VERSION ""

NS_ :

BS_:

BU_: SteeringControlModule SteeringController SteeringColumnUnit RearAxleSteeringController Engine ChassisController
VAL_TABLE_ JogSteerStates 15 "UNAVAILABLE" 14 "Reserved" 13 "Reserved" 12 "Reserved" 11 "Reserved" 10 "Reserved" 9 "Reserved" 8 "Reserved" 7 "Reserved" 6 "Reserved" 5 "Reserved" 4 "Reserved" 3 "Clear Jog" 2 "Jog Right" 1 "Jog Left" 0 "NONE" ;
VAL_TABLE_ SteerMode 15 "UNAVAILABLE" 14 "Reserved" 13 "Reserved" 12 "Reserved" 11 "Reserved" 10 "Reserved" 9 "Reserved" 8 "Reserved" 7 "Reserved" 6 "Reserved" 5 "Reserved" 4 "Crab Steer" 3 "4 Wheel Steer" 2 "Auto 4 Wheel Steer" 1 "2 Wheel Steer" 0 "OFF" ;
VAL_TABLE_ FMI 31 "Not available" 19 "Received network data in error" 18 "Below normal (moderately severe)" 17 "Below normal (least severe)" 16 "Above normal (moderately severe)" 15 "Above normal (least severe)" 14 "Special intstructions" 13 "Out of calibration" 12 "Bad intelligent device" 11 "Root cause not known" 10 "Abnormal rate of change" 9 "Abnormal update rate" 8 "Abnormal frequency" 7 "Mechanical system not responding" 6 "Current above normal" 5 "Current below normal" 4 "Voltage below normal" 3 "Voltage above normal" 2 "Data erratic" 1 "Below normal (most severe)" 0 "Above normal (most severe)" ;

BO_ 3221225472 VECTOR__INDEPENDENT_SIG_MSG: 0 Vector__XXX
 SG_ ManufacturerSpecific8 : 0|8@1+ (1,0) [0|255] "" Vector__XXX
 SG_ ManufacturerSpecific7 : 0|8@1+ (1,0) [0|255] "" Vector__XXX
 SG_ ManufacturerSpecific6 : 0|8@1+ (1,0) [0|255] "" Vector__XXX
 SG_ ManufacturerSpecific5 : 0|8@1+ (1,0) [0|255] "" Vector__XXX
 SG_ ManufacturerSpecific4 : 0|8@1+ (1,0) [0|255] "" Vector__XXX
 SG_ ManufacturerSpecific3 : 0|8@1+ (1,0) [0|255] "" Vector__XXX
 SG_ CabNoiseCtrlTuningCmd : 0|3@1+ (1,0) [0|7] "" Vector__XXX
 SG_ CabNoiseCtrlCmd : 0|2@1+ (1,0) [0|3] "" Vector__XXX
 SG_ MagnetGeneratorCtrl : 0|2@1+ (1,0) [0|3] "" Vector__XXX
 SG_ SpecialIgnitorLoop62Resistance : 0|16@1+ (0.1,0) [0|6425.5] "ohm" Vector__XXX
 SG_ EngExhstBckPressRegulatorCtrlCmd : 0|16@1+ (0.0025,0) [0|160.6375] "%" Vector__XXX
 SG_ EngExhaustBackPressActuator1Temp : 0|8@1+ (1,-40) [-40|210] "deg C" Vector__XXX
 SG_ EngExhstBckPrssActtor1DesiredPos : 0|8@1+ (0.4,0) [0|100] "%" Vector__XXX
 SG_ EngTurboWastegateActuator1Temp : 0|8@1+ (1,-40) [-40|210] "deg C" Vector__XXX
 SG_ EngExhstBckPrssRgltrCtrlOprtnStt : 0|4@1+ (1,0) [0|15] "" Vector__XXX
 SG_ EngExhstBckPrssRglatorTempStatus : 0|3@1+ (1,0) [0|7] "" Vector__XXX
 SG_ EngExhstBckPrssRgltrPrlminaryFMI : 0|5@1+ (1,0) [0|31] "" Vector__XXX
 SG_ EngExhaustBackPressRegulatorPos : 0|8@1+ (0.4,0) [0|100] "%" Vector__XXX
 SG_ EngTrbCmprssrBypassActuator2Temp : 0|8@1+ (1,-40) [-40|210] "deg C" Vector__XXX
 SG_ EngTrbCmprssrBypassActuator1Temp : 0|8@1+ (1,-40) [-40|210] "deg C" Vector__XXX
 SG_ EngCoolantPress2 : 0|8@1+ (2,0) [0|500] "kPa" Vector__XXX
 SG_ EngExhstGsRcrcltn2Valve2PosError : 0|16@1+ (0.004,-125) [-125|132.02] "%" Vector__XXX
 SG_ EngExhstGsRcrcltn2Valve1PosError : 0|16@1+ (0.004,-125) [-125|132.02] "%" Vector__XXX
 SG_ DslPrtcltFltr1CndtnsNtMtFrActvRg : 0|2@1+ (1,0) [0|3] "" Vector__XXX
 SG_ DslPrtcltFltrActvRgnrtnInhbt5629 : 0|2@1+ (1,0) [0|3] "" Vector__XXX
 SG_ HydrocarbonDoserPurgingEnable : 0|2@1+ (1,0) [0|3] "" Vector__XXX
 SG_ DslPrtcltFltrActvRgnrtnInhbt3717 : 0|2@1+ (1,0) [0|3] "" Vector__XXX
 SG_ DslPrtcltFltrActvRgnrtnInhbtdDTE : 0|2@1+ (1,0) [0|3] "" Vector__XXX
 SG_ DslPrtcltFltrActvRgnrtnInhbt3715 : 0|2@1+ (1,0) [0|3] "" Vector__XXX
 SG_ DslPrtcltFltrActvRgnrtnInhbt3713 : 0|2@1+ (1,0) [0|3] "" Vector__XXX
 SG_ DslPrtcltFltrActvRgnrtnInhbt3712 : 0|2@1+ (1,0) [0|3] "" Vector__XXX
 SG_ DslPrtcltFltrActvRgnrtnInhbt3710 : 0|2@1+ (1,0) [0|3] "" Vector__XXX
 SG_ DslPrtcltFltrActvRgnrtnInhbtdDTV : 0|2@1+ (1,0) [0|3] "" Vector__XXX
 SG_ DslPrtcltFltrActvRgnrtnInhbtdDTO : 0|2@1+ (1,0) [0|3] "" Vector__XXX
 SG_ DslPrtcltFltr2StSnsrECUIntrnlTmp : 0|8@1+ (1,-40) [-40|210] "deg C" Vector__XXX
 SG_ DslPrtcltFltr1StSnsrECUIntrnlTmp : 0|8@1+ (1,-40) [-40|210] "deg C" Vector__XXX
 SG_ Aftrtrtmnt1SCROprtrIndcmntActvTr : 0|16@1+ (1,0) [0|64255] "km" Vector__XXX
 SG_ Aftrtrtmnt1SCRCnvrsionEfficiency : 0|8@1+ (0.4,0) [0|100] "%" Vector__XXX
 SG_ Aftrtrtmnt1CmmnddDslExhstFldCnsm : 0|16@1+ (0.05,0) [0|3212.75] "L/h" Vector__XXX
 SG_ Aftrtrtmnt1DslExhstFldAvrgCnsmpt : 0|16@1+ (0.05,0) [0|3212.75] "L/h" Vector__XXX
 SG_ TransOilLevel2MeasurementStatus : 0|4@1+ (1,0) [0|15] "" Vector__XXX
 SG_ TransOilLevel2CountdownTimer : 0|4@1+ (1,0) [0|15] "" Vector__XXX
 SG_ TransOilLevel2High_Low : 0|8@1+ (0.5,-62.5) [-62.5|62.5] "L" Vector__XXX
 SG_ TransOilTemp2 : 0|16@1+ (0.03125,-273) [-273|1734.96875] "deg C" Vector__XXX
 SG_ EngIntakeManifold1AbsPress4817 : 0|16@1+ (0.1,0) [0|6425.5] "kPa" Vector__XXX
 SG_ FuelEnergyContent : 0|16@1+ (0.00390625,0) [0|250.996] "MJ/Nm^3" Vector__XXX
 SG_ ReferenceEngGasMassFlowRate : 0|16@1+ (0.05,0) [0|3212.75] "kg/h" Vector__XXX
 SG_ Aftrtrtmnt1DslExhstFluidProperty : 0|4@1+ (1,0) [0|15] "" Vector__XXX
 SG_ Aftrtrtmnt1DslExhstFldCndctivity : 0|8@1+ (5,0) [0|1250] "microSiemens/mm" Vector__XXX
 SG_ Aftrtrtmnt1DslExhstFldCncntrtion : 0|8@1+ (0.25,0) [0|62.5] "%" Vector__XXX
 SG_ Aftrtrtmnt1DselExhaustFluidTemp2 : 0|8@1+ (1,-40) [-40|210] "deg C" Vector__XXX
 SG_ DataSecurityParameter : 0|8@1- (1,0) [0|1785] "" Vector__XXX
 SG_ TrailerVDCActive : 0|2@1+ (1,0) [0|3] "" Vector__XXX
 SG_ TransLoadReductionInhibitRq : 0|2@1+ (1,0) [0|3] "" Vector__XXX
 SG_ ClntLvlEngPrtctionShutdownStatus : 0|2@1+ (1,0) [0|3] "" Vector__XXX
 SG_ ServiceComponentIdentificatio913 : 0|8@1+ (1,0) [0|250] "ID" Vector__XXX
 SG_ ServiceComponentIdentificatio912 : 0|8@1+ (1,0) [0|250] "ID" Vector__XXX
 SG_ EngThrottleValveDiffPress : 0|16@1+ (0.1,0) [0|6425.5] "kPa" Vector__XXX
 SG_ EngFuelCtrlCtrlMode : 0|2@1+ (1,0) [0|3] "" Vector__XXX
 SG_ EmergencyBrakingActive : 0|2@1+ (1,0) [0|3] "" Vector__XXX
 SG_ EngExRangeCoolantPress : 0|8@1+ (4,0) [0|1000] "kPa" Vector__XXX
 SG_ EngCldStrtFlIgniterRelayFeedback : 0|2@1+ (1,0) [0|3] "" Vector__XXX
 SG_ EngColdStartFuelIgniterRelay : 0|2@1+ (1,0) [0|3] "" Vector__XXX
 SG_ EngColdStartFuelIgniterCmd : 0|8@1+ (0.4,0) [0|100] "%" Vector__XXX
 SG_ ParkBrakeCmd : 0|2@1+ (1,0) [0|3] "" Vector__XXX
 SG_ SwtchBcklghtIllmntnBrghtnssPrcnt : 0|8@1+ (0.4,0) [0|100] "%" Vector__XXX
 SG_ Aftrtrtmnt2ThrWyCtlytcCnvrtr4300 : 0|5@1+ (1,0) [0|31] "" Vector__XXX
 SG_ Aftrtrtmnt2ThrWyCtlytcCnvrtr4299 : 0|5@1+ (1,0) [0|31] "" Vector__XXX
 SG_ Aftrtrtmnt2ThrWyCtlytcCnvrtr4298 : 0|5@1+ (1,0) [0|31] "" Vector__XXX
 SG_ NOxSnsrATO2SlfdgnosisFinalResult : 0|8@1+ (1,0) [0|250] "" Vector__XXX
 SG_ Aftrtrtmnt2OtltGsNOxSnsrCrrc5049 : 0|8@1+ (0.5,0) [0|125] "%/bar" Vector__XXX
 SG_ NOxSnsrATO2OperationHoursCounter : 0|16@1+ (1,0) [0|64255] "h" Vector__XXX
 SG_ Aftrtrtmnt2OtltGsNOxSnsrNwPr5047 : 0|8@1+ (1,-125) [-125|125] "ppm" Vector__XXX
 SG_ NOxSnsrATI2SlfdgnosisFinalResult : 0|8@1+ (1,0) [0|250] "" Vector__XXX
 SG_ Aftrtrtmnt2IntkGsNOxSnsrCrrc5042 : 0|8@1+ (0.5,0) [0|125] "%/bar" Vector__XXX
 SG_ NOxSnsrATI2OperationHoursCounter : 0|16@1+ (1,0) [0|64255] "h" Vector__XXX
 SG_ Aftrtrtmnt2IntkGsNOxSnsrNwPr5040 : 0|8@1+ (1,-125) [-125|125] "ppm" Vector__XXX
 SG_ Aftrtrtmnt1ThrWyCtlytcCnvrtr4294 : 0|5@1+ (1,0) [0|31] "" Vector__XXX
 SG_ Aftrtrtmnt1ThrWyCtlytcCnvrtr4293 : 0|5@1+ (1,0) [0|31] "" Vector__XXX
 SG_ Aftrtrtmnt1ThrWyCtlytcCnvrtr4292 : 0|5@1+ (1,0) [0|31] "" Vector__XXX
 SG_ Aftrtrtmnt1DslExhstFldTankHeater : 0|8@1+ (0.4,0) [0|100] "%" Vector__XXX
 SG_ Aftrtrtmnt1DslExhstFldTnkLvlPrlm : 0|5@1+ (1,0) [0|31] "" Vector__XXX
 SG_ Aftrtrtmnt1DslExhstFldTankLevel2 : 0|16@1+ (0.1,0) [0|6425.5] "mm" Vector__XXX
 SG_ Aftrtrtmnt1DslExhstFluidTankTemp : 0|8@1+ (1,-40) [-40|210] "deg C" Vector__XXX
 SG_ Aftrtrtmnt1DslExhstFlidTankLevel : 0|8@1+ (0.4,0) [0|100] "%" Vector__XXX
 SG_ NOxSnsrATO1SlfdgnosisFinalResult : 0|8@1+ (1,0) [0|250] "" Vector__XXX
 SG_ Aftrtrtmnt1OtltGsNOxSnsrCrrc5035 : 0|8@1+ (0.5,0) [0|125] "%/bar" Vector__XXX
 SG_ NOxSnsrATO1OperationHoursCounter : 0|16@1+ (1,0) [0|64255] "h" Vector__XXX
 SG_ Aftrtrtmnt1OtltGsNOxSnsrNwPr5033 : 0|8@1+ (1,-125) [-125|125] "ppm" Vector__XXX
 SG_ NOxSnsrATI1SlfdgnosisFinalResult : 0|8@1+ (1,0) [0|250] "" Vector__XXX
 SG_ Aftrtrtmnt1IntkGsNOxSnsrCrrc5028 : 0|8@1+ (0.5,0) [0|125] "%/bar" Vector__XXX
 SG_ NOxSnsrATI1OperationHoursCounter : 0|16@1+ (1,0) [0|64255] "h" Vector__XXX
 SG_ Aftrtrtmnt1IntkGsNOxSnsrNwPr5026 : 0|8@1+ (1,-125) [-125|125] "ppm" Vector__XXX
 SG_ Armrest2Switch2 : 0|2@1+ (1,0) [0|3] "" Vector__XXX
 SG_ Armrest2Switch1 : 0|2@1+ (1,0) [0|3] "" Vector__XXX
 SG_ Armrest1Switch2 : 0|2@1+ (1,0) [0|3] "" Vector__XXX
 SG_ Armrest1Switch1 : 0|2@1+ (1,0) [0|3] "" Vector__XXX
 SG_ Aftrtrtmnt2SCRCnvrsionEfficiency : 0|8@1+ (0.4,0) [0|100] "%" Vector__XXX
 SG_ Aftrtrtmnt2SCRCmmnddCtlystDslExh : 0|16@1+ (0.05,0) [0|3212.75] "L/h" Vector__XXX
 SG_ Aftrtrtmnt2DslExhstFldAvrgCnsmpt : 0|16@1+ (0.05,0) [0|3212.75] "L/h" Vector__XXX
 SG_ Aftrtrtmnt2DslExhstFldTnk2HtrPrl : 0|5@1+ (1,0) [0|31] "" Vector__XXX
 SG_ Aftrtrtmnt2DslExhstFldTnk2Heater : 0|4@1+ (1,0) [0|15] "" Vector__XXX
 SG_ Aftrtrtmnt2DslExhstFldTnk2TmpPrl : 0|5@1+ (1,0) [0|31] "" Vector__XXX
 SG_ Aftrtrtmnt2DslExhstFldTnk2LvlPrl : 0|5@1+ (1,0) [0|31] "" Vector__XXX
 SG_ Aftrtrtmnt2DslExhstFldTnk2Level2 : 0|16@1+ (0.1,0) [0|6425.5] "mm" Vector__XXX
 SG_ Aftrtrtmnt2DslExhstFlidTank2Temp : 0|8@1+ (1,-40) [-40|210] "deg C" Vector__XXX
 SG_ Aftrtrtmnt2DslExhstFldTank2Level : 0|8@1+ (0.4,0) [0|100] "%" Vector__XXX
 SG_ Aftrtrtmnt2DslExhstFldTnk1HtrPrl : 0|5@1+ (1,0) [0|31] "" Vector__XXX
 SG_ Aftrtrtmnt2DslExhstFldTankHeater : 0|8@1+ (0.4,0) [0|100] "%" Vector__XXX
 SG_ Aftrtrtmnt2DslExhstFldTnk1TmpPrl : 0|5@1+ (1,0) [0|31] "" Vector__XXX
 SG_ Aftrtrtmnt2DslExhstFldTnkLvlPrlm : 0|5@1+ (1,0) [0|31] "" Vector__XXX
 SG_ Aftrtrtmnt2DslExhstFldTankLevel2 : 0|16@1+ (0.1,0) [0|6425.5] "mm" Vector__XXX
 SG_ Aftrtrtmnt2DslExhstFluidTankTemp : 0|8@1+ (1,-40) [-40|210] "deg C" Vector__XXX
 SG_ Aftrtrtmnt2DslExhstFlidTankLevel : 0|8@1+ (0.4,0) [0|100] "%" Vector__XXX
 SG_ Aftrtrtmnt2DslExhstFldTnkDrnVlvC : 0|8@1+ (0.4,0) [0|100] "%" Vector__XXX
 SG_ Aftrtrtmnt2DslExhstFlidPumpState : 0|2@1+ (1,0) [0|3] "" Vector__XXX
 SG_ Aftrtrtmnt2DslExhstFldTnkFllVlvC : 0|8@1+ (0.4,0) [0|100] "%" Vector__XXX
 SG_ Aftrtrtmnt2DslExhstFldRturnValve : 0|8@1+ (0.4,0) [0|100] "%" Vector__XXX
 SG_ Aftrtrtmnt2DslExhstFldPmpDrvPrcn : 0|8@1+ (0.4,0) [0|100] "%" Vector__XXX
 SG_ Aftrtrtmnt2DslExhstFldPmpMtrSped : 0|16@1+ (0.5,0) [0|32127.5] "rpm" Vector__XXX
 SG_ Aftrtrtmnt2DeselExhaustFluidType : 0|4@1+ (1,0) [0|15] "" Vector__XXX
 SG_ Aftrtrtmnt2DslExhstFldCndctivity : 0|8@1+ (5,0) [0|1250] "microSiemens/mm" Vector__XXX
 SG_ Aftrtrtmnt2DslExhstFldCncntrtion : 0|8@1+ (0.25,0) [0|62.5] "%" Vector__XXX
 SG_ Aftrtrtmnt2DselExhaustFluidTemp2 : 0|8@1+ (1,-40) [-40|210] "deg C" Vector__XXX
 SG_ Aftrtrtmnt2SCRExhstGsDffPrssPrlm : 0|5@1+ (1,0) [0|31] "" Vector__XXX
 SG_ Aftrtrtmnt2SCRExhustGasDiffPress : 0|16@1+ (0.1,0) [0|6425.5] "kPa" Vector__XXX
 SG_ Aftrtrtmnt2DslExhstFldTnk2HtrCmd : 0|8@1+ (0.4,0) [0|100] "%" Vector__XXX
 SG_ Aftrtrtmnt2DslExhstFldTnkHterCmd : 0|8@1+ (0.4,0) [0|100] "%" Vector__XXX
 SG_ Aftrtrtmnt2DslExhstFldLneHeater4 : 0|2@1+ (1,0) [0|3] "" Vector__XXX
 SG_ Aftrtrtmnt2DslExhstFldLneHeater3 : 0|2@1+ (1,0) [0|3] "" Vector__XXX
 SG_ Aftrtrtmnt2DslExhstFldLneHeater2 : 0|2@1+ (1,0) [0|3] "" Vector__XXX
 SG_ Aftrtrtmnt2DslExhstFldLneHeater1 : 0|2@1+ (1,0) [0|3] "" Vector__XXX
 SG_ Aftrtrtmnt2DslExhstFldDsrHtngMdR : 0|3@1+ (1,0) [0|7] "" Vector__XXX
 SG_ Aftrtrtmnt2DslExhstFldDsrFltSppr : 0|2@1+ (1,0) [0|3] "" Vector__XXX
 SG_ Aftrtrtmnt2DslExhstFldRqstdQntty : 0|16@1+ (0.1,0) [0|6425.5] "g" Vector__XXX
 SG_ Aftrtrtmnt2DslExhstFldDsngRqstdQ : 0|16@1+ (0.3,0) [0|19276.5] "g/h" Vector__XXX
 SG_ Aftrtrtmnt2DslExhstFldLnHtr4Prlm : 0|5@1+ (1,0) [0|31] "" Vector__XXX
 SG_ Aftrtrtmnt2DslExhstFldLnHtr4Stte : 0|2@1+ (1,0) [0|3] "" Vector__XXX
 SG_ Aftrtrtmnt2DslExhstFldLnHtr3Prlm : 0|5@1+ (1,0) [0|31] "" Vector__XXX
 SG_ Aftrtrtmnt2DslExhstFldLnHtr3Stte : 0|2@1+ (1,0) [0|3] "" Vector__XXX
 SG_ Aftrtrtmnt2DslExhstFldLnHtr2Prlm : 0|5@1+ (1,0) [0|31] "" Vector__XXX
 SG_ Aftrtrtmnt2DslExhstFldLnHtr2Stte : 0|2@1+ (1,0) [0|3] "" Vector__XXX
 SG_ Aftrtrtmnt2DslExhstFldLnHtr1Prlm : 0|5@1+ (1,0) [0|31] "" Vector__XXX
 SG_ Aftrtrtmnt2DslExhstFldLnHtr1Stte : 0|2@1+ (1,0) [0|3] "" Vector__XXX
 SG_ Aftrtrtmnt2DslExhstFldDosingTemp : 0|8@1+ (1,-40) [-40|210] "deg C" Vector__XXX
 SG_ Aftrtrtmnt2DslExhstFldDsngAbsPrs : 0|8@1+ (8,0) [0|2000] "kPa" Vector__XXX
 SG_ Aftrtrtmnt2DslExhstFldActlQnttyO : 0|16@1+ (0.1,0) [0|6425.5] "g" Vector__XXX
 SG_ Aftrtrtmnt2DslExhstFldActlDsngQn : 0|16@1+ (0.3,0) [0|19276.5] "g/h" Vector__XXX
 SG_ Aftrtrtmnt2GsOxdtnCtlystOtlt4763 : 0|5@1+ (1,0) [0|31] "" Vector__XXX
 SG_ Aftrtrtmnt2GsOxdtnCtlystIntk4762 : 0|5@1+ (1,0) [0|31] "" Vector__XXX
 SG_ Aftrtrtmnt2DslOxdtnCtlystDff4776 : 0|5@1+ (1,0) [0|31] "" Vector__XXX
 SG_ Aftrtrtmnt2DslOxdtnCtlystOtl4775 : 0|5@1+ (1,0) [0|31] "" Vector__XXX
 SG_ Aftrtrtmnt2DslOxdtnCtlystInt4774 : 0|5@1+ (1,0) [0|31] "" Vector__XXX
 SG_ Aftrtrtmnt1DslExhstFldTnk2HtrPrl : 0|5@1+ (1,0) [0|31] "" Vector__XXX
 SG_ Aftrtrtmnt1DslExhstFldTnk2Heater : 0|8@1+ (0.4,0) [0|100] "%" Vector__XXX
 SG_ Aftrtrtmnt1DslExhstFldTnk2TmpPrl : 0|5@1+ (1,0) [0|31] "" Vector__XXX
 SG_ Aftrtrtmnt1DslExhstFldTnk2LvlPrl : 0|5@1+ (1,0) [0|31] "" Vector__XXX
 SG_ Aftrtrtmnt1DslExhstFldTnk2Level2 : 0|16@1+ (0.1,0) [0|6425.5] "mm" Vector__XXX
 SG_ Aftrtrtmnt1DslExhstFlidTank2Temp : 0|8@1+ (1,-40) [-40|210] "deg C" Vector__XXX
 SG_ Aftrtrtmnt1DslExhstFldTank2Level : 0|8@1+ (0.4,0) [0|100] "%" Vector__XXX
 SG_ Aftrtrtmnt1DslExhstFldTnkDrnVlvC : 0|8@1+ (0.4,0) [0|100] "%" Vector__XXX
 SG_ Aftrtrtmnt1DslExhstFlidPumpState : 0|2@1+ (1,0) [0|3] "" Vector__XXX
 SG_ Aftrtrtmnt1DslExhstFldTnkFllVlvC : 0|8@1+ (0.4,0) [0|100] "%" Vector__XXX
 SG_ Aftrtrtmnt1DslExhstFldRturnValve : 0|8@1+ (0.4,0) [0|100] "%" Vector__XXX
 SG_ Aftrtrtmnt1DslExhstFldPmpDrvPrcn : 0|8@1+ (0.4,0) [0|100] "%" Vector__XXX
 SG_ Aftrtrtmnt1DslExhstFldPmpMtrSped : 0|16@1+ (0.5,0) [0|32127.5] "rpm" Vector__XXX
 SG_ Aftrtrtmnt1SCRExhstGsDffPrssPrlm : 0|5@1+ (1,0) [0|31] "" Vector__XXX
 SG_ Aftrtrtmnt1SCRExhustGasDiffPress : 0|16@1+ (0.1,0) [0|6425.5] "kPa" Vector__XXX
 SG_ Aftrtrtmnt1DslExhstFldPmpHterCmd : 0|8@1+ (0.4,0) [0|100] "%" Vector__XXX
 SG_ Aftrtrtmnt1DslExhstFldTnk2HtrCmd : 0|8@1+ (0.4,0) [0|100] "%" Vector__XXX
 SG_ Aftrtrtmnt1DslExhstFldTnkHterCmd : 0|8@1+ (0.4,0) [0|100] "%" Vector__XXX
 SG_ Aftrtrtmnt1DslExhstFldLneHeater4 : 0|2@1+ (1,0) [0|3] "" Vector__XXX
 SG_ Aftrtrtmnt1DslExhstFldLneHeater3 : 0|2@1+ (1,0) [0|3] "" Vector__XXX
 SG_ Aftrtrtmnt1DslExhstFldLneHeater2 : 0|2@1+ (1,0) [0|3] "" Vector__XXX
 SG_ Aftrtrtmnt1DslExhstFldLneHeater1 : 0|2@1+ (1,0) [0|3] "" Vector__XXX
 SG_ Aftrtrtmnt1DslExhstFldDsrHtngMdR : 0|3@1+ (1,0) [0|7] "" Vector__XXX
 SG_ Aftrtrtmnt1DslExhstFldDsrFltSppr : 0|2@1+ (1,0) [0|3] "" Vector__XXX
 SG_ Aftrtrtmnt1DslExhstFldRqstdQntty : 0|16@1+ (0.1,0) [0|6425.5] "g" Vector__XXX
 SG_ Aftrtrtmnt1DslExhstFldDsngRqstdQ : 0|16@1+ (0.3,0) [0|19276.5] "g/h" Vector__XXX
 SG_ Aftrtrtmnt1DslExhstFldLnHtr4Prlm : 0|5@1+ (1,0) [0|31] "" Vector__XXX
 SG_ Aftrtrtmnt1DslExhstFldLnHtr4Stte : 0|2@1+ (1,0) [0|3] "" Vector__XXX
 SG_ Aftrtrtmnt1DslExhstFldLnHtr3Prlm : 0|5@1+ (1,0) [0|31] "" Vector__XXX
 SG_ Aftrtrtmnt1DslExhstFldLnHtr3Stte : 0|2@1+ (1,0) [0|3] "" Vector__XXX
 SG_ Aftrtrtmnt1DslExhstFldLnHtr2Prlm : 0|5@1+ (1,0) [0|31] "" Vector__XXX
 SG_ Aftrtrtmnt1DslExhstFldLnHtr2Stte : 0|2@1+ (1,0) [0|3] "" Vector__XXX
 SG_ Aftrtrtmnt1DslExhstFldLnHtr1Prlm : 0|5@1+ (1,0) [0|31] "" Vector__XXX
 SG_ Aftrtrtmnt1DslExhstFldLnHtr1Stte : 0|2@1+ (1,0) [0|3] "" Vector__XXX
 SG_ Aftrtrtmnt1DslExhstFldDosingTemp : 0|8@1+ (1,-40) [-40|210] "deg C" Vector__XXX
 SG_ Aftrtrtmnt1DslExhstFldDsrAbsPrss : 0|8@1+ (8,0) [0|2000] "kPa" Vector__XXX
 SG_ Aftrtrtmnt1DslExhstFldActlQnttyO : 0|16@1+ (0.1,0) [0|6425.5] "g" Vector__XXX
 SG_ Aftrtrtmnt1DslExhstFldActlDsngQn : 0|16@1+ (0.3,0) [0|19276.5] "g/h" Vector__XXX
 SG_ Aftrtrtmnt1GsOxdtnCtlystOtlt4757 : 0|5@1+ (1,0) [0|31] "" Vector__XXX
 SG_ Aftrtrtmnt1GsOxdtnCtlystIntk4756 : 0|5@1+ (1,0) [0|31] "" Vector__XXX
 SG_ Aftrtrtmnt1DslOxdtnCtlystDff4770 : 0|5@1+ (1,0) [0|31] "" Vector__XXX
 SG_ Aftrtrtmnt1DslOxdtnCtlystOtl4769 : 0|5@1+ (1,0) [0|31] "" Vector__XXX
 SG_ Aftrtrtmnt1DslOxdtnCtlystInt4768 : 0|5@1+ (1,0) [0|31] "" Vector__XXX
 SG_ EngAxClerSupplyValve2ActuatorCmd : 0|8@1+ (0.4,0) [0|100] "%" Vector__XXX
 SG_ EngAxClerSupplyValve1ActuatorCmd : 0|8@1+ (0.4,0) [0|100] "%" Vector__XXX
 SG_ Aftrtrtmnt1AvrgDstncBtwnActvDPFR : 0|32@1+ (0.125,0) [0|526385151.9] "km" Vector__XXX
 SG_ NOxSensorATO1SelfdiagnosisStatus : 0|3@1+ (1,0) [0|7] "" Vector__XXX
 SG_ Aftrtrtmnt1DslPrtcltFltrIntk3244 : 0|5@1+ (1,0) [0|31] "" Vector__XXX
 SG_ Aftrtrtmnt1DslPrtcltFltrIntr3254 : 0|5@1+ (1,0) [0|31] "" Vector__XXX
 SG_ NOxSensorATI1SelfdiagnosisStatus : 0|3@1+ (1,0) [0|7] "" Vector__XXX
 SG_ Aftrtrtmnt2AvrgDstncBtwnActvDPFR : 0|32@1+ (0.125,0) [0|526385151.9] "km" Vector__XXX
 SG_ NOxSensorATO2SelfdiagnosisStatus : 0|3@1+ (1,0) [0|7] "" Vector__XXX
 SG_ Aftrtrtmnt2DslPrtcltFltrIntk3278 : 0|5@1+ (1,0) [0|31] "" Vector__XXX
 SG_ Aftrtrtmnt2DslPrtcltFltrIntr3288 : 0|5@1+ (1,0) [0|31] "" Vector__XXX
 SG_ NOxSensorATI2SelfdiagnosisStatus : 0|3@1+ (1,0) [0|7] "" Vector__XXX
 SG_ BarometricAbsPress : 0|16@1+ (0.1,0) [0|6425.5] "kPa" Vector__XXX
 SG_ CalculatedAmbientAirTemp : 0|16@1+ (0.03125,-273) [-273|1734.96875] "deg C" Vector__XXX
 SG_ MinutesAccumulatedMILActivated : 0|16@1+ (1,0) [0|64255] "mins" Vector__XXX
 SG_ ProprietaryNetwork2 : 0|2@1+ (1,0) [0|3] "" Vector__XXX
 SG_ ProprietaryNetwork1 : 0|2@1+ (1,0) [0|3] "" Vector__XXX
 SG_ AETCTorqueValue14 : 0|16@1+ (1,0) [0|65535] "Nm" Vector__XXX
 SG_ AETCTorqueValue13 : 0|16@1+ (1,0) [0|65535] "Nm" Vector__XXX
 SG_ AETCTorqueValue12 : 0|16@1+ (1,0) [0|65535] "Nm" Vector__XXX
 SG_ AETCTorqueValue11 : 0|16@1+ (1,0) [0|65535] "Nm" Vector__XXX
 SG_ AETCTorqueValue10 : 0|16@1+ (1,0) [0|65535] "Nm" Vector__XXX
 SG_ AETCTorqueValue09 : 0|16@1+ (1,0) [0|65535] "Nm" Vector__XXX
 SG_ AETCTorqueValue08 : 0|16@1+ (1,0) [0|65535] "Nm" Vector__XXX
 SG_ AETCTorqueValue07 : 0|16@1+ (1,0) [0|65535] "Nm" Vector__XXX
 SG_ AETCTorqueValue06 : 0|16@1+ (1,0) [0|65535] "Nm" Vector__XXX
 SG_ AETCTorqueValue05 : 0|16@1+ (1,0) [0|65535] "Nm" Vector__XXX
 SG_ AETCTorqueValue04 : 0|16@1+ (1,0) [0|65535] "Nm" Vector__XXX
 SG_ AETCTorqueValue03 : 0|16@1+ (1,0) [0|65535] "Nm" Vector__XXX
 SG_ AETCTorqueValue02 : 0|16@1+ (1,0) [0|65535] "Nm" Vector__XXX
 SG_ AETCTorqueValue01 : 0|16@1+ (1,0) [0|65535] "Nm" Vector__XXX
 SG_ AETCSpeedValue14 : 0|16@1+ (0.125,0) [0|8191.875] "rpm" Vector__XXX
 SG_ AETCSpeedValue13 : 0|16@1+ (0.125,0) [0|8191.875] "rpm" Vector__XXX
 SG_ AETCSpeedValue12 : 0|16@1+ (0.125,0) [0|8191.875] "rpm" Vector__XXX
 SG_ AETCSpeedValue11 : 0|16@1+ (0.125,0) [0|8191.875] "rpm" Vector__XXX
 SG_ AETCSpeedValue10 : 0|16@1+ (0.125,0) [0|8191.875] "rpm" Vector__XXX
 SG_ AETCSpeedValue09 : 0|16@1+ (0.125,0) [0|8191.875] "rpm" Vector__XXX
 SG_ AETCSpeedValue08 : 0|16@1+ (0.125,0) [0|8191.875] "rpm" Vector__XXX
 SG_ AETCSpeedValue07 : 0|16@1+ (0.125,0) [0|8191.875] "rpm" Vector__XXX
 SG_ AETCSpeedValue06 : 0|16@1+ (0.125,0) [0|8191.875] "rpm" Vector__XXX
 SG_ AETCSpeedValue05 : 0|16@1+ (0.125,0) [0|8191.875] "rpm" Vector__XXX
 SG_ AETCSpeedValue04 : 0|16@1+ (0.125,0) [0|8191.875] "rpm" Vector__XXX
 SG_ AETCSpeedValue03 : 0|16@1+ (0.125,0) [0|8191.875] "rpm" Vector__XXX
 SG_ AETCSpeedValue02 : 0|16@1+ (0.125,0) [0|8191.875] "rpm" Vector__XXX
 SG_ AETCSpeedValue01 : 0|16@1+ (0.125,0) [0|8191.875] "rpm" Vector__XXX
 SG_ AETCTorqueValue00 : 0|16@1+ (1,0) [0|65535] "Nm" Vector__XXX
 SG_ AETCSpeedValue00 : 0|16@1+ (0.125,0) [0|8191.875] "rpm" Vector__XXX
 SG_ TransOilLevel1MeasurementStatus : 0|4@1+ (1,0) [0|15] "" Vector__XXX
 SG_ TransOilLevel1CountdownTimer : 0|4@1+ (1,0) [0|15] "" Vector__XXX
 SG_ TransOilLevel1High_Low : 0|8@1+ (0.5,-62.5) [-62.5|62.5] "L" Vector__XXX
 SG_ TransOilTemp1 : 0|16@1+ (0.03125,-273) [-273|1734.96875] "deg C" Vector__XXX
 SG_ TransOilLevel1 : 0|8@1+ (0.4,0) [0|100] "%" Vector__XXX
 SG_ TrailerWeight : 0|16@1+ (2,0) [0|128510] "kg" Vector__XXX
 SG_ ReferenceTirePressSetting : 0|8@1+ (1,0) [0|2000] "kPa" Vector__XXX
 SG_ ReferenceTirePress : 0|8@1+ (1,0) [0|2000] "kPa" Vector__XXX
 SG_ TirePressThresholdDetection : 0|3@1+ (1,0) [0|7] "" Vector__XXX
 SG_ TireAirLeakageRate : 0|16@1+ (0.1,0) [0|6425.5] "Pa/s" Vector__XXX
 SG_ CTIWheelEndElectricalFault : 0|2@1+ (1,0) [0|3] "" Vector__XXX
 SG_ CTITireStatus : 0|2@1+ (1,0) [0|3] "" Vector__XXX
 SG_ CTIWheelSensorStatus : 0|2@1+ (1,0) [0|3] "" Vector__XXX
 SG_ TireTemp : 0|16@1+ (0.03125,-273) [-273|1734.96875] "deg C" Vector__XXX
 SG_ TirePress : 0|8@1+ (4,0) [0|1000] "kPa" Vector__XXX
 SG_ EngTurningGearEngaged : 0|2@1+ (1,0) [0|3] "" Vector__XXX
 SG_ InputObjectId : 0|16@1+ (1,0) [0|255] "" Vector__XXX
 SG_ KeyActivationCode : 0|8@1+ (1,0) [0|2] "" Vector__XXX
 SG_ ButtonActivationCode : 0|8@1+ (1,0) [0|2] "" Vector__XXX
 SG_ XPosition : 0|16@1+ (1,0) [0|65535] "" Vector__XXX
 SG_ VTSelectInputObjectID : 0|16@1+ (1,0) [0|65535] "" Vector__XXX
 SG_ VTEscObjectID : 0|16@1+ (1,0) [0|65535] "" Vector__XXX
 SG_ VTChangeNumericValueObjectID : 0|16@1+ (1,0) [0|65535] "" Vector__XXX
 SG_ VTChangeActiveMaskObjectID : 0|16@1+ (1,0) [0|65535] "" Vector__XXX
 SG_ VTChangeSoftKeyMaskParentID : 0|16@1+ (1,0) [0|65535] "" Vector__XXX
 SG_ AuxiliaryFunctionObjectID : 0|16@1+ (1,0) [0|65535] "" Vector__XXX
 SG_ InputStatusObjectId : 0|16@1+ (1,0) [0|255] "" Vector__XXX
 SG_ SelectInputObjectID : 0|16@1+ (1,0) [0|65535] "" Vector__XXX
 SG_ ObjectToSizeID : 0|16@1+ (1,0) [0|65535] "" Vector__XXX
 SG_ ObjectToChangeColourID : 0|16@1+ (1,0) [0|65535] "" Vector__XXX
 SG_ ObjectToChangeNumValueID : 0|16@1+ (1,0) [0|65535] "" Vector__XXX
 SG_ ObjectToChangeEndPointID : 0|16@1+ (1,0) [0|65535] "" Vector__XXX
 SG_ ObjectToChangeFontID : 0|16@1+ (1,0) [0|65535] "" Vector__XXX
 SG_ ObjectToChangeFillAttributesID : 0|16@1+ (1,0) [0|65535] "" Vector__XXX
 SG_ ObjectToChangeAttributeID : 0|16@1+ (1,0) [0|65535] "" Vector__XXX
 SG_ AlarmMaskObjectID : 0|16@1+ (1,0) [0|65535] "" Vector__XXX
 SG_ ListInputObjectID : 0|16@1+ (1,0) [0|65535] "" Vector__XXX
 SG_ PolygonObjectToChangeID : 0|16@1+ (1,0) [0|65535] "" Vector__XXX
 SG_ PolygonObjectToScaleID : 0|16@1+ (1,0) [0|65535] "" Vector__XXX
 SG_ GraphicsContextObjectID : 0|16@1+ (1,0) [0|65535] "" Vector__XXX
 SG_ ObjectToGetAttributeID : 0|16@1+ (1,0) [0|65535] "" Vector__XXX
 SG_ ColourMapObjectID : 0|16@1+ (1,0) [0|65535] "" Vector__XXX
 SG_ LockUnlockCommand : 0|8@1+ (1,0) [0|1] "" Vector__XXX
 SG_ MacroObjecID : 0|8@1+ (1,0) [0|255] "" Vector__XXX
 SG_ CodePlane : 0|8@1+ (1,0) [0|16] "" Vector__XXX
 SG_ KeyObjectID : 0|16@1+ (1,0) [0|65535] "" Vector__XXX
 SG_ ButtonObjectID : 0|16@1+ (1,0) [0|65535] "" Vector__XXX
 SG_ DataOrAlarmMaskObjectID : 0|16@1+ (1,0) [0|65535] "" Vector__XXX
 SG_ MemoryRequired : 0|32@1+ (1,0) [0|4294967295] "" Vector__XXX
 SG_ FirstWideChar : 0|16@1+ (1,0) [0|65535] "" Vector__XXX
 SG_ IdentityNumber : 0|21@1+ (1,0) [0|2097152] "" Vector__XXX
 SG_ Status_1 : 0|8@1+ (1,0) [0|1] "" Vector__XXX
 SG_ YPosition : 0|16@1+ (1,0) [0|65535] "" Vector__XXX
 SG_ VTSelectInputObjectStatus : 0|8@1+ (1,0) [0|1] "" Vector__XXX
 SG_ VTChangeSoftKeyMaskObjectID : 0|16@1+ (1,0) [0|65535] "" Vector__XXX
 SG_ AuxInputEnable : 0|8@1+ (1,0) [0|1] "" Vector__XXX
 SG_ ChangeChildPositionObjectID : 0|16@1+ (1,0) [0|65535] "" Vector__XXX
 SG_ NewBackgroundColour : 0|8@1+ (1,0) [0|255] "" Vector__XXX
 SG_ AttributeID : 0|8@1+ (1,0) [0|16777200] "" Vector__XXX
 SG_ NewPriority : 0|8@1+ (1,0) [0|255] "" Vector__XXX
 SG_ ListIndex : 0|8@1+ (1,0) [0|255] "" Vector__XXX
 SG_ ChangeChildLocationObjectID : 0|16@1+ (1,0) [0|65535] "" Vector__XXX
 SG_ NewWidthAttribute : 0|16@1+ (1,0) [0|65535] "" Vector__XXX
 SG_ SubCommandID : 0|8@1+ (1,0) [0|0] "" Vector__XXX
 SG_ Value1 : 0|16@1+ (1,0) [0|65535] "" Vector__XXX
 SG_ KeyObjectParentID : 0|16@1+ (1,0) [0|65535] "" Vector__XXX
 SG_ ButtonObjectParentID : 0|16@1+ (1,0) [0|65535] "" Vector__XXX
 SG_ VTChangeNumericValueValue : 0|32@1+ (1,0) [0|4294967295] "" Vector__XXX
 SG_ NewObjectID : 0|16@1+ (1,0) [0|65535] "" Vector__XXX
 SG_ LastWideChar : 0|16@1+ (1,0) [0|65535] "" Vector__XXX
 SG_ ManufacturerCode : 0|11@1+ (1,0) [0|2047] "" Vector__XXX
 SG_ TouchState : 0|8@1+ (1,0) [0|255] "" Vector__XXX
 SG_ NewHeigthAttribute : 0|16@1+ (1,0) [0|0] "" Vector__XXX
 SG_ Value2 : 0|16@1+ (1,0) [0|65535] "" Vector__XXX
 SG_ Status_2 : 0|8@1+ (1,0) [0|1] "" Vector__XXX
 SG_ SoftKeyCode : 0|8@1+ (1,0) [0|255] "" Vector__XXX
 SG_ ButtonKeyCode : 0|8@1+ (1,0) [0|255] "" Vector__XXX
 SG_ ECUInstance : 0|3@1+ (1,0) [0|7] "" Vector__XXX
 SG_ FunctionInstance : 0|5@1+ (1,0) [0|31] "" Vector__XXX
 SG_ OperatingState1 : 0|1@1+ (1,0) [0|1] "" Vector__XXX
 SG_ Function : 0|8@1+ (1,0) [0|255] "" Vector__XXX
 SG_ OperatingState2 : 0|1@1+ (1,0) [0|1] "" Vector__XXX
 SG_ VehicleSystem2 : 0|7@1+ (1,0) [0|127] "" Vector__XXX
 SG_ VehicleSystemInstance : 0|4@1+ (1,0) [0|15] "" Vector__XXX
 SG_ IndustryGroup : 0|3@1+ (1,0) [0|7] "" Vector__XXX
 SG_ ArbitraryAddressCapable : 0|1@1+ (1,0) [0|1] "" Vector__XXX
 SG_ ChangeChildPositionParentObjectI : 0|16@1+ (1,0) [0|65535] "" Vector__XXX
 SG_ ChangeChildLocationParentObjectI : 0|16@1+ (1,0) [0|65535] "" Vector__XXX
 SG_ VTFunctionECUtoVT : 0|8@1+ (1,0) [0|255] "" Vector__XXX
 SG_ ObjectId_1 : 0|16@1+ (1,0) [0|65535] "" Vector__XXX
 SG_ SourceAddressOfAuxiliaryInputDev : 0|8@1+ (1,0) [0|255] "" Vector__XXX
 SG_ InputObjectId : 0|16@1+ (1,0) [0|255] "" Vector__XXX
 SG_ KeyActivationCode : 0|8@1+ (1,0) [0|2] "" Vector__XXX
 SG_ ButtonActivationCode : 0|8@1+ (1,0) [0|2] "" Vector__XXX
 SG_ XPosition : 0|16@1+ (1,0) [0|65535] "" Vector__XXX
 SG_ VTSelectInputObjectID : 0|16@1+ (1,0) [0|65535] "" Vector__XXX
 SG_ VTEscObjectID : 0|16@1+ (1,0) [0|65535] "" Vector__XXX
 SG_ VTChangeNumericValueObjectID : 0|16@1+ (1,0) [0|65535] "" Vector__XXX
 SG_ VTChangeActiveMaskObjectID : 0|16@1+ (1,0) [0|65535] "" Vector__XXX
 SG_ VTChangeSoftKeyMaskParentID : 0|16@1+ (1,0) [0|65535] "" Vector__XXX
 SG_ ChangeChildPositionParentOb_0000 : 0|16@1+ (1,0) [0|65535] "" Vector__XXX
 SG_ ObjectPoolRecord : 0|56@1+ (1,0) [0|3338120000] "" Vector__XXX
 SG_ AuxiliaryFunctionObjectID : 0|16@1+ (1,0) [0|65535] "" Vector__XXX
 SG_ NumberOfInpuUnits : 0|8@1+ (1,0) [0|255] "" Vector__XXX
 SG_ AuxModelIdentification : 0|16@1+ (1,0) [0|65535] "" Vector__XXX
 SG_ InputStatusObjectId : 0|16@1+ (1,0) [0|255] "" Vector__XXX
 SG_ ObjectToShowHideID : 0|16@1+ (1,0) [0|65535] "" Vector__XXX
 SG_ ObjectoEnableDisbaleID : 0|16@1+ (1,0) [0|65535] "" Vector__XXX
 SG_ SelectInputObjectID : 0|16@1+ (1,0) [0|65535] "" Vector__XXX
 SG_ NumberOfRepetitions_Audio : 0|8@1+ (1,0) [0|255] "" Vector__XXX
 SG_ AudioVolume : 0|8@1+ (1,0) [0|100] "%" Vector__XXX
 SG_ ChangeChildLocationParentOb_0000 : 0|16@1+ (1,0) [0|65535] "" Vector__XXX
 SG_ ObjectToSizeID : 0|16@1+ (1,0) [0|65535] "" Vector__XXX
 SG_ ObjectToChangeColourID : 0|16@1+ (1,0) [0|65535] "" Vector__XXX
 SG_ ObjectToChangeNumValueID : 0|16@1+ (1,0) [0|65535] "" Vector__XXX
 SG_ ObjectToChangeEndPointID : 0|16@1+ (1,0) [0|65535] "" Vector__XXX
 SG_ ObjectToChangeFontID : 0|16@1+ (1,0) [0|65535] "" Vector__XXX
 SG_ ObjectToChangeLineAttributesID : 0|16@1+ (1,0) [0|65535] "" Vector__XXX
 SG_ ObjectToChangeFillAttributesID : 0|16@1+ (1,0) [0|65535] "" Vector__XXX
 SG_ WorkingSetObjectID : 0|16@1+ (1,0) [0|65535] "" Vector__XXX
 SG_ MaskType : 0|8@1+ (1,0) [0|255] "" Vector__XXX
 SG_ ObjectToChangeAttributeID : 0|16@1+ (1,0) [0|65535] "" Vector__XXX
 SG_ AlarmMaskObjectID : 0|16@1+ (1,0) [0|65535] "" Vector__XXX
 SG_ ListInputObjectID : 0|16@1+ (1,0) [0|65535] "" Vector__XXX
 SG_ ObjectToChangeStringValueID : 0|16@1+ (1,0) [0|65535] "" Vector__XXX
 SG_ ParentObjectID : 0|16@1+ (1,0) [0|65535] "" Vector__XXX
 SG_ ObjectToAssociateLabelWithID : 0|16@1+ (1,0) [0|65535] "" Vector__XXX
 SG_ PolygonObjectToChangeID : 0|16@1+ (1,0) [0|65535] "" Vector__XXX
 SG_ PolygonObjectToScaleID : 0|16@1+ (1,0) [0|65535] "" Vector__XXX
 SG_ GraphicsContextObjectID : 0|16@1+ (1,0) [0|65535] "" Vector__XXX
 SG_ ObjectToGetAttributeID : 0|16@1+ (1,0) [0|65535] "" Vector__XXX
 SG_ ColourMapObjectID : 0|16@1+ (1,0) [0|65535] "" Vector__XXX
 SG_ LockUnlockCommand : 0|8@1+ (1,0) [0|1] "" Vector__XXX
 SG_ MacroObjecID : 0|8@1+ (1,0) [0|255] "" Vector__XXX
 SG_ CodePlane : 0|8@1+ (1,0) [0|16] "" Vector__XXX
 SG_ VersionLabelToStore : 0|56@1+ (1,0) [0|3338120000] "" Vector__XXX
 SG_ VersionLabelToLoad : 0|56@1+ (1,0) [0|3338120000] "" Vector__XXX
 SG_ VersionLabelToDelete : 0|56@1+ (1,0) [0|3338120000] "" Vector__XXX
 SG_ WSMaintenanceInitiating : 0|1@1+ (1,0) [0|1] "" Vector__XXX
 SG_ AuxCapabilitiesRequestType : 0|8@1+ (1,0) [0|255] "" Vector__XXX
 SG_ OperationCode : 0|7@1+ (1,0) [0|127] "" Vector__XXX
 SG_ MacroObjectID_2 : 0|16@1+ (1,0) [0|65535] "" Vector__XXX
 SG_ ExtendedVersionLabelToStore : 0|256@1+ (1,0) [0|3338120000] "" Vector__XXX
 SG_ ExtendedVersionLabelToLoad : 0|256@1+ (1,0) [0|3338120000] "" Vector__XXX
 SG_ ExtendedVersionLabelToDelete : 0|256@1+ (1,0) [0|3338120000] "" Vector__XXX
 SG_ RValueSelector : 0|1@1+ (1,0) [0|1] "" Vector__XXX
 SG_ LeftObjectID : 0|16@1+ (1,0) [0|65535] "" Vector__XXX
 SG_ AuxiliaryInputNumber : 0|8@1+ (1,0) [0|255] "" Vector__XXX
 SG_ WSMaintenanceVersion : 0|8@1+ (1,0) [0|255] "" Vector__XXX
 SG_ KeyObjectID : 0|16@1+ (1,0) [0|65535] "" Vector__XXX
 SG_ ButtonObjectID : 0|16@1+ (1,0) [0|65535] "" Vector__XXX
 SG_ Frequency_Audio : 0|16@1+ (1,0) [0|65535] "hz" Vector__XXX
 SG_ DataOrAlarmMaskObjectID : 0|16@1+ (1,0) [0|65535] "" Vector__XXX
 SG_ ObjectIDOfDataMaskToLock : 0|16@1+ (1,0) [0|65535] "" Vector__XXX
 SG_ MemoryRequired : 0|32@1+ (1,0) [0|4294967295] "" Vector__XXX
 SG_ FirstWideChar : 0|16@1+ (1,0) [0|65535] "" Vector__XXX
 SG_ IdentityNumber : 0|21@1+ (1,0) [0|2097152] "" Vector__XXX
 SG_ Status_1 : 0|8@1+ (1,0) [0|1] "" Vector__XXX
 SG_ AuxiliaryFunctionID : 0|16@1+ (1,0) [0|65535] "" Vector__XXX
 SG_ YPosition : 0|16@1+ (1,0) [0|65535] "" Vector__XXX
 SG_ VTSelectInputObjectStatus : 0|8@1+ (1,0) [0|1] "" Vector__XXX
 SG_ VTChangeSoftKeyMaskObjectID : 0|16@1+ (1,0) [0|65535] "" Vector__XXX
 SG_ ObjectOfChangedStringValueID : 0|16@1+ (1,0) [0|65535] "" Vector__XXX
 SG_ AssignmentErrorNotAccepted : 0|1@1+ (1,0) [0|1] "" Vector__XXX
 SG_ AuxInputEnable : 0|8@1+ (1,0) [0|1] "" Vector__XXX
 SG_ ShowOrHide : 0|8@1+ (1,0) [0|1] "" Vector__XXX
 SG_ EnableOrDisable : 0|8@1+ (1,0) [0|1] "" Vector__XXX
 SG_ SetFocusOpenForEditing : 0|8@1+ (1,0) [0|255] "" Vector__XXX
 SG_ ChangeChildPositionObjectID : 0|16@1+ (1,0) [0|65535] "" Vector__XXX
 SG_ NewWidth : 0|16@1+ (1,0) [0|65535] "" Vector__XXX
 SG_ NewBackgroundColour : 0|8@1+ (1,0) [0|255] "" Vector__XXX
 SG_ Width : 0|16@1+ (1,0) [0|65535] "" Vector__XXX
 SG_ FontColour : 0|8@1+ (1,0) [0|255] "" Vector__XXX
 SG_ LineColour : 0|8@1+ (1,0) [0|255] "" Vector__XXX
 SG_ FillType : 0|8@1+ (1,0) [0|255] "" Vector__XXX
 SG_ NewActiveMaskObjectID : 0|16@1+ (1,0) [0|65535] "" Vector__XXX
 SG_ AttributeID : 0|8@1+ (1,0) [0|16777200] "" Vector__XXX
 SG_ NewPriority : 0|8@1+ (1,0) [0|255] "" Vector__XXX
 SG_ ListIndex : 0|8@1+ (1,0) [0|255] "" Vector__XXX
 SG_ ChangeChildLocationObjectID : 0|16@1+ (1,0) [0|65535] "" Vector__XXX
 SG_ StringVariableObjectID : 0|16@1+ (1,0) [0|65535] "" Vector__XXX
 SG_ IndexOfThePointToReplace : 0|8@1+ (1,0) [0|255] "" Vector__XXX
 SG_ NewWidthAttribute : 0|16@1+ (1,0) [0|65535] "" Vector__XXX
 SG_ SubCommandID : 0|8@1+ (1,0) [0|0] "" Vector__XXX
 SG_ AttributeIDToChange : 0|8@1+ (1,0) [0|0] "" Vector__XXX
 SG_ TotalNumberOfBytes : 0|16@1- (1,0) [0|0] "bytes" Vector__XXX
 SG_ Value1 : 0|16@1+ (1,0) [0|65535] "" Vector__XXX
 SG_ ObjectId_2 : 0|16@1+ (1,0) [0|65535] "" Vector__XXX
 SG_ KeyObjectParentID : 0|16@1+ (1,0) [0|65535] "" Vector__XXX
 SG_ ButtonObjectParentID : 0|16@1+ (1,0) [0|65535] "" Vector__XXX
 SG_ VTChangeNumericValueValue : 0|32@1+ (1,0) [0|4294967295] "" Vector__XXX
 SG_ AuxErrorInvalidInputID : 0|1@1+ (1,0) [0|1] "" Vector__XXX
 SG_ OnTimeDuration_Audio : 0|16@1+ (1,0) [0|65535] "ms" Vector__XXX
 SG_ NewValue : 0|32@1+ (1,0) [0|65535] "" Vector__XXX
 SG_ FontSize : 0|8@1+ (1,0) [0|255] "" Vector__XXX
 SG_ LineWidth : 0|8@1+ (1,0) [0|255] "" Vector__XXX
 SG_ FillColour : 0|8@1+ (1,0) [0|255] "" Vector__XXX
 SG_ NewSoftKeyMaskObjectID : 0|16@1+ (1,0) [0|65535] "" Vector__XXX
 SG_ NewAttributeValue : 0|32@1+ (1,0) [0|0] "" Vector__XXX
 SG_ NewObjectID : 0|16@1+ (1,0) [0|65535] "" Vector__XXX
 SG_ NewValueX : 0|16@1+ (1,0) [0|65535] "" Vector__XXX
 SG_ LockTimeout : 0|16@1+ (1,0) [0|65535] "" Vector__XXX
 SG_ LastWideChar : 0|16@1+ (1,0) [0|65535] "" Vector__XXX
 SG_ PictureGraphicsID_Viewport : 0|16@1+ (1,0) [0|65534] "" Vector__XXX
 SG_ PictureGraphicsID_Canvas : 0|16@1+ (1,0) [0|65534] "" Vector__XXX
 SG_ ObjectID : 0|16@1+ (1,0) [0|65534] "" Vector__XXX
 SG_ NewViewportWidth : 0|16@1+ (1,0) [0|65535] "" Vector__XXX
 SG_ ViewportX_PanZoom : 0|16@1- (1,0) [-32768|32767] "" Vector__XXX
 SG_ ZoomValue : 0|32@1- (1,0) [-32|32] "" Vector__XXX
 SG_ ViewportX : 0|16@1- (1,0) [-32768|32767] "" Vector__XXX
 SG_ TextOption : 0|8@1+ (1,0) [0|1] "" Vector__XXX
 SG_ NumberOfPoints : 0|8@1+ (1,0) [0|255] "" Vector__XXX
 SG_ EllipseWidth : 0|16@1+ (1,0) [0|65535] "" Vector__XXX
 SG_ RectangleWidth_Draw : 0|16@1+ (1,0) [0|65535] "" Vector__XXX
 SG_ EndPixelOffsetX : 0|16@1- (1,0) [-32768|32767] "" Vector__XXX
 SG_ PixelOffsetX : 0|16@1- (1,0) [-32768|32767] "" Vector__XXX
 SG_ RectangleHeight_Erase : 0|16@1+ (1,0) [0|65535] "" Vector__XXX
 SG_ RectangleWidth_Erase : 0|16@1+ (1,0) [0|65535] "" Vector__XXX
 SG_ FontAttributesObjectID : 0|16@1+ (1,0) [0|65535] "" Vector__XXX
 SG_ FillAttributesObjectID : 0|16@1+ (1,0) [0|65535] "" Vector__XXX
 SG_ LineAttributesObjectID : 0|16@1+ (1,0) [0|65535] "" Vector__XXX
 SG_ BackgroundColour : 0|8@1+ (1,0) [0|255] "" Vector__XXX
 SG_ ForegroundColour : 0|8@1+ (1,0) [0|255] "" Vector__XXX
 SG_ LeftAID : 0|8@1+ (1,0) [0|255] "" Vector__XXX
 SG_ ImmediateOperandValue : 0|32@1+ (1,0) [0|0] "" Vector__XXX
 SG_ RightObjectID : 0|16@1+ (1,0) [0|65535] "" Vector__XXX
 SG_ CursorOffsetX : 0|16@1- (1,0) [-32768|32767] "" Vector__XXX
 SG_ CursorPosX : 0|16@1- (1,0) [-32768|32767] "" Vector__XXX
 SG_ AuxErrorAnyOther : 0|1@1+ (1,0) [0|1] "" Vector__XXX
 SG_ ManufacturerCode : 0|11@1+ (1,0) [0|2047] "" Vector__XXX
 SG_ TextLength : 0|8@1+ (1,0) [0|255] "bytes" Vector__XXX
 SG_ TouchState : 0|8@1+ (1,0) [0|255] "" Vector__XXX
 SG_ XPosChangeTopLeft : 0|8@1+ (1,-127) [-127|128] "" Vector__XXX
 SG_ NewHeight : 0|16@1+ (1,0) [0|65535] "" Vector__XXX
 SG_ Height : 0|16@1+ (1,0) [0|65535] "" Vector__XXX
 SG_ LabelFontType : 0|8@1+ (1,0) [0|255] "" Vector__XXX
 SG_ LineArt : 0|16@1+ (1,0) [0|65535] "" Vector__XXX
 SG_ FillPatternObjectID : 0|16@1+ (1,0) [0|65535] "" Vector__XXX
 SG_ XPosChangeTopLeftLong : 0|16@1- (1,0) [-32768|32767] "" Vector__XXX
 SG_ FontType : 0|8@1+ (1,0) [0|255] "" Vector__XXX
 SG_ NewHeigthAttribute : 0|16@1+ (1,0) [0|0] "" Vector__XXX
 SG_ Value2 : 0|16@1+ (1,0) [0|65535] "" Vector__XXX
 SG_ NewStringValue : 0|16@1+ (1,0) [0|65535] "" Vector__XXX
 SG_ CursorPosY : 0|16@1- (1,0) [-32768|32767] "" Vector__XXX
 SG_ CursorOffsetY : 0|16@1- (1,0) [-32768|32767] "" Vector__XXX
 SG_ PixelOffsetY : 0|16@1- (1,0) [-32768|32767] "" Vector__XXX
 SG_ EndPixelOffsetY : 0|16@1- (1,0) [-32768|32767] "" Vector__XXX
 SG_ RectangleHeight_Draw : 0|16@1+ (1,0) [0|65535] "" Vector__XXX
 SG_ EllipseHeight : 0|16@1+ (1,0) [0|65535] "" Vector__XXX
 SG_ ViewportY : 0|16@1- (1,0) [-32768|32767] "" Vector__XXX
 SG_ ViewportY_PanZoom : 0|16@1- (1,0) [-32768|32767] "" Vector__XXX
 SG_ NewViewportHeight : 0|16@1+ (1,0) [0|65535] "" Vector__XXX
 SG_ Status_2 : 0|8@1+ (1,0) [0|1] "" Vector__XXX
 SG_ SoftKeyCode : 0|8@1+ (1,0) [0|255] "" Vector__XXX
 SG_ ButtonKeyCode : 0|8@1+ (1,0) [0|255] "" Vector__XXX
 SG_ OffTimeDuration_Audio : 0|16@1+ (1,0) [0|65535] "ms" Vector__XXX
 SG_ YPosChangeTopLeft : 0|8@1+ (1,-127) [-127|128] "" Vector__XXX
 SG_ FontStyle : 0|8@1+ (1,0) [0|255] "" Vector__XXX
 SG_ GraphicRepresentationObjectID : 0|16@1+ (1,0) [0|255] "" Vector__XXX
 SG_ NewValueY : 0|16@1+ (1,0) [0|65535] "" Vector__XXX
 SG_ ECUInstance : 0|3@1+ (1,0) [0|7] "" Vector__XXX
 SG_ FunctionInstance : 0|5@1+ (1,0) [0|31] "" Vector__XXX
 SG_ LineDirection : 0|8@1+ (1,0) [0|1] "" Vector__XXX
 SG_ YPosChangeTopLeftLong : 0|16@1- (1,0) [-32768|32767] "" Vector__XXX
 SG_ OperatingState1 : 0|1@1+ (1,0) [0|1] "" Vector__XXX
 SG_ Function : 0|8@1+ (1,0) [0|255] "" Vector__XXX
 SG_ RightAID : 0|8@1+ (1,0) [0|255] "" Vector__XXX
 SG_ OperatingState2 : 0|1@1+ (1,0) [0|1] "" Vector__XXX
 SG_ ZoomValue_PanZoom : 0|32@1- (1,0) [-32|32] "" Vector__XXX
 SG_ VehicleSystem2 : 0|7@1+ (1,0) [0|127] "" Vector__XXX
 SG_ VehicleSystemInstance : 0|4@1+ (1,0) [0|15] "" Vector__XXX
 SG_ NotificationValue1 : 0|16@1+ (1,0) [0|65535] "" Vector__XXX
 SG_ ThenMacroObjectID : 0|16@1+ (1,0) [0|65535] "" Vector__XXX
 SG_ IndustryGroup : 0|3@1+ (1,0) [0|7] "" Vector__XXX
 SG_ ArbitraryAddressCapable : 0|1@1+ (1,0) [0|1] "" Vector__XXX
 SG_ ModelIdentificationCode : 0|16@1+ (1,0) [0|65535] "" Vector__XXX
 SG_ NotificationValue2 : 0|16@1+ (1,0) [0|65535] "" Vector__XXX
 SG_ ElseMacroObjectID : 0|16@1+ (1,0) [0|65535] "" Vector__XXX
 SG_ NumOfPreferredFunctions : 0|8@1- (1,0) [0|255] "" Vector__XXX
 SG_ AuxiliaryFunctionID_1 : 0|16@1+ (1,0) [0|65535] "" Vector__XXX
 SG_ AuxiliaryInputID_1 : 0|16@1+ (1,0) [0|65535] "" Vector__XXX
 SG_ MessageChecksum : 0|4@1+ (1,0) [0|15] "" Vector__XXX
 SG_ MessageCounter : 0|4@1+ (1,0) [0|15] "" Vector__XXX
 SG_ EngRequestedTorqueHighResolution : 0|4@1+ (0.125,0) [0|0] "%" Vector__XXX
 SG_ TSC1CtrlPurpose : 0|5@1+ (1,0) [0|31] "" Vector__XXX
 SG_ TSC1TransRate : 0|3@1+ (1,0) [0|7] "" Vector__XXX
 SG_ EngRequestedTorque_TorqueLimit : 0|8@1+ (1,-125) [-125|125] "%" Vector__XXX
 SG_ EngRequestedSpeed_SpeedLimit : 0|16@1+ (0.125,0) [0|0] "rpm" Vector__XXX
 SG_ OverrideCtrlModePriority : 0|2@1+ (1,0) [0|3] "" Vector__XXX
 SG_ EngRequestedSpeedCtrlConditions : 0|2@1+ (1,0) [0|3] "" Vector__XXX
 SG_ EngOverrideCtrlMode : 0|2@1+ (1,0) [0|3] "" Vector__XXX
 SG_ TrackAdjustEnable : 0|2@1+ (1,0) [0|3] "" Vector__XXX
 SG_ JogSteerCommand : 0|4@1+ (1,0) [0|0] "" Vector__XXX
 SG_ RequestedSteerMode : 0|4@1+ (1,0) [0|0] "" Vector__XXX
 SG_ RearSteerSensorVoltage : 0|8@1+ (20,0) [0|0] "mV" Vector__XXX
 SG_ FrontSteerSensorVoltage : 0|8@1+ (20,0) [0|0] "mV" Vector__XXX
 SG_ JogAngle : 0|8@1+ (0.1,0) [0|0] "" Vector__XXX
 SG_ RearSteerAngle : 0|8@1+ (0.2,0) [0|0] "" Vector__XXX
 SG_ FrontSteerAngle : 0|8@1+ (0.2,0) [0|0] "Degrees" Vector__XXX
 SG_ ActualSteerMode : 0|4@1+ (1,0) [0|0] "" Vector__XXX
 SG_ BoomMotionUnlockButtonState : 0|2@1+ (1,0) [0|0] "" Vector__XXX
 SG_ AuxBPowerButtonState : 0|2@1+ (1,0) [0|0] "" Vector__XXX
 SG_ AuxAPowerButtonState : 0|2@1+ (1,0) [0|0] "" Vector__XXX
 SG_ BoomMotionLockButtonState : 0|2@1+ (1,0) [0|0] "" Vector__XXX
 SG_ RearRightTrackOutButtonStatus : 0|2@1+ (1,0) [0|3] "" Vector__XXX
 SG_ RearRightTrackInButtonStatus : 0|2@1+ (1,0) [0|3] "" Vector__XXX
 SG_ RearLeftTrackOutButtonStatus : 0|2@1+ (1,0) [0|3] "" Vector__XXX
 SG_ RearLeftTrackInButtonStatus : 0|2@1+ (1,0) [0|3] "" Vector__XXX
 SG_ FrontRightTrackOutButtonStatus : 0|2@1+ (1,0) [0|3] "" Vector__XXX
 SG_ FrontRightTrackInButtonStatus : 0|2@1+ (1,0) [0|3] "" Vector__XXX
 SG_ FrontLeftTrackOutButtonStatus : 0|2@1+ (1,0) [0|3] "" Vector__XXX
 SG_ FrontLeftTrackInButtonStatus : 0|2@1+ (1,0) [0|3] "" Vector__XXX

BO_ 2566838782 AUXIO1: 8 Vector__XXX
 SG_ AuxI_OChannel2 : 48|16@1+ (1,0) [0|64255] "counts" Vector__XXX
 SG_ AuxI_OChannel1 : 32|16@1+ (1,0) [0|64255] "counts" Vector__XXX
 SG_ AuxI_O13 : 30|2@1+ (1,0) [0|3] "" Vector__XXX
 SG_ AuxI_O14 : 28|2@1+ (1,0) [0|3] "" Vector__XXX
 SG_ AuxI_O15 : 26|2@1+ (1,0) [0|3] "" Vector__XXX
 SG_ AuxI_O16 : 24|2@1+ (1,0) [0|3] "" Vector__XXX
 SG_ AuxI_O09 : 22|2@1+ (1,0) [0|3] "" Vector__XXX
 SG_ AuxI_O10 : 20|2@1+ (1,0) [0|3] "" Vector__XXX
 SG_ AuxI_O11 : 18|2@1+ (1,0) [0|3] "" Vector__XXX
 SG_ AuxI_O12 : 16|2@1+ (1,0) [0|3] "" Vector__XXX
 SG_ AuxI_O05 : 14|2@1+ (1,0) [0|3] "" Vector__XXX
 SG_ AuxI_O06 : 12|2@1+ (1,0) [0|3] "" Vector__XXX
 SG_ AuxI_O07 : 10|2@1+ (1,0) [0|3] "" Vector__XXX
 SG_ AuxI_O08 : 8|2@1+ (1,0) [0|3] "" Vector__XXX
 SG_ AuxI_O01 : 6|2@1+ (1,0) [0|3] "" Vector__XXX
 SG_ AuxI_O02 : 4|2@1+ (1,0) [0|3] "" Vector__XXX
 SG_ AuxI_O03 : 2|2@1+ (1,0) [0|3] "" Vector__XXX
 SG_ AuxI_O04 : 0|2@1+ (1,0) [0|3] "" Vector__XXX

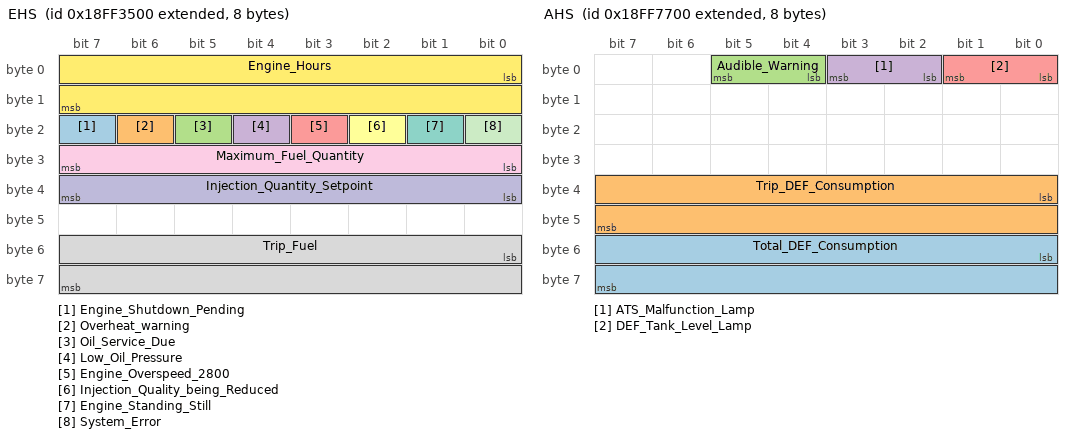
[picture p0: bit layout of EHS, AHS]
BO_ 2566862080 EHS: 8 Engine
 SG_ Engine_Shutdown_Pending : 23|1@1+ (1,0) [0|0] "" Vector__XXX
 SG_ Overheat_warning : 22|1@1+ (1,0) [0|0] "" Vector__XXX
 SG_ Oil_Service_Due : 21|1@1+ (1,0) [0|0] "" Vector__XXX
 SG_ Low_Oil_Pressure : 20|1@1+ (1,0) [0|0] "" Vector__XXX
 SG_ Engine_Overspeed_2800 : 19|1@1+ (1,0) [0|0] "" Vector__XXX
 SG_ Injection_Quality_being_Reduced : 18|1@1+ (1,0) [0|0] "" Vector__XXX
 SG_ Engine_Standing_Still : 17|1@1+ (1,0) [0|0] "" Vector__XXX
 SG_ Trip_Fuel : 48|16@1+ (0.05,0) [0|3276.75] "litre" Vector__XXX
 SG_ Maximum_Fuel_Quantity : 24|8@1+ (1,0) [0|0] "mg" Vector__XXX
 SG_ Injection_Quantity_Setpoint : 32|8@1+ (1,0) [0|0] "mg" Vector__XXX
 SG_ System_Error : 16|1@1+ (1,0) [0|0] "" Vector__XXX
 SG_ Engine_Hours : 0|16@1+ (1,0) [0|0] "Hours" Vector__XXX

BO_ 2566878976 AHS: 8 Engine
 SG_ Total_DEF_Consumption : 48|16@1+ (1,0) [0|65535] "L" Vector__XXX
 SG_ Trip_DEF_Consumption : 32|16@1+ (0.1,0) [0|6553] "L" Vector__XXX
 SG_ Audible_Warning : 4|2@1+ (1,0) [0|0] "" Vector__XXX
 SG_ ATS_Malfunction_Lamp : 2|2@1+ (1,0) [0|0] "" Vector__XXX
 SG_ DEF_Tank_Level_Lamp : 0|2@1+ (1,0) [0|3] "" Vector__XXX

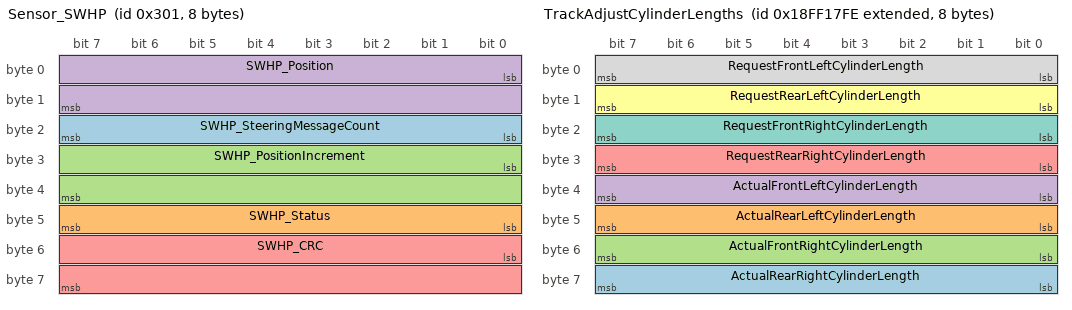
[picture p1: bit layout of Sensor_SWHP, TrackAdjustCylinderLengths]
BO_ 769 Sensor_SWHP: 8 Vector__XXX
 SG_ SWHP_SteeringMessageCount : 16|8@1+ (1,0) [0|255] "" Vector__XXX
 SG_ SWHP_Status : 40|8@1+ (1,0) [0|0] "" Vector__XXX
 SG_ SWHP_PositionIncrement : 24|16@1- (0.0879,0) [-32768|32767] "degrees" Vector__XXX
 SG_ SWHP_Position : 0|16@1- (0.0879,0) [0|0] "degrees" Vector__XXX
 SG_ SWHP_CRC : 48|16@1+ (1,0) [0|0] "" Vector__XXX

BO_ 2565865272 PROPA_From4WSToChassis: 8 Vector__XXX
 SG_ RearSteerSensorVoltage m30986 : 56|8@1+ (20,0) [0|0] "mV" Vector__XXX
 SG_ FrontSteerSensorVoltage m30986 : 48|8@1+ (20,0) [0|0] "mV" Vector__XXX
 SG_ JogAngle m30986 : 40|8@1+ (0.1,-10) [0|0] "Degrees" Vector__XXX
 SG_ RearSteerAngle m30986 : 32|8@1+ (0.2,0) [0|0] "Degrees" Vector__XXX
 SG_ FrontSteerAngle m30986 : 24|8@1+ (0.2,0) [0|0] "Degrees" Vector__XXX
 SG_ ActualSteerMode m30986 : 16|4@1+ (1,0) [0|0] "" Vector__XXX
 SG_ XID M : 7|16@0+ (1,0) [0|0] "" Vector__XXX

BO_ 2565865246 PROPA_FromChassisTo4WS: 8 Vector__XXX
 SG_ RearWheelAngle : 48|16@1+ (0.1,-3277) [0|0] "deg" Vector__XXX
 SG_ FrontWheelAngle : 32|16@1- (0.1,-3276) [0|0] "deg" Vector__XXX
 SG_ JogSteerCommand m30985 : 24|4@1+ (1,0) [0|0] "" Vector__XXX
 SG_ RequestedSteerMode m30985 : 16|4@1+ (1,0) [0|0] "" Vector__XXX
 SG_ XID M : 7|16@0+ (1,0) [0|0] "" Vector__XXX

BO_ 2565865214 PROPA: 8 Vector__XXX
 SG_ RearSteerSensorVoltage m30986 : 56|8@1+ (20,0) [0|0] "mV" Vector__XXX
 SG_ FrontSteerSensorVoltage m30986 : 48|8@1+ (20,0) [0|0] "mV" Vector__XXX
 SG_ JogAngle m30986 : 40|8@1+ (0.1,0) [0|0] "" Vector__XXX
 SG_ RearSteerAngle m30986 : 32|8@1+ (0.2,0) [0|0] "" Vector__XXX
 SG_ FrontSteerAngle m30986 : 24|8@1+ (0.2,0) [0|0] "Degrees" Vector__XXX
 SG_ JogSteerCommand m30985 : 24|4@1- (1,0) [0|0] "" Vector__XXX
 SG_ RequestedSteerMode m30985 : 16|4@1- (1,0) [0|0] "" Vector__XXX
 SG_ ActualSteerMode m30986 : 16|4@1- (1,0) [0|0] "" Vector__XXX
 SG_ XID M : 7|16@0+ (1,0) [0|0] "" Vector__XXX

BO_ 2566854654 TrackAdjustCylinderLengths: 8 Vector__XXX
 SG_ ActualRearRightCylinderLength : 56|8@1+ (1,0) [0|255] "" Vector__XXX
 SG_ ActualRearLeftCylinderLength : 40|8@1+ (1,0) [0|255] "" Vector__XXX
 SG_ ActualFrontRightCylinderLength : 48|8@1+ (1,0) [0|255] "" Vector__XXX
 SG_ ActualFrontLeftCylinderLength : 32|8@1+ (1,0) [0|255] "" Vector__XXX
 SG_ RequestRearRightCylinderLength : 24|8@1+ (1,0) [0|255] "" Vector__XXX
 SG_ RequestRearLeftCylinderLength : 8|8@1+ (1,0) [0|255] "" Vector__XXX
 SG_ RequestFrontRightCylinderLength : 16|8@1+ (1,0) [0|255] "" Vector__XXX
 SG_ RequestFrontLeftCylinderLength : 0|8@1+ (1,0) [0|255] "" Vector__XXX

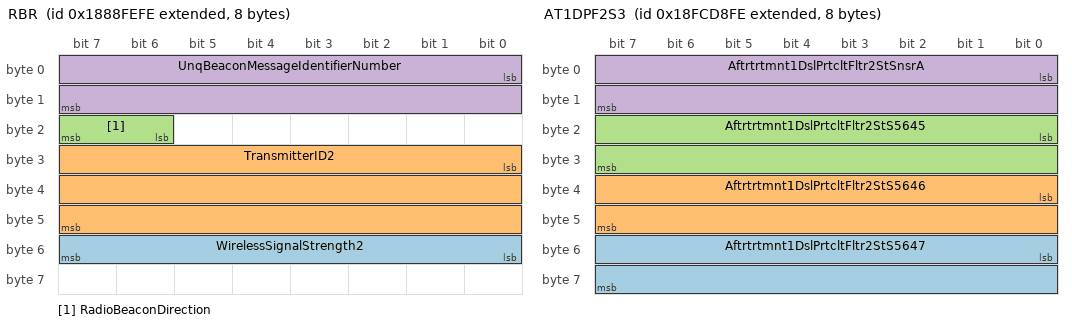
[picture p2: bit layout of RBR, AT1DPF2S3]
BO_ 2559115006 RBR: 8 Vector__XXX
 SG_ WirelessSignalStrength2 : 48|8@1+ (0.5,0) [-125|0] "dBm" Vector__XXX
 SG_ TransmitterID2 : 24|24@1+ (1,0) [0|16449635] "" Vector__XXX
 SG_ RadioBeaconDirection : 22|2@1+ (1,0) [0|3] "" Vector__XXX
 SG_ UnqBeaconMessageIdentifierNumber : 0|16@1+ (1,0) [0|64255] "" Vector__XXX

BO_ 2566707454 AT1DPF2S3: 8 Vector__XXX
 SG_ Aftrtrtmnt1DslPrtcltFltr2StS5647 : 48|16@1+ (0.1,0) [0|6425.5] "MHz" Vector__XXX
 SG_ Aftrtrtmnt1DslPrtcltFltr2StS5646 : 32|16@1+ (0.1,0) [0|6425.5] "MHz" Vector__XXX
 SG_ Aftrtrtmnt1DslPrtcltFltr2StS5645 : 16|16@1+ (0.1,0) [0|6425.5] "MHz" Vector__XXX
 SG_ Aftrtrtmnt1DslPrtcltFltr2StSnsrA : 0|16@1+ (0.1,0) [0|6425.5] "MHz" Vector__XXX

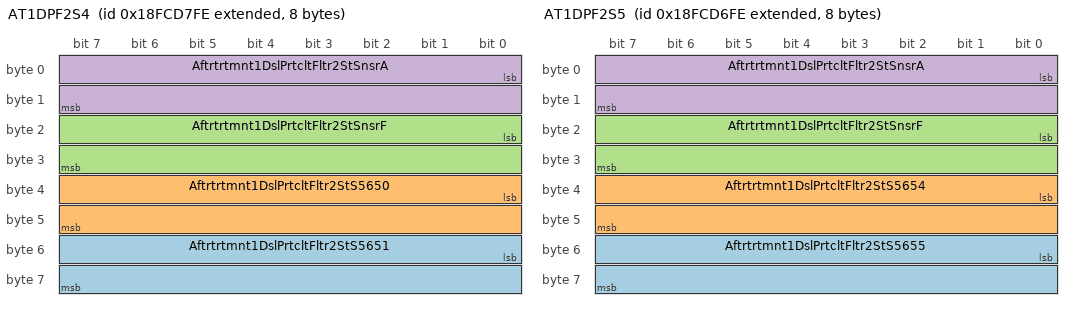
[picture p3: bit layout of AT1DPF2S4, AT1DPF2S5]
BO_ 2566707198 AT1DPF2S4: 8 Vector__XXX
 SG_ Aftrtrtmnt1DslPrtcltFltr2StS5651 : 48|16@1+ (0.0025,0) [0|160.6375] "%" Vector__XXX
 SG_ Aftrtrtmnt1DslPrtcltFltr2StS5650 : 32|16@1+ (0.1,0) [0|6425.5] "MHz" Vector__XXX
 SG_ Aftrtrtmnt1DslPrtcltFltr2StSnsrF : 16|16@1+ (0.0025,0) [0|160.6375] "%" Vector__XXX
 SG_ Aftrtrtmnt1DslPrtcltFltr2StSnsrA : 0|16@1+ (0.1,0) [0|6425.5] "MHz" Vector__XXX

BO_ 2566706942 AT1DPF2S5: 8 Vector__XXX
 SG_ Aftrtrtmnt1DslPrtcltFltr2StS5655 : 48|16@1+ (0.0025,0) [0|160.6375] "%" Vector__XXX
 SG_ Aftrtrtmnt1DslPrtcltFltr2StS5654 : 32|16@1+ (0.1,0) [0|6425.5] "MHz" Vector__XXX
 SG_ Aftrtrtmnt1DslPrtcltFltr2StSnsrF : 16|16@1+ (0.0025,0) [0|160.6375] "%" Vector__XXX
 SG_ Aftrtrtmnt1DslPrtcltFltr2StSnsrA : 0|16@1+ (0.1,0) [0|6425.5] "MHz" Vector__XXX

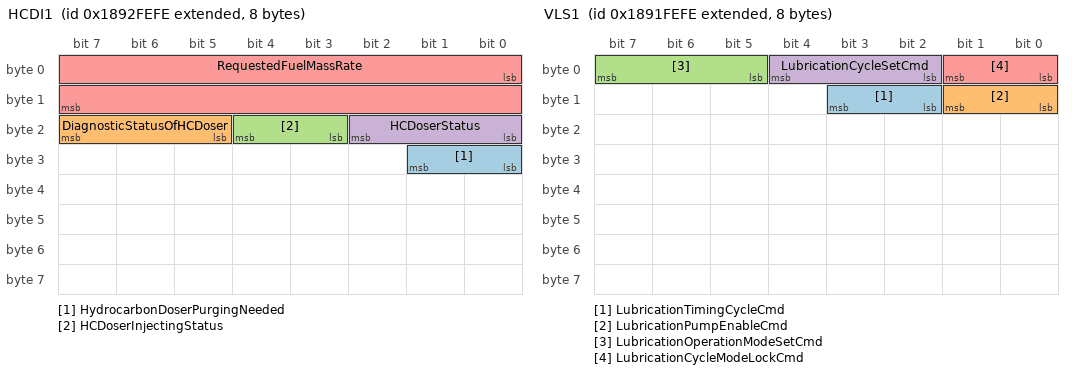
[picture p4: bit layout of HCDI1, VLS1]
BO_ 2559770366 HCDI1: 8 Vector__XXX
 SG_ HydrocarbonDoserPurgingNeeded : 24|2@1+ (1,0) [0|3] "" Vector__XXX
 SG_ DiagnosticStatusOfHCDoser : 21|3@1+ (1,0) [0|7] "" Vector__XXX
 SG_ HCDoserInjectingStatus : 19|2@1+ (1,0) [0|3] "" Vector__XXX
 SG_ HCDoserStatus : 16|3@1+ (1,0) [0|7] "" Vector__XXX
 SG_ RequestedFuelMassRate : 0|16@1+ (0.05,0) [0|3212.75] "g/m" Vector__XXX

BO_ 2559704830 VLS1: 8 Vector__XXX
 SG_ LubricationTimingCycleCmd : 10|2@1+ (1,0) [0|3] "" Vector__XXX
 SG_ LubricationPumpEnableCmd : 8|2@1+ (1,0) [0|3] "" Vector__XXX
 SG_ LubricationOperationModeSetCmd : 5|3@1+ (1,0) [0|7] "" Vector__XXX
 SG_ LubricationCycleSetCmd : 2|3@1+ (1,0) [0|7] "" Vector__XXX
 SG_ LubricationCycleModeLockCmd : 0|2@1+ (1,0) [0|3] "" Vector__XXX

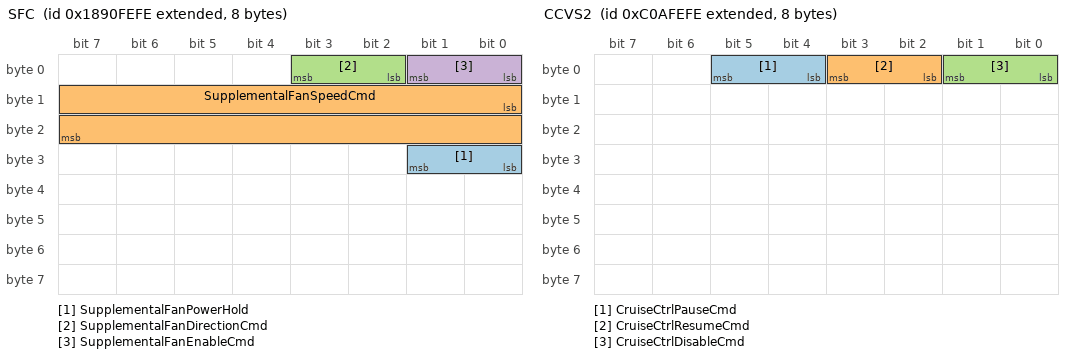
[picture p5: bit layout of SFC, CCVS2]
BO_ 2559639294 SFC: 8 Vector__XXX
 SG_ SupplementalFanPowerHold : 24|2@1+ (1,0) [0|3] "" Vector__XXX
 SG_ SupplementalFanSpeedCmd : 8|16@1+ (0.5,0) [0|32127.5] "rpm" Vector__XXX
 SG_ SupplementalFanDirectionCmd : 2|2@1+ (1,0) [0|3] "" Vector__XXX
 SG_ SupplementalFanEnableCmd : 0|2@1+ (1,0) [0|3] "" Vector__XXX

BO_ 2559573758 ECC: 8 Vector__XXX
 SG_ ClntLvlEngPrtctnShtdwnOvrrideCmd : 0|2@1+ (1,0) [0|3] "" Vector__XXX

BO_ 2349530878 CCVS2: 8 Vector__XXX
 SG_ CruiseCtrlPauseCmd : 4|2@1+ (1,0) [0|3] "" Vector__XXX
 SG_ CruiseCtrlResumeCmd : 2|2@1+ (1,0) [0|3] "" Vector__XXX
 SG_ CruiseCtrlDisableCmd : 0|2@1+ (1,0) [0|3] "" Vector__XXX

BO_ 2559246078 RGE12: 8 Vector__XXX

BO_ 2559180542 RGE24: 8 Vector__XXX

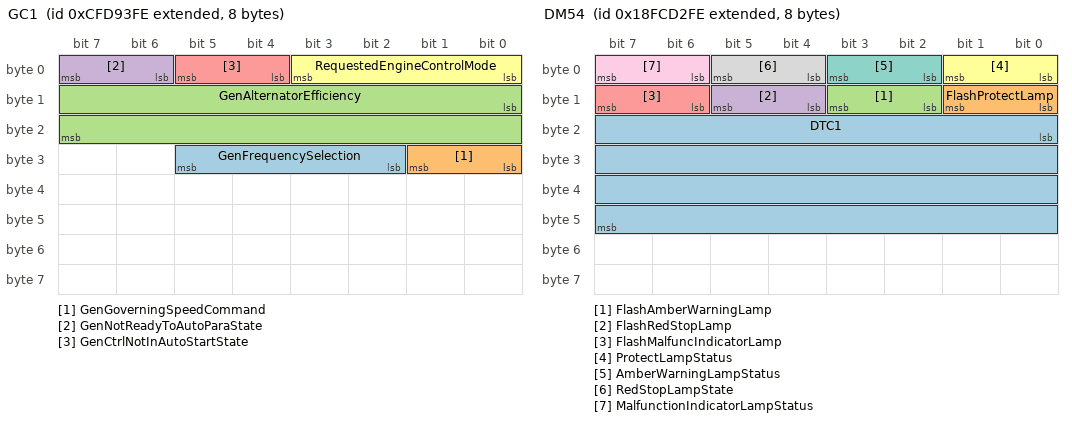
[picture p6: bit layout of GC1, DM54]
BO_ 2365428734 GC1: 8 Vector__XXX
 SG_ GenFrequencySelection : 26|4@1+ (1,0) [0|15] "" Vector__XXX
 SG_ GenGoverningSpeedCommand : 24|2@1+ (1,0) [0|3] "" Vector__XXX
 SG_ GenAlternatorEfficiency : 8|16@1+ (0.0025,0) [0|163.8375] "%" Vector__XXX
 SG_ GenNotReadyToAutoParaState : 6|2@1+ (1,0) [0|0] "" Vector__XXX
 SG_ GenCtrlNotInAutoStartState : 4|2@1+ (1,0) [0|0] "" Vector__XXX
 SG_ RequestedEngineControlMode : 0|4@1+ (1,0) [0|0] "" Vector__XXX

BO_ 2566702846 DM57: 8 Vector__XXX
 SG_ EngOBDWarmUpSequence : 0|2@1+ (1,0) [0|3] "" Vector__XXX

BO_ 2566703102 DM56: 8 Vector__XXX
 SG_ CertificationEngineFamilyName : 8|8@1+ (1,0) [0|255] "" Vector__XXX
 SG_ ModelYear : 0|8@1+ (1,0) [0|1.84467440737096E+019] "" Vector__XXX

BO_ 2566705918 DM54: 8 Vector__XXX
 SG_ DTC1 : 16|32@1+ (1,0) [0|4294967295] "" Vector__XXX
 SG_ FlashProtectLamp : 8|2@1+ (1,0) [0|3] "" Vector__XXX
 SG_ FlashAmberWarningLamp : 10|2@1+ (1,0) [0|3] "" Vector__XXX
 SG_ FlashRedStopLamp : 12|2@1+ (1,0) [0|3] "" Vector__XXX
 SG_ FlashMalfuncIndicatorLamp : 14|2@1+ (1,0) [0|3] "" Vector__XXX
 SG_ ProtectLampStatus : 0|2@1+ (1,0) [0|3] "" Vector__XXX
 SG_ AmberWarningLampStatus : 2|2@1+ (1,0) [0|3] "" Vector__XXX
 SG_ RedStopLampState : 4|2@1+ (1,0) [0|3] "" Vector__XXX
 SG_ MalfunctionIndicatorLampStatus : 6|2@1+ (1,0) [0|3] "" Vector__XXX

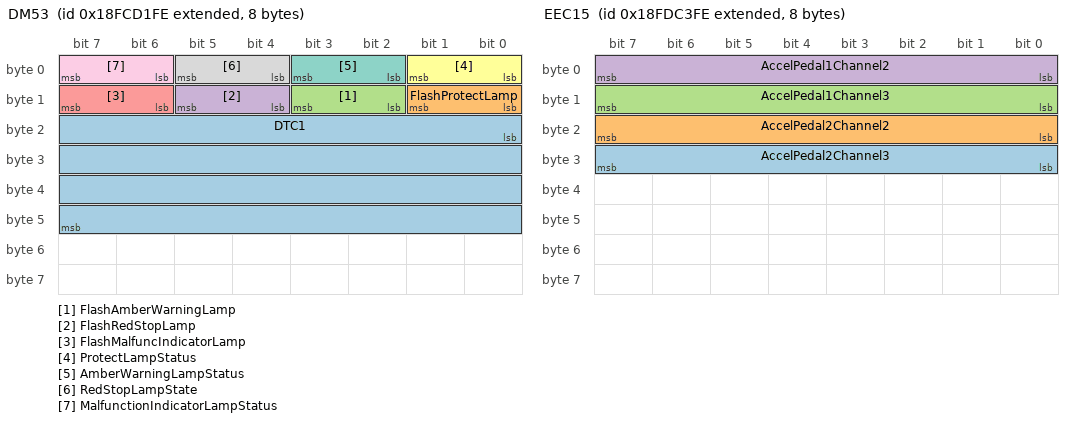
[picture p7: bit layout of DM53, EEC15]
BO_ 2566705662 DM53: 8 Vector__XXX
 SG_ DTC1 : 16|32@1+ (1,0) [0|4294967295] "" Vector__XXX
 SG_ FlashProtectLamp : 8|2@1+ (1,0) [0|3] "" Vector__XXX
 SG_ FlashAmberWarningLamp : 10|2@1+ (1,0) [0|3] "" Vector__XXX
 SG_ FlashRedStopLamp : 12|2@1+ (1,0) [0|3] "" Vector__XXX
 SG_ FlashMalfuncIndicatorLamp : 14|2@1+ (1,0) [0|3] "" Vector__XXX
 SG_ ProtectLampStatus : 0|2@1+ (1,0) [0|3] "" Vector__XXX
 SG_ AmberWarningLampStatus : 2|2@1+ (1,0) [0|3] "" Vector__XXX
 SG_ RedStopLampState : 4|2@1+ (1,0) [0|3] "" Vector__XXX
 SG_ MalfunctionIndicatorLampStatus : 6|2@1+ (1,0) [0|3] "" Vector__XXX

BO_ 2566706174 DM55: 8 Vector__XXX

BO_ 2349465342 SRASI: 8 Vector__XXX
 SG_ StaticRollAngleStatus : 8|3@1+ (1,0) [0|7] "" Vector__XXX
 SG_ StaticRollAngle : 0|8@1+ (1,-125) [-125|125] "deg" Vector__XXX

BO_ 2566767614 EEC15: 8 Vector__XXX
 SG_ AccelPedal2Channel3 : 24|8@1+ (0.4,0) [0|100] "%" Vector__XXX
 SG_ AccelPedal2Channel2 : 16|8@1+ (0.4,0) [0|100] "%" Vector__XXX
 SG_ AccelPedal1Channel3 : 8|8@1+ (0.4,0) [0|100] "%" Vector__XXX
 SG_ AccelPedal1Channel2 : 0|8@1+ (0.4,0) [0|100] "%" Vector__XXX

BO_ 2559049470 ESR: 8 Vector__XXX
 SG_ DesiredEngFuelingState : 0|2@1+ (1,0) [0|3] "" Vector__XXX

CM_ BU_ SteeringController "Controller: PVED

NOT CONFIRMED WITH ROGO";
CM_ BU_ SteeringColumnUnit "Controller: SASA

NOT CONFIRMED WITH ROGO";
CM_ BU_ RearAxleSteeringController "Controller: 4-Wheel Steer

THE 4WS MODULE MIGHT BE INTEGRATED INTO CHASSIS CONTROLLER";
CM_ BU_ Engine "Controller: Engine";
CM_ BU_ ChassisController "Controller: EXT Lite
Responsiblity: Contains communication gateway (WBZ Bridge)  between all four networks --> J1939 Engine, J1939 Chassis, ISO 11783, and Generic Driver.  Contains track adjust module.";
CM_ BO_ 3221225472 "This is a message for not used signals, created by Vector CANdb++ DBC OLE DB Provider.";
CM_ SG_ 3221225472 CabNoiseCtrlTuningCmd "Command values for the Tuning State of the Cab Noise Control System.  The Tuning State allows the Cab Noise Control ...";
CM_ SG_ 3221225472 CabNoiseCtrlCmd "Command signal to change the state of the Cab Noise Control System to on-line or off-line ...";
CM_ SG_ 3221225472 MagnetGeneratorCtrl "Command signal used to Enable and Disable the Generator controlling a Magnet.";
CM_ SG_ 3221225472 SpecialIgnitorLoop62Resistance "Resistance of Special Ignitor Loop 62.   Since there are many different vehicle types (e.g. truck, bus, firetruck or ...";
CM_ SG_ 3221225472 EngExhstBckPressRegulatorCtrlCmd "The control command to the Engine Exhaust Back Pressure Regulator, normalized to percent.  100 percent means the ...";
CM_ SG_ 3221225472 EngExhaustBackPressActuator1Temp "Temperature of the Engine Exhaust Back Pressure Actuator 1 drive circuitry.  Temperature excursions may affect the ...";
CM_ SG_ 3221225472 EngExhstBckPrssActtor1DesiredPos "The requested position of the Engine Exhaust Back Pressure Actuator 1 by the engine ECU, where 0% represents fully ...";
CM_ SG_ 3221225472 EngTurboWastegateActuator1Temp "Temperature of the Engine Turbocharger Wastegate Actuator 1 drive circuitry.  Temperature excursions may affect the ...";
CM_ SG_ 3221225472 EngExhstBckPrssRgltrCtrlOprtnStt "Used to identify the status of Engine Exhaust Back Pressure Regulator.";
CM_ SG_ 3221225472 EngExhstBckPrssRglatorTempStatus "Used to identify the status of the Engine Exhaust Back Pressure Regulator (EBPR) drive circuitry temperature.";
CM_ SG_ 3221225472 EngExhstBckPrssRgltrPrlminaryFMI "Used to identify the applicable J1939-73 FMI detected in the Engine Exhaust Back Pressure Regulator (EBPR) by the ...";
CM_ SG_ 3221225472 EngExhaustBackPressRegulatorPos "The position of the Exhaust Back Pressure Regulator (EBPR) expressed as a percentage of full travel.  One hundred ...";
CM_ SG_ 3221225472 EngTrbCmprssrBypassActuator2Temp "Temperature of the Engine Turbocharger Compressor Bypass Actuator 2 drive circuitry.    Temperature excursions may ...";
CM_ SG_ 3221225472 EngTrbCmprssrBypassActuator1Temp "Temperature of the Engine Turbocharger Compressor Bypass Actuator 1 drive circuitry.    Temperature excursions may ...";
CM_ SG_ 3221225472 EngCoolantPress2 "Gage pressure of liquid found in the engine coolant system - second instance ...";
CM_ SG_ 3221225472 EngExhstGsRcrcltn2Valve2PosError "The position error of the Exhaust Gas Recirculation 2 valve 2, determined as the actual position (SPN 5265) minus the ...";
CM_ SG_ 3221225472 EngExhstGsRcrcltn2Valve1PosError "The position error of the Exhaust Gas Recirculation 2 valve, determined as the actual position (SPN 5264) minus the ...";
CM_ SG_ 3221225472 DslPrtcltFltr1CndtnsNtMtFrActvRg "Indicates that diesel particulate filter 1 is not able to begin or continue an active regenerate event at the current engine ...";
CM_ SG_ 3221225472 DslPrtcltFltrActvRgnrtnInhbt5629 "Indicates the state of diesel particulate filter active regeneration inhibition due to low exhaust gas pressure.";
CM_ SG_ 3221225472 HydrocarbonDoserPurgingEnable "Purging enable of the Hydrocarbon Doser (HCD).";
CM_ SG_ 3221225472 DslPrtcltFltrActvRgnrtnInhbt3717 "Speed ...";
CM_ SG_ 3221225472 DslPrtcltFltrActvRgnrtnInhbtdDTE "Indicates the state of diesel particulate filter active regeneration inhibition due to the engine not being warmed up.";
CM_ SG_ 3221225472 DslPrtcltFltrActvRgnrtnInhbt3715 "Indicates the state of diesel particulate filter active regeneration inhibition due to a permanent system lockout.";
CM_ SG_ 3221225472 DslPrtcltFltrActvRgnrtnInhbt3713 "Indicates the state of diesel particulate filter active regeneration inhibition due to a system timeout.";
CM_ SG_ 3221225472 DslPrtcltFltrActvRgnrtnInhbt3712 "Indicates the state of diesel particulate filter active regeneration inhibition due to a system fault being active.";
CM_ SG_ 3221225472 DslPrtcltFltrActvRgnrtnInhbt3710 "Indicates the state of diesel particulate filter active regeneration inhibition due to the parking brake being not set.";
CM_ SG_ 3221225472 DslPrtcltFltrActvRgnrtnInhbtdDTV "Speed ...";
CM_ SG_ 3221225472 DslPrtcltFltrActvRgnrtnInhbtdDTO "Indicates the state of diesel particulate filter active regeneration inhibition due to the transmission being out of neutral.";
CM_ SG_ 3221225472 DslPrtcltFltr2StSnsrECUIntrnlTmp "Internal temperature of the diesel particulate filter 2 soot sensor ECU.";
CM_ SG_ 3221225472 DslPrtcltFltr1StSnsrECUIntrnlTmp "Internal temperature of the diesel particulate filter 1 soot sensor ECU.";
CM_ SG_ 3221225472 Aftrtrtmnt1SCROprtrIndcmntActvTr "The distance traveled while SCR inducement (SPN 5246 is equal to level 1 to 5) is active.  Distance is reset once ...";
CM_ SG_ 3221225472 Aftrtrtmnt1SCRCnvrsionEfficiency "The SCR conversion efficiency percentage.  Calculated as 100 times the catalyst intake NOx minus the catalyst outlet ...";
CM_ SG_ 3221225472 Aftrtrtmnt1CmmnddDslExhstFldCnsm "This parameter transmits the amount of diesel exhaust fluid that the emissions control system has requested to be used, ...";
CM_ SG_ 3221225472 Aftrtrtmnt1DslExhstFldAvrgCnsmpt "Measured use of diesel exhaust fluid by a Selective Catalytic Reduction system for exhaust emission control, averaged ...";
CM_ SG_ 3221225472 TransOilLevel2MeasurementStatus "Measurement status for the second instance of a transmission oil level indicator. Indicates if conditions are acceptable to ...";
CM_ SG_ 3221225472 TransOilLevel2CountdownTimer "Countdown timer for the second instance of a transmission oil level indicator. Once all vehicle conditions (such as vehicle ...";
CM_ SG_ 3221225472 TransOilLevel2High_Low "Second instance of a transmission oil level indicator. Conveys the current volume of transmission sump oil compared to ...";
CM_ SG_ 3221225472 TransOilTemp2 "Second instance of transmission lubricant temperature. This parameter may reflect the temperature of a second sump or ...";
CM_ SG_ 3221225472 EngIntakeManifold1AbsPress4817 "The absolute pressure measurement of the air intake manifold. If there are multiple air pressure sensors in the intake ...";
CM_ SG_ 3221225472 FuelEnergyContent "Energy content (lower heating value) of the gaseous fuel.";
CM_ SG_ 3221225472 ReferenceEngGasMassFlowRate "Configuration of the mass flow rate of gaseous fuel expected for 100% engine fuel valve control command.";
CM_ SG_ 3221225472 Aftrtrtmnt1DslExhstFluidProperty "This parameter indicates the property of the fluid compound in the tank.  A value of 0011 indicates uncontaminated Diesel ...";
CM_ SG_ 3221225472 Aftrtrtmnt1DslExhstFldCndctivity "A measure of the conductivity of the diesel exhaust fluid at the sensor.  The conductivity is an indication of the diesel ...";
CM_ SG_ 3221225472 Aftrtrtmnt1DslExhstFldCncntrtion "A measure of the concentration of urea in water.  Zero percent means that the tank contains no urea.  A 32.5% value ...";
CM_ SG_ 3221225472 Aftrtrtmnt1DselExhaustFluidTemp2 "Temperature of the diesel exhaust fluid at the device measuring diesel exhaust fluid quality ...";
CM_ SG_ 3221225472 TrailerVDCActive "The trailer-VDC (Vehicle Dynamic Control) is an electronic vehicle stability function within the (semi) trailer braking ...";
CM_ SG_ 3221225472 TransLoadReductionInhibitRq "Request signal to the transmission to inhibit activation of load reduction functions.";
CM_ SG_ 3221225472 ClntLvlEngPrtctionShutdownStatus "Parameter which indicates the configuration of the coolant level engine protection shutdown.";
CM_ SG_ 3221225472 ServiceComponentIdentificatio913 "Identification of component needing service.  See Table SPN911_A.";
CM_ SG_ 3221225472 ServiceComponentIdentificatio912 "Identification of component needing service.  See Table SPN911_A.";
CM_ SG_ 3221225472 EngThrottleValveDiffPress "The differential pressure between the intake and outlet of a throttle valve.  The differential pressure is measured from the ...";
CM_ SG_ 3221225472 EngFuelCtrlCtrlMode "Indicates whether the Engine Fuel Control System is in open loop or closed loop.";
CM_ SG_ 3221225472 EmergencyBrakingActive "Signal which indicates an emergency braking situation (ref. ECE Regulation 13 paragraph 5.2.1.31) with high ...";
CM_ SG_ 3221225472 EngExRangeCoolantPress "Gage pressure of liquid found in engine cooling system.";
CM_ SG_ 3221225472 EngCldStrtFlIgniterRelayFeedback "Feedback state of the engine cold start fuel igniter relay which indicates the status of the relay output.";
CM_ SG_ 3221225472 EngColdStartFuelIgniterRelay "The engine cold start fuel igniter relay control command.  This command controls the relay, not the igniter.";
CM_ SG_ 3221225472 EngColdStartFuelIgniterCmd "The engine cold start fuel igniter control command, normalized to %, where 0% represents fully off and 100% represents ...";
CM_ SG_ 3221225472 ParkBrakeCmd "Request by a secondary device to command the Park Brake.  The Park Brake controller should treat this as a request and ...";
CM_ SG_ 3221225472 SwtchBcklghtIllmntnBrghtnssPrcnt "Commanded switch backlight brightness level for all operator control switches.  This is separate from the cab display ...";
CM_ SG_ 3221225472 Aftrtrtmnt2ThrWyCtlytcCnvrtr4300 "Used to identify the applicable J1939-73 FMI detected in the Three Way Catalytic Converter differential pressure sensor ...";
CM_ SG_ 3221225472 Aftrtrtmnt2ThrWyCtlytcCnvrtr4299 "Used to identify the applicable J1939-73 FMI detected in the Three Way Catalytic Converter outlet gas temperature ...";
CM_ SG_ 3221225472 Aftrtrtmnt2ThrWyCtlytcCnvrtr4298 "Used to identify the applicable J1939-73 FMI detected in the Three Way Catalytic Converter intake gas temperature ...";
CM_ SG_ 3221225472 NOxSnsrATO2SlfdgnosisFinalResult "Self-diagnosis result for NOx sensor ATO2 as a ratio of detected value to reference value defined by supplier.";
CM_ SG_ 3221225472 Aftrtrtmnt2OtltGsNOxSnsrCrrc5049 "Correction of pressure NOx-signal to correct (recalculate) sensor signal on the Engine ECU side.";
CM_ SG_ 3221225472 NOxSnsrATO2OperationHoursCounter "Counted hours that the NOx-sensor was operated with status \"dewpoint reached\" ...";
CM_ SG_ 3221225472 Aftrtrtmnt2OtltGsNOxSnsrNwPr5047 "New part deviation NOx_Offset to correct (recalculate) sensor signal on the Engine ECU side.";
CM_ SG_ 3221225472 NOxSnsrATI2SlfdgnosisFinalResult "Self-diagnosis result for NOx sensor ATI2 as a ratio of detected value to reference value defined by supplier.";
CM_ SG_ 3221225472 Aftrtrtmnt2IntkGsNOxSnsrCrrc5042 "Correction of pressure NOx-signal to correct (recalculate) sensor signal on the Engine ECU side.";
CM_ SG_ 3221225472 NOxSnsrATI2OperationHoursCounter "Counted hours that the NOx-sensor was operated with status \"dewpoint reached\" ...";
CM_ SG_ 3221225472 Aftrtrtmnt2IntkGsNOxSnsrNwPr5040 "New part deviation NOx_Offset to correct (recalculate) sensor signal on the Engine ECU side.";
CM_ SG_ 3221225472 Aftrtrtmnt1ThrWyCtlytcCnvrtr4294 "Used to identify the applicable J1939-73 FMI detected in the Three Way Catalytic Converter differential pressure sensor ...";
CM_ SG_ 3221225472 Aftrtrtmnt1ThrWyCtlytcCnvrtr4293 "Used to identify the applicable J1939-73 FMI detected in the Three Way Catalytic Converter outlet gas temperature ...";
CM_ SG_ 3221225472 Aftrtrtmnt1ThrWyCtlytcCnvrtr4292 "Used to identify the applicable J1939-73 FMI detected in the Three Way Catalytic Converter intake gas temperature ...";
CM_ SG_ 3221225472 Aftrtrtmnt1DslExhstFldTankHeater "Percentage of heating applied to the aftertreatment 1 diesel exhaust fluid tank heater.  A value of 0% means no heating ...";
CM_ SG_ 3221225472 Aftrtrtmnt1DslExhstFldTnkLvlPrlm "Used to identify the applicable J1939-73 FMI that applies to the most significant failure of the diesel exhaust fluid tank ...";
CM_ SG_ 3221225472 Aftrtrtmnt1DslExhstFldTankLevel2 "The measure of the diesel exhaust fluid level in the diesel exhaust fluid tank.";
CM_ SG_ 3221225472 Aftrtrtmnt1DslExhstFluidTankTemp "Temperature of the diesel exhaust fluid in the storage tank.";
CM_ SG_ 3221225472 Aftrtrtmnt1DslExhstFlidTankLevel "Ratio of volume of diesel exhaust fluid to the total volume of diesel exhaust fluid storage container.";
CM_ SG_ 3221225472 NOxSnsrATO1SlfdgnosisFinalResult "Self-diagnosis result for NOx sensor ATO1 as a ratio of detected value to reference value defined by supplier.";
CM_ SG_ 3221225472 Aftrtrtmnt1OtltGsNOxSnsrCrrc5035 "Correction of pressure NOx-signal to correct (recalculate) sensor signal on the Engine ECU side.";
CM_ SG_ 3221225472 NOxSnsrATO1OperationHoursCounter "Counted hours that the NOx-sensor was operated with status \"dewpoint reached\" ...";
CM_ SG_ 3221225472 Aftrtrtmnt1OtltGsNOxSnsrNwPr5033 "New part deviation NOx_Offset to correct (recalculate) sensor signal on the Engine ECU side.";
CM_ SG_ 3221225472 NOxSnsrATI1SlfdgnosisFinalResult "Self-diagnosis result for NOx sensor ATI1 as a ratio of detected value to reference value defined by supplier.";
CM_ SG_ 3221225472 Aftrtrtmnt1IntkGsNOxSnsrCrrc5028 "Correction of pressure NOx-signal to correct (recalculate) sensor signal on the Engine ECU side.";
CM_ SG_ 3221225472 NOxSnsrATI1OperationHoursCounter "Counted hours that the NOx-sensor was operated with status \"dewpoint reached\" ...";
CM_ SG_ 3221225472 Aftrtrtmnt1IntkGsNOxSnsrNwPr5026 "New part deviation NOx_Offset to correct (recalculate) sensor signal on the Engine ECU side.";
CM_ SG_ 3221225472 Armrest2Switch2 "Status of the second switch located in armrest 2.";
CM_ SG_ 3221225472 Armrest2Switch1 "Status of the first switch located in armrest 2.";
CM_ SG_ 3221225472 Armrest1Switch2 "Status of the second switch located in armrest 1.";
CM_ SG_ 3221225472 Armrest1Switch1 "Status of the first switch located in armrest 1.";
CM_ SG_ 3221225472 Aftrtrtmnt2SCRCnvrsionEfficiency "The SCR conversion efficiency percentage.  Calculated as 100 times the catalyst intake NOx minus the catalyst outlet ...";
CM_ SG_ 3221225472 Aftrtrtmnt2SCRCmmnddCtlystDslExh "This parameter transmits the amount of diesel exhaust fluid that the emissions control system has requested to be used, ...";
CM_ SG_ 3221225472 Aftrtrtmnt2DslExhstFldAvrgCnsmpt "Measured use of diesel exhaust fluid by a Selective Catalytic Reduction system for exhaust emission control, averaged ...";
CM_ SG_ 3221225472 Aftrtrtmnt2DslExhstFldTnk2HtrPrl "Used to identify the applicable J1939-73 FMI detected in the diesel exhaust fluid tank 2 heater by the manufacturer’s ...";
CM_ SG_ 3221225472 Aftrtrtmnt2DslExhstFldTnk2Heater "The diesel exhaust fluid tank 2 heater percentage for aftertreatment system 1 (exhaust bank 1). 0% is off.  See SPN 5415 ...";
CM_ SG_ 3221225472 Aftrtrtmnt2DslExhstFldTnk2TmpPrl "Used to identify the applicable J1939-73 FMI detected in the diesel exhaust fluid tank 2 temperature, by the ...";
CM_ SG_ 3221225472 Aftrtrtmnt2DslExhstFldTnk2LvlPrl "Used to identify the applicable J1939-73 FMI detected in the diesel exhaust fluid tank 2 level, by the manufacturer’s ...";
CM_ SG_ 3221225472 Aftrtrtmnt2DslExhstFldTnk2Level2 "The diesel exhaust fluid tank 2 level height in mm for aftertreatment system 2 (exhaust bank 2).  Tank 2 is used as a quick ...";
CM_ SG_ 3221225472 Aftrtrtmnt2DslExhstFlidTank2Temp "The diesel exhaust fluid tank 2 temperature for aftertreatment system 2 (exhaust bank 2).  Tank 2 is used as a quick thaw ...";
CM_ SG_ 3221225472 Aftrtrtmnt2DslExhstFldTank2Level "The diesel exhaust fluid tank 2 level percentage for aftertreatment system 2 (exhaust bank 2).  0% is empty and 100% is ...";
CM_ SG_ 3221225472 Aftrtrtmnt2DslExhstFldTnk1HtrPrl "Used to identify the applicable J1939-73 FMI detected in the diesel exhaust fluid tank 1 heater, by the manufacturer’s ...";
CM_ SG_ 3221225472 Aftrtrtmnt2DslExhstFldTankHeater "Percentage of heating applied to the aftertreatment 2 diesel exhaust fluid tank heater.  A value of 0% means no heating ...";
CM_ SG_ 3221225472 Aftrtrtmnt2DslExhstFldTnk1TmpPrl "Used to identify the applicable J1939-73 FMI detected in the diesel exhaust fluid tank 1 temperature by the ...";
CM_ SG_ 3221225472 Aftrtrtmnt2DslExhstFldTnkLvlPrlm "Used to identify the applicable J1939-73 FMI that applies to the most significant failure of the diesel exhaust fluid tank ...";
CM_ SG_ 3221225472 Aftrtrtmnt2DslExhstFldTankLevel2 "The measure of the diesel exhaust fluid level in the diesel exhaust fluid tank.";
CM_ SG_ 3221225472 Aftrtrtmnt2DslExhstFluidTankTemp "Temperature of the diesel exhaust fluid in the storage tank.";
CM_ SG_ 3221225472 Aftrtrtmnt2DslExhstFlidTankLevel "Ratio of volume of diesel exhaust fluid to the total volume of diesel exhaust fluid storage container.";
CM_ SG_ 3221225472 Aftrtrtmnt2DslExhstFldTnkDrnVlvC "Commanded percentage of maximum Aftertreatment 2 Diesel Exhaust Fluid Tank Drain Valve opening. 100% means the ...";
CM_ SG_ 3221225472 Aftrtrtmnt2DslExhstFlidPumpState "State of Aftertreatment 2 Diesel Exhaust Fluid dosing pump.";
CM_ SG_ 3221225472 Aftrtrtmnt2DslExhstFldTnkFllVlvC "Commanded percentage of maximum Aftertreatment 2 Diesel Exhaust Fluid Tank Fill Valve opening. 100% means the fill ...";
CM_ SG_ 3221225472 Aftrtrtmnt2DslExhstFldRturnValve "Command to the valve which determines whether the diesel exhaust fluid is delivered to the injector or is routed back to ...";
CM_ SG_ 3221225472 Aftrtrtmnt2DslExhstFldPmpDrvPrcn "The percent (command) sent to the motor to control the speed of  the diesel exhaust fluid pump.";
CM_ SG_ 3221225472 Aftrtrtmnt2DslExhstFldPmpMtrSped "Rotational speed of the motor driving a pump for diesel exhaust fluid used in an aftertreatment system.";
CM_ SG_ 3221225472 Aftrtrtmnt2DeselExhaustFluidType "This parameter indicates the property of the fluid compound in the tank.  A value of 0011 indicates uncontaminated Diesel ...";
CM_ SG_ 3221225472 Aftrtrtmnt2DslExhstFldCndctivity "A measure of the conductivity of the diesel exhaust fluid at the sensor.  The conductivity is an indication of the diesel ...";
CM_ SG_ 3221225472 Aftrtrtmnt2DslExhstFldCncntrtion "A measure of the concentration of urea in water.  Zero percent means that the tank contains no urea.  A 32.5% value ...";
CM_ SG_ 3221225472 Aftrtrtmnt2DselExhaustFluidTemp2 "Temperature of the diesel exhaust fluid at the device measuring diesel exhaust fluid quality ...";
CM_ SG_ 3221225472 Aftrtrtmnt2SCRExhstGsDffPrssPrlm "Used to identify the applicable J1939-73 FMI detected in the SCR differential pressure sensor by the manufacturer’s ...";
CM_ SG_ 3221225472 Aftrtrtmnt2SCRExhustGasDiffPress "Exhaust differential pressure measured between the intake and exhaust of an SCR component in exhaust bank 2.";
CM_ SG_ 3221225472 Aftrtrtmnt2DslExhstFldTnk2HtrCmd "This is the command for the Aftertreatment 2 Diesel Exhaust Fluid Tank 2 Heater.  See SPN 4438 for the measured value ...";
CM_ SG_ 3221225472 Aftrtrtmnt2DslExhstFldTnkHterCmd "Command for the Aftertreatment 2 Diesel Exhaust Fluid Tank Heater.  A value of 0% means no heating applied, a value ...";
CM_ SG_ 3221225472 Aftrtrtmnt2DslExhstFldLneHeater4 "The diesel exhaust fluid line heater 4 request for aftertreatment system 2 (exhaust bank 2).";
CM_ SG_ 3221225472 Aftrtrtmnt2DslExhstFldLneHeater3 "The diesel exhaust fluid line heater 3 request for aftertreatment system 2 (exhaust bank 2).";
CM_ SG_ 3221225472 Aftrtrtmnt2DslExhstFldLneHeater2 "The diesel exhaust fluid line heater 2 request for aftertreatment system 2 (exhaust bank 2).";
CM_ SG_ 3221225472 Aftrtrtmnt2DslExhstFldLneHeater1 "The diesel exhaust fluid line heater 1 request for aftertreatment system 2 (exhaust bank 2).";
CM_ SG_ 3221225472 Aftrtrtmnt2DslExhstFldDsrHtngMdR "Used if multiple heater modes are available in the Doser.";
CM_ SG_ 3221225472 Aftrtrtmnt2DslExhstFldDsrFltSppr "Used if external devices can warn of conditions that require suppression of potential faults in the doser due to ...";
CM_ SG_ 3221225472 Aftrtrtmnt2DslExhstFldRqstdQntty "Represents the command for the diesel exhaust fluid quantity integrator in the dosing control unit ...";
CM_ SG_ 3221225472 Aftrtrtmnt2DslExhstFldDsngRqstdQ "Actual requested dosing quantity of diesel exhaust fluid.";
CM_ SG_ 3221225472 Aftrtrtmnt2DslExhstFldLnHtr4Prlm "Used to identify the applicable J1939-73 FMI detected in the diesel exhaust fluid line heater 4, by the manufacturer’s ...";
CM_ SG_ 3221225472 Aftrtrtmnt2DslExhstFldLnHtr4Stte "The diesel exhaust fluid line heater 4 state for aftertreatment system 2 (exhaust bank 2).";
CM_ SG_ 3221225472 Aftrtrtmnt2DslExhstFldLnHtr3Prlm "Used to identify the applicable J1939-73 FMI detected in the diesel exhaust fluid line heater 3, by the manufacturer’s ...";
CM_ SG_ 3221225472 Aftrtrtmnt2DslExhstFldLnHtr3Stte "The diesel exhaust fluid line heater 3 state for aftertreatment system 2 (exhaust bank 2).";
CM_ SG_ 3221225472 Aftrtrtmnt2DslExhstFldLnHtr2Prlm "Used to identify the applicable J1939-73 FMI detected in the diesel exhaust fluid line heater 2, by the manufacturer’s ...";
CM_ SG_ 3221225472 Aftrtrtmnt2DslExhstFldLnHtr2Stte "The diesel exhaust fluid line heater 2 state for aftertreatment system 2 (exhaust bank 2).";
CM_ SG_ 3221225472 Aftrtrtmnt2DslExhstFldLnHtr1Prlm "Used to identify the applicable J1939-73 FMI detected in the diesel exhaust fluid line heater 1, by the manufacturer’s ...";
CM_ SG_ 3221225472 Aftrtrtmnt2DslExhstFldLnHtr1Stte "The diesel exhaust fluid line heater 1 state for aftertreatment system 2 (exhaust bank 2).";
CM_ SG_ 3221225472 Aftrtrtmnt2DslExhstFldDosingTemp "The diesel exhaust fluid dosing temperature (measured closest to dosing valve) for aftertreatment system 2 (exhaust ...";
CM_ SG_ 3221225472 Aftrtrtmnt2DslExhstFldDsngAbsPrs "The SCR dosing diesel exhaust fluid absolute pressure (measured closest to dosing valve) for aftertreatment system 2 ...";
CM_ SG_ 3221225472 Aftrtrtmnt2DslExhstFldActlQnttyO "The SCR requested diesel exhaust fluid integrator total quantity for aftertreatment system 2 (exhaust bank 2).";
CM_ SG_ 3221225472 Aftrtrtmnt2DslExhstFldActlDsngQn "Actual reducing agent quantity of SCR system.";
CM_ SG_ 3221225472 Aftrtrtmnt2GsOxdtnCtlystOtlt4763 "Used to identify the applicable J1939-73 FMI detected in the gas oxidation catalyst outlet gas temperature sensor by the ...";
CM_ SG_ 3221225472 Aftrtrtmnt2GsOxdtnCtlystIntk4762 "Used to identify the applicable J1939-73 FMI detected in the gas oxidation catalyst intake gas temperature sensor by the ...";
CM_ SG_ 3221225472 Aftrtrtmnt2DslOxdtnCtlystDff4776 "Used to identify the applicable J1939-73 FMI detected in the diesel oxidation catalyst differential pressure sensor by the ...";
CM_ SG_ 3221225472 Aftrtrtmnt2DslOxdtnCtlystOtl4775 "Used to identify the applicable J1939-73 FMI detected in the diesel oxidation catalyst outlet gas temperature sensor by ...";
CM_ SG_ 3221225472 Aftrtrtmnt2DslOxdtnCtlystInt4774 "Used to identify the applicable J1939-73 FMI detected in the diesel oxidation catalyst intake gas temperature sensor by ...";
CM_ SG_ 3221225472 Aftrtrtmnt1DslExhstFldTnk2HtrPrl "Used to identify the applicable J1939-73 FMI detected in the diesel exhaust fluid tank 2 heater, by the manufacturer’s ...";
CM_ SG_ 3221225472 Aftrtrtmnt1DslExhstFldTnk2Heater "The diesel exhaust fluid tank 2 heater percentage for aftertreatment system 1 (exhaust bank 1).  0% is off.  See SPN ...";
CM_ SG_ 3221225472 Aftrtrtmnt1DslExhstFldTnk2TmpPrl "Used to identify the applicable J1939-73 FMI detected in the diesel exhaust fluid tank 2 temperature, by the ...";
CM_ SG_ 3221225472 Aftrtrtmnt1DslExhstFldTnk2LvlPrl "Used to identify the applicable J1939-73 FMI detected in the diesel exhaust fluid tank 2 level, by the manufacturer’s ...";
CM_ SG_ 3221225472 Aftrtrtmnt1DslExhstFldTnk2Level2 "The diesel exhaust fluid tank 2 level height in mm for aftertreatment system 1 (exhaust bank 1).  Tank 2 is used as a quick ...";
CM_ SG_ 3221225472 Aftrtrtmnt1DslExhstFlidTank2Temp "The diesel exhaust fluid tank 2 temperature for aftertreatment system 1 (exhaust bank 1).  Tank 2 is used as a quick thaw ...";
CM_ SG_ 3221225472 Aftrtrtmnt1DslExhstFldTank2Level "The diesel exhaust fluid tank 2 level percentage for aftertreatment system 1 (exhaust bank 1).  0% is empty and 100% is ...";
CM_ SG_ 3221225472 Aftrtrtmnt1DslExhstFldTnkDrnVlvC "Commanded percentage of maximum Aftertreatment 1 Diesel Exhaust Fluid Tank Drain Valve opening. 100% means the ...";
CM_ SG_ 3221225472 Aftrtrtmnt1DslExhstFlidPumpState "State of Aftertreatment 1 Diesel Exhaust Fluid dosing pump.";
CM_ SG_ 3221225472 Aftrtrtmnt1DslExhstFldTnkFllVlvC "Commanded percentage of maximum Aftertreatment 1 Diesel Exhaust Fluid Tank Fill Valve opening. 100% means the fill ...";
CM_ SG_ 3221225472 Aftrtrtmnt1DslExhstFldRturnValve "Command to the valve which determines whether the diesel exhaust fluid is delivered to the injector or is routed back to ...";
CM_ SG_ 3221225472 Aftrtrtmnt1DslExhstFldPmpDrvPrcn "The percent (command) sent to the motor to control the speed of the diesel exhaust fluid pump.";
CM_ SG_ 3221225472 Aftrtrtmnt1DslExhstFldPmpMtrSped "Rotational speed of the motor driving a pump for diesel exhaust fluid used in an aftertreatment system.";
CM_ SG_ 3221225472 Aftrtrtmnt1SCRExhstGsDffPrssPrlm "Used to identify the applicable J1939-73 FMI detected in the SCR differential pressure sensor by the manufacturer’s ...";
CM_ SG_ 3221225472 Aftrtrtmnt1SCRExhustGasDiffPress "Exhaust differential pressure measured between the intake and exhaust of an SCR component in exhaust bank 1.";
CM_ SG_ 3221225472 Aftrtrtmnt1DslExhstFldPmpHterCmd "Command for the Aftertreatment 1 Diesel Exhaust Fluid Pump Heater. A value of 0% means no heating applied, a value ...";
CM_ SG_ 3221225472 Aftrtrtmnt1DslExhstFldTnk2HtrCmd "This is the command for the Aftertreatment 1 Diesel Exhaust Fluid Tank 2 Heater.  See SPN 4372 for the measured value ...";
CM_ SG_ 3221225472 Aftrtrtmnt1DslExhstFldTnkHterCmd "Command for the Aftertreatment 1 Diesel Exhaust Fluid Tank Heater.  A value of 0% means no heating applied, a value ...";
CM_ SG_ 3221225472 Aftrtrtmnt1DslExhstFldLneHeater4 "The diesel exhaust fluid line heater 4 request for aftertreatment system 1 (exhaust bank 1).";
CM_ SG_ 3221225472 Aftrtrtmnt1DslExhstFldLneHeater3 "The diesel exhaust fluid line heater 3 request for aftertreatment system 1 (exhaust bank 1).";
CM_ SG_ 3221225472 Aftrtrtmnt1DslExhstFldLneHeater2 "The diesel exhaust fluid line heater 2 request for aftertreatment system 1 (exhaust bank 1).";
CM_ SG_ 3221225472 Aftrtrtmnt1DslExhstFldLneHeater1 "The diesel exhaust fluid line heater 1 request for aftertreatment system 1 (exhaust bank 1).";
CM_ SG_ 3221225472 Aftrtrtmnt1DslExhstFldDsrHtngMdR "Used if multiple heater modes are available in the Doser.";
CM_ SG_ 3221225472 Aftrtrtmnt1DslExhstFldDsrFltSppr "Used if external devices can warn of conditions that require suppression of potential faults in the doser due to ...";
CM_ SG_ 3221225472 Aftrtrtmnt1DslExhstFldRqstdQntty "Represents the command for the diesel exhaust fluid quantity integrator in the dosing control unit ...";
CM_ SG_ 3221225472 Aftrtrtmnt1DslExhstFldDsngRqstdQ "Actual requested dosing quantity of diesel exhaust fluid.";
CM_ SG_ 3221225472 Aftrtrtmnt1DslExhstFldLnHtr4Prlm "Used to identify the applicable J1939-73 FMI detected in the diesel exhaust fluid line heater 4, by the manufacturer’s ...";
CM_ SG_ 3221225472 Aftrtrtmnt1DslExhstFldLnHtr4Stte "The diesel exhaust fluid line heater 4 state for aftertreatment system 1 (exhaust bank 1).";
CM_ SG_ 3221225472 Aftrtrtmnt1DslExhstFldLnHtr3Prlm "Used to identify the applicable J1939-73 FMI detected in the diesel exhaust fluid line heater 3, by the manufacturer’s ...";
CM_ SG_ 3221225472 Aftrtrtmnt1DslExhstFldLnHtr3Stte "The diesel exhaust fluid line heater 3 state for aftertreatment system 1 (exhaust bank 1).";
CM_ SG_ 3221225472 Aftrtrtmnt1DslExhstFldLnHtr2Prlm "Used to identify the applicable J1939-73 FMI detected in the diesel exhaust fluid line heater 2, by the manufacturer’s ...";
CM_ SG_ 3221225472 Aftrtrtmnt1DslExhstFldLnHtr2Stte "The diesel exhaust fluid line heater 2 state for aftertreatment system 1 (exhaust bank 1).";
CM_ SG_ 3221225472 Aftrtrtmnt1DslExhstFldLnHtr1Prlm "Used to identify the applicable J1939-73 FMI detected in the diesel exhaust fluid line heater 1, by the manufacturer’s ...";
CM_ SG_ 3221225472 Aftrtrtmnt1DslExhstFldLnHtr1Stte "The diesel exhaust fluid line heater 1 state for aftertreatment system 1 (exhaust bank 1).";
CM_ SG_ 3221225472 Aftrtrtmnt1DslExhstFldDosingTemp "The diesel exhaust fluid dosing temperature (measured closest to dosing valve) for aftertreatment system 1 (exhaust ...";
CM_ SG_ 3221225472 Aftrtrtmnt1DslExhstFldDsrAbsPrss "The SCR dosing diesel exhaust fluid absolute pressure (measured closest to dosing valve) for aftertreatment system 1 ...";
CM_ SG_ 3221225472 Aftrtrtmnt1DslExhstFldActlQnttyO "The SCR requested diesel exhaust fluid integrator total quantity for aftertreatment system 1 (exhaust bank 1).";
CM_ SG_ 3221225472 Aftrtrtmnt1DslExhstFldActlDsngQn "Actual reducing agent quantity of SCR-system ...";
CM_ SG_ 3221225472 Aftrtrtmnt1GsOxdtnCtlystOtlt4757 "Used to identify the applicable J1939-73 FMI detected in the gas oxidation catalyst outlet gas temperature sensor by the ...";
CM_ SG_ 3221225472 Aftrtrtmnt1GsOxdtnCtlystIntk4756 "Used to identify the applicable J1939-73 FMI detected in the gas oxidation catalyst intake gas temperature sensor by the ...";
CM_ SG_ 3221225472 Aftrtrtmnt1DslOxdtnCtlystDff4770 "Used to identify the applicable J1939-73 FMI detected in the diesel oxidation catalyst differential pressure sensor by the ...";
CM_ SG_ 3221225472 Aftrtrtmnt1DslOxdtnCtlystOtl4769 "Used to identify the applicable J1939-73 FMI detected in the diesel oxidation catalyst outlet gas temperature sensor by ...";
CM_ SG_ 3221225472 Aftrtrtmnt1DslOxdtnCtlystInt4768 "Used to identify the applicable J1939-73 FMI detected in the diesel oxidation catalyst intake gas temperature sensor by ...";
CM_ SG_ 3221225472 EngAxClerSupplyValve2ActuatorCmd "The control command applied to the engine auxiliary cooler supply valve 2 actuator, where 0% represents closed and ...";
CM_ SG_ 3221225472 EngAxClerSupplyValve1ActuatorCmd "The control command applied to the engine auxiliary cooler supply valve 1 actuator, where 0% represents closed and ...";
CM_ SG_ 3221225472 Aftrtrtmnt1AvrgDstncBtwnActvDPFR "Indicates the average distance since last reset between active regenerations, that have not been forced to occur by ...";
CM_ SG_ 3221225472 NOxSensorATO1SelfdiagnosisStatus "Self-diagnosis result status for NOx sensor ATO1 ...";
CM_ SG_ 3221225472 Aftrtrtmnt1DslPrtcltFltrIntk3244 "Used to identify the applicable J1939-73 FMI detected in the diesel particulate filter intake gas temperature sensor by the ...";
CM_ SG_ 3221225472 Aftrtrtmnt1DslPrtcltFltrIntr3254 "Used to identify the applicable J1939-73 FMI detected in the diesel particulate filter intermediate gas temperature sensor ...";
CM_ SG_ 3221225472 NOxSensorATI1SelfdiagnosisStatus "Self-diagnosis result status for NOx sensor ATI1 ...";
CM_ SG_ 3221225472 Aftrtrtmnt2AvrgDstncBtwnActvDPFR "Indicates the average distance since last reset between active regenerations, that have not been forced to occur by ...";
CM_ SG_ 3221225472 NOxSensorATO2SelfdiagnosisStatus "Self-diagnosis result status for NOx sensor ATO2 ...";
CM_ SG_ 3221225472 Aftrtrtmnt2DslPrtcltFltrIntk3278 "Used to identify the applicable J1939-73 FMI detected in the diesel particulate filter intake gas temperature sensor by the ...";
CM_ SG_ 3221225472 Aftrtrtmnt2DslPrtcltFltrIntr3288 "Used to identify the applicable J1939-73 FMI detected in the diesel particulate filter intermediate gas temperature sensor ...";
CM_ SG_ 3221225472 NOxSensorATI2SelfdiagnosisStatus "Self-diagnosis result status for NOx sensor ATI2 ...";
CM_ SG_ 3221225472 BarometricAbsPress "Barometric Absolute Pressure (High Resolution).  See SPN 108 if high resolution is not needed.";
CM_ SG_ 3221225472 CalculatedAmbientAirTemp "Calculated temperature of air surrounding vehicle.  Use SPN 171 for actual measured ambient air temperature.";
CM_ SG_ 3221225472 MinutesAccumulatedMILActivated "Accumulated count (in minutes) while the MIL is activated (on) (SPN=?).";
CM_ SG_ 3221225472 ProprietaryNetwork2 "Identifies the action to be performed on the Proprietary Network #2 communications port.";
CM_ SG_ 3221225472 ProprietaryNetwork1 "Identifies the action to be performed on the Proprietary Network #1 communications port.";
CM_ SG_ 3221225472 AETCTorqueValue14 "Engine torque value of the data points in PGN 64912 – Advertised Engine Torque Curve (AETC).";
CM_ SG_ 3221225472 AETCTorqueValue13 "Engine torque value of the data points in PGN 64912 – Advertised Engine Torque Curve (AETC).";
CM_ SG_ 3221225472 AETCTorqueValue12 "Engine torque value of the data points in PGN 64912 – Advertised Engine Torque Curve (AETC).";
CM_ SG_ 3221225472 AETCTorqueValue11 "Engine torque value of the data points in PGN 64912 – Advertised Engine Torque Curve (AETC).";
CM_ SG_ 3221225472 AETCTorqueValue10 "Engine torque value of the data points in PGN 64912 – Advertised Engine Torque Curve (AETC).";
CM_ SG_ 3221225472 AETCTorqueValue09 "Engine torque value of the data points in PGN 64912 – Advertised Engine Torque Curve (AETC).";
CM_ SG_ 3221225472 AETCTorqueValue08 "Engine torque value of the data points in PGN 64912 – Advertised Engine Torque Curve (AETC).";
CM_ SG_ 3221225472 AETCTorqueValue07 "Engine torque value of the data points in PGN 64912 – Advertised Engine Torque Curve (AETC).";
CM_ SG_ 3221225472 AETCTorqueValue06 "Engine torque value of the data points in PGN 64912 – Advertised Engine Torque Curve (AETC).";
CM_ SG_ 3221225472 AETCTorqueValue05 "Engine torque value of the data points in PGN 64912 – Advertised Engine Torque Curve (AETC).";
CM_ SG_ 3221225472 AETCTorqueValue04 "Engine torque value of the data points in PGN 64912 – Advertised Engine Torque Curve (AETC).";
CM_ SG_ 3221225472 AETCTorqueValue03 "Engine torque value of the data points in PGN 64912 – Advertised Engine Torque Curve (AETC).";
CM_ SG_ 3221225472 AETCTorqueValue02 "Engine torque value of the data points in PGN 64912 – Advertised Engine Torque Curve (AETC).";
CM_ SG_ 3221225472 AETCTorqueValue01 "Engine torque value of the data points in PGN 64912 – Advertised Engine Torque Curve (AETC).";
CM_ SG_ 3221225472 AETCSpeedValue14 "Engine speed value of the data points in PGN 64912 – Advertised Engine Torque Curve (AETC).";
CM_ SG_ 3221225472 AETCSpeedValue13 "Engine speed value of the data points in PGN 64912 – Advertised Engine Torque Curve (AETC).";
CM_ SG_ 3221225472 AETCSpeedValue12 "Engine speed value of the data points in PGN 64912 – Advertised Engine Torque Curve (AETC).";
CM_ SG_ 3221225472 AETCSpeedValue11 "Engine speed value of the data points in PGN 64912 – Advertised Engine Torque Curve (AETC).";
CM_ SG_ 3221225472 AETCSpeedValue10 "Engine speed value of the data points in PGN 64912 – Advertised Engine Torque Curve (AETC).";
CM_ SG_ 3221225472 AETCSpeedValue09 "Engine speed value of the data points in PGN 64912 – Advertised Engine Torque Curve (AETC).";
CM_ SG_ 3221225472 AETCSpeedValue08 "Engine speed value of the data points in PGN 64912 – Advertised Engine Torque Curve (AETC).";
CM_ SG_ 3221225472 AETCSpeedValue07 "Engine speed value of the data points in PGN 64912 – Advertised Engine Torque Curve (AETC).";
CM_ SG_ 3221225472 AETCSpeedValue06 "Engine speed value of the data points in PGN 64912 – Advertised Engine Torque Curve (AETC).";
CM_ SG_ 3221225472 AETCSpeedValue05 "Engine speed value of the data points in PGN 64912 – Advertised Engine Torque Curve (AETC).";
CM_ SG_ 3221225472 AETCSpeedValue04 "Engine speed value of the data points in PGN 64912 – Advertised Engine Torque Curve (AETC).";
CM_ SG_ 3221225472 AETCSpeedValue03 "Engine speed value of the data points in PGN 64912 – Advertised Engine Torque Curve (AETC).";
CM_ SG_ 3221225472 AETCSpeedValue02 "Engine speed value of the data points in PGN 64912 – Advertised Engine Torque Curve (AETC).";
CM_ SG_ 3221225472 AETCSpeedValue01 "Engine speed value of the data points in PGN 64912 – Advertised Engine Torque Curve (AETC).";
CM_ SG_ 3221225472 AETCTorqueValue00 "Engine torque value of the data points in PGN 64912 – Advertised Engine Torque Curve (AETC).";
CM_ SG_ 3221225472 AETCSpeedValue00 "Engine speed value of the data points in PGN 64912 – Advertised Engine Torque Curve (AETC).";
CM_ SG_ 3221225472 TransOilLevel1MeasurementStatus "Measurement status for the first instance of a transmission oil level indicator.  Indicates if conditions are acceptable to ...";
CM_ SG_ 3221225472 TransOilLevel1CountdownTimer "Countdown timer for the first instance of a transmission oil level indicator.  Once all vehicle conditions (such as vehicle ...";
CM_ SG_ 3221225472 TransOilLevel1High_Low "First instance of a transmission oil level indicator. Conveys the amount of current volume of transmission sump oil ...";
CM_ SG_ 3221225472 TransOilTemp1 "First instance of transmission lubricant temperature.";
CM_ SG_ 3221225472 TransOilLevel1 "First instance of a transmission oil level indicator. Conveys the ratio of volume of transmission sump oil to recommended ...";
CM_ SG_ 3221225472 TrailerWeight "Total mass of freight-carrying vehicle designed to be pulled by truck, including the weight of the contents.";
CM_ SG_ 3221225472 ReferenceTirePressSetting "Reference value of the tire pressure setting as basis for the tire pressure monitoring";
CM_ SG_ 3221225472 ReferenceTirePress "Reference value of the tire pressure as basis for the tire pressure monitoring";
CM_ SG_ 3221225472 TirePressThresholdDetection "Signal indicating the pressure level of the tire. The levels defined represent different pressure conditions of the tire:";
CM_ SG_ 3221225472 TireAirLeakageRate "The pressure loss rate of a tire.";
CM_ SG_ 3221225472 CTIWheelEndElectricalFault "Indicates the status of electrical fault on CTI wheel interface.";
CM_ SG_ 3221225472 CTITireStatus "Indicates the status of the tire.";
CM_ SG_ 3221225472 CTIWheelSensorStatus "Indicates whether the wheel is being monitored by the CTI controller.";
CM_ SG_ 3221225472 TireTemp "Temperature at the surface of the tire sidewall.";
CM_ SG_ 3221225472 TirePress "Pressure at which air is contained in cavity formed by tire and rim.";
CM_ SG_ 3221225472 EngTurningGearEngaged "Status signal which indicates that the turning gear is engaged. The turning gear is used to turn the flywheel/crankshaft,";
CM_ SG_ 3221225472 AuxInputEnable "Auxiliary Input EnableAuxiliary Input EnableAuxiliary Input Enable";
CM_ SG_ 3221225472 AuxModelIdentification "Model Identification Code of the Auxiliary Input Unit";
CM_ SG_ 3221225472 AuxErrorInvalidInputID "Invalid Auxiliary Input Object ID";
CM_ SG_ 3221225472 AuxErrorAnyOther "Any other error";
CM_ SG_ 3221225472 MessageChecksum "The message checksum is used to verify the signal path from the transmitting device to the receiving device.";
CM_ SG_ 3221225472 MessageCounter "The message counter is used to detect situations where the transmitting ECU malfunction repeats the same frame all the";
CM_ SG_ 3221225472 EngRequestedTorqueHighResolution "This parameter displays an additional torque in percent of the reference engine torque.";
CM_ SG_ 3221225472 TSC1CtrlPurpose "State signal which indicates which control mode the sending device is using to generate the TSC1 command. Note that";
CM_ SG_ 3221225472 TSC1TransRate "This parameter indicates the transmission rate at which the sending device will transmit the TSC1 message. The engine";
CM_ SG_ 3221225472 EngRequestedTorque_TorqueLimit "Parameter provided to the engine or retarder in the torque/speed control message for controlling or limiting the output";
CM_ SG_ 3221225472 EngRequestedSpeed_SpeedLimit "Parameter provided to the engine from external sources in the torque/speed control message. This is the engine speed";
CM_ SG_ 3221225472 OverrideCtrlModePriority "This field is used as an input to the engine or retarder to determine the priority of the Override Control Mode received in";
CM_ SG_ 3221225472 EngRequestedSpeedCtrlConditions "This mode tells the engine control system the governor characteristics that are desired during speed control. The four";
CM_ SG_ 3221225472 EngOverrideCtrlMode "The override control mode defines which sort of command is used:";
CM_ BO_ 2566838782 "Notes:";
CM_ SG_ 2566838782 AuxI_OChannel2 "Auxiliary channel of data (16 bit) read by the ECU. This data is in A/D counts and is manufacturer specific. It may be";
CM_ SG_ 2566838782 AuxI_OChannel1 "Auxiliary channel of data (16 bit) read by the ECU. This data is in A/D counts and is manufacturer specific. It may be";
CM_ SG_ 2566838782 AuxI_O13 "Identifies the current status of auxiliary input/output functions that are configured uniquely per application.";
CM_ SG_ 2566838782 AuxI_O14 "Identifies the current status of auxiliary input/output functions that are configured uniquely per application.";
CM_ SG_ 2566838782 AuxI_O15 "Identifies the current status of auxiliary input/output functions that are configured uniquely per application.";
CM_ SG_ 2566838782 AuxI_O16 "Identifies the current status of auxiliary input/output functions that are configured uniquely per application.";
CM_ SG_ 2566838782 AuxI_O09 "Identifies the current status of auxiliary input/output functions that are configured uniquely per application.";
CM_ SG_ 2566838782 AuxI_O10 "Identifies the current status of auxiliary input/output functions that are configured uniquely per application.";
CM_ SG_ 2566838782 AuxI_O11 "Identifies the current status of auxiliary input/output functions that are configured uniquely per application.";
CM_ SG_ 2566838782 AuxI_O12 "Identifies the current status of auxiliary input/output functions that are configured uniquely per application.";
CM_ SG_ 2566838782 AuxI_O05 "Identifies the current status of auxiliary input/output functions that are configured uniquely per application.";
CM_ SG_ 2566838782 AuxI_O06 "Identifies the current status of auxiliary input/output functions that are configured uniquely per application.";
CM_ SG_ 2566838782 AuxI_O07 "Identifies the current status of auxiliary input/output functions that are configured uniquely per application.";
CM_ SG_ 2566838782 AuxI_O08 "Identifies the current status of auxiliary input/output functions that are configured uniquely per application.";
CM_ SG_ 2566838782 AuxI_O01 "Identifies the current status of auxiliary input/output functions that are configured uniquely per application.";
CM_ SG_ 2566838782 AuxI_O02 "Identifies the current status of auxiliary input/output functions that are configured uniquely per application.";
CM_ SG_ 2566838782 AuxI_O03 "Identifies the current status of auxiliary input/output functions that are configured uniquely per application.";
CM_ SG_ 2566838782 AuxI_O04 "Identifies the current status of auxiliary input/output functions that are configured uniquely per application.";
CM_ BO_ 2566862080 "Engine Hours and Status";
CM_ BO_ 2566878976 "Aftertreatment Hours and Status";
CM_ BO_ 2565865272 "Proprietary A";
CM_ BO_ 2565865246 "Proprietary A";
CM_ BO_ 2565865214 "Proprietary A";
CM_ BO_ 2559115006 "Message used to request the wireless transceiver to transmit a special beacon signal and to report ...";
CM_ SG_ 2559115006 WirelessSignalStrength2 "The absolute received signal strength of the special beacon signal received from the off-board transmitter. The signal ...";
CM_ SG_ 2559115006 TransmitterID2 "The ID of the off-board transmitter that sent the incoming special beacon message received by the wireless transceiver.";
CM_ SG_ 2559115006 RadioBeaconDirection "Indicates the function of a particular instance of the Radio Beacon Request message. The 'Beacon Request' state ...";
CM_ SG_ 2559115006 UnqBeaconMessageIdentifierNumber "The number is used to identify a wireless message originating from a device on a particular machine. Within a beacon ...";
CM_ BO_ 2566707454 "This message is used to specify up to 4 soot sensor analysis frequencies to request the soot sensor signal data ...";
CM_ SG_ 2566707454 Aftrtrtmnt1DslPrtcltFltr2StS5647 "Fourth requested analysis frequency for the diesel particulate filter 2 soot sensor.";
CM_ SG_ 2566707454 Aftrtrtmnt1DslPrtcltFltr2StS5646 "Third requested analysis frequency for the diesel particulate filter 2 soot sensor.";
CM_ SG_ 2566707454 Aftrtrtmnt1DslPrtcltFltr2StS5645 "Second requested analysis frequency for the diesel particulate filter 2 soot sensor.";
CM_ SG_ 2566707454 Aftrtrtmnt1DslPrtcltFltr2StSnsrA "The analysis frequency associated with the frequency 3 soot signal for the diesel particulate filter 2 soot sensor.  See ...";
CM_ BO_ 2566707198 "This message is used report the analysis frequency and associated soot sensor signal data for two of the requested ...";
CM_ SG_ 2566707198 Aftrtrtmnt1DslPrtcltFltr2StS5651 "The soot signal attenuation measurement for analysis frequency 2 for the diesel particulate filter 2 soot sensor.  See SPN ...";
CM_ SG_ 2566707198 Aftrtrtmnt1DslPrtcltFltr2StS5650 "The analysis frequency associated with the frequency 2 soot signal for the diesel particulate filter 2 soot sensor.  See ...";
CM_ SG_ 2566707198 Aftrtrtmnt1DslPrtcltFltr2StSnsrF "The soot signal attenuation measurement for analysis frequency 3 for the diesel particulate filter 2 soot sensor.  See SPN ...";
CM_ SG_ 2566707198 Aftrtrtmnt1DslPrtcltFltr2StSnsrA "The analysis frequency associated with the frequency 3 soot signal for the diesel particulate filter 2 soot sensor.  See ...";
CM_ BO_ 2566706942 "Diesel particulate filter soot parameters for the aftertreatment 1 diesel particulate filter 2.";
CM_ SG_ 2566706942 Aftrtrtmnt1DslPrtcltFltr2StS5655 "The soot signal attenuation measurement for analysis frequency 4 for the diesel particulate filter 2 soot sensor.  See SPN ...";
CM_ SG_ 2566706942 Aftrtrtmnt1DslPrtcltFltr2StS5654 "The analysis frequency associated with the frequency 4 soot signal for the diesel particulate filter 2 soot sensor.  See ...";
CM_ SG_ 2566706942 Aftrtrtmnt1DslPrtcltFltr2StSnsrF "The soot signal attenuation measurement for analysis frequency 3 for the diesel particulate filter 2 soot sensor.  See SPN ...";
CM_ SG_ 2566706942 Aftrtrtmnt1DslPrtcltFltr2StSnsrA "The analysis frequency associated with the frequency 3 soot signal for the diesel particulate filter 2 soot sensor.  See ...";
CM_ BO_ 2559770366 "This PGN contains information about the HC Doser and the Diesel Particulate Filter ...";
CM_ SG_ 2559770366 HydrocarbonDoserPurgingNeeded "Purging of the Hydrocarbon Doser (HCD) is needed.  Request could come from the HCD system.";
CM_ SG_ 2559770366 DiagnosticStatusOfHCDoser "Indicates whether an error is active in the Hydrocarbon Doser (HCD) or whether the internal cyclic system test of the HCD ...";
CM_ SG_ 2559770366 HCDoserInjectingStatus "Indicates whether the Hydrocarbon Doser (HCD) is presently injecting diesel fuel into the exhaust pipe.";
CM_ SG_ 2559770366 HCDoserStatus "Indicates whether the HC Doser/ HC Dosing system is enabled or is waiting for regeneration.";
CM_ SG_ 2559770366 RequestedFuelMassRate "Requested fuel dosing quantity from hydrocarbon doser.";
CM_ BO_ 2559704830 "Used to command a vehicle/chassis lubrication system ...";
CM_ SG_ 2559704830 LubricationTimingCycleCmd "Command signal to enable or pause the lubrication activation clock ...";
CM_ SG_ 2559704830 LubricationPumpEnableCmd "Command signal to reset the lubrication pump.  It allows the operator and/or technician to reset the paused lubrication ...";
CM_ SG_ 2559704830 LubricationOperationModeSetCmd "Command signal to change lubrication system operational mode. The mode set command gives the operator and/or ...";
CM_ SG_ 2559704830 LubricationCycleSetCmd "Command signal to change the lubrication cycle. It gives the operator or technician the ability to the change the frequency ...";
CM_ SG_ 2559704830 LubricationCycleModeLockCmd "Command signal to lock or unlock the ability to change the lubrication cycle mode.  Locking the lubrication mode would ...";
CM_ BO_ 2559639294 "Command message to control the speed and direction of Supplemental Fan for additional cooling beyond that of the ...";
CM_ SG_ 2559639294 SupplementalFanPowerHold "Command to allow the supplemental fan controller to remain alive independently of the electrical enable input to the fan.";
CM_ SG_ 2559639294 SupplementalFanSpeedCmd "Speed command to Supplemental Fan.";
CM_ SG_ 2559639294 SupplementalFanDirectionCmd "Direction command to the Supplemental Fan. Fan can be commanded to run forward or reverse.";
CM_ SG_ 2559639294 SupplementalFanEnableCmd "Enable/Disable command to Supplemental Fan.";
CM_ BO_ 2559573758 "This PGN contains parameters that are used to configure engine operation.";
CM_ SG_ 2559573758 ClntLvlEngPrtctnShtdwnOvrrideCmd "Overrides the engine protection shutdown functionality due to low coolant level.";
CM_ BO_ 2349530878 "Cruise Control / Vehicle Speed 2 ...";
CM_ SG_ 2349530878 CruiseCtrlPauseCmd "This parameter is used to temporarily disable cruise control from a source other than the driver controlled switch if cruise ...";
CM_ SG_ 2349530878 CruiseCtrlResumeCmd "This parameter is used to request the cruise control to resume operation from a source other than the driver controlled ...";
CM_ SG_ 2349530878 CruiseCtrlDisableCmd "This parameter is used to disable cruise control from a source other than the driver controlled switch if cruise control is ...";
CM_ BO_ 2365428734 "Message for the generator set control to change or report the status of the generator system.";
CM_ SG_ 2365428734 GenFrequencySelection "Command  from  user  and/or  generator  control  system  for  the  genset (engine) to target operations for 50 Hz, 60 Hz, or 400 Hz.";
CM_ SG_ 2365428734 GenGoverningSpeedCommand "Command from user and/or generator control system for the genset (engine) to govern to low idle or rated base speed setpoints.";
CM_ SG_ 2365428734 GenAlternatorEfficiency "Measured,  calculated,  and/or  estimated  operating  efficiency  of  the  generator  alternator.";
CM_ SG_ 2365428734 GenNotReadyToAutoParaState "This parameter indicates whether or not all systems required to start the engine and close to the bus are prepared to operate automatically.";
CM_ SG_ 2365428734 GenCtrlNotInAutoStartState "This parameter indicates whether or not the generator set is in a condition to automatically start up and provide power.";
CM_ SG_ 2365428734 RequestedEngineControlMode "This parameter is used to request a change to the engine control mode.";
CM_ BO_ 2566702846 "OBD Information.";
CM_ SG_ 2566702846 EngOBDWarmUpSequence "Engine warm-up as defined by the applicable region's regulatory agency.";
CM_ BO_ 2566703102 "Model Year and Certification Engine Family.";
CM_ SG_ 2566703102 CertificationEngineFamilyName "The regulated family name per the applicable certification agency.";
CM_ SG_ 2566703102 ModelYear "The compliance model year of the OBD system of the engine and or vehicle.";
CM_ BO_ 2566705918 "Previously Active Service Only DTCs.";
CM_ SG_ 2566705918 DTC1 "Diagnostic Trouble Code";
CM_ SG_ 2566705918 FlashProtectLamp "This parameter provides the capability to flash the engine protect lamp (SPN 3041).";
CM_ SG_ 2566705918 FlashAmberWarningLamp "This parameter provides the capability to flash the AWL (SPN 3040). ";
CM_ SG_ 2566705918 FlashRedStopLamp "This parameter provides the capability to flash the RSL (SPN 3039).";
CM_ SG_ 2566705918 FlashMalfuncIndicatorLamp "This parameter provides the capability to flash the MIL (SPN 3038).";
CM_ SG_ 2566705918 ProtectLampStatus "This lamp is used to relay trouble code informatio that is reporting a problem with a vehicle system that is most
probably not electronic subsystem related.";
CM_ SG_ 2566705918 AmberWarningLampStatus "This lamp is used to relay trouble code information that is reporting a problem with the vehicle system but the vehicle need
not be immediately stopped.";
CM_ SG_ 2566705918 RedStopLampState "This lamp is uesed to relay trouble code information that is of a severe enought condition that it warrants stopping the vehicle.";
CM_ SG_ 2566705918 MalfunctionIndicatorLampStatus "A lamp used to relay only emissions-related trouble code information.";
CM_ BO_ 2566705662 "Active Service Only DTCs.";
CM_ SG_ 2566705662 DTC1 "Diagnostic Trouble Code";
CM_ SG_ 2566705662 FlashProtectLamp "This parameter provides the capability to flash the engine protect lamp (SPN 3041).";
CM_ SG_ 2566705662 FlashAmberWarningLamp "This parameter provides the capability to flash the AWL (SPN 3040). ";
CM_ SG_ 2566705662 FlashRedStopLamp "This parameter provides the capability to flash the RSL (SPN 3039).";
CM_ SG_ 2566705662 FlashMalfuncIndicatorLamp "This parameter provides the capability to flash the MIL (SPN 3038).";
CM_ SG_ 2566705662 ProtectLampStatus "This lamp is used to relay trouble code informatio that is reporting a problem with a vehicle system that is most
probably not electronic subsystem related.";
CM_ SG_ 2566705662 AmberWarningLampStatus "This lamp is used to relay trouble code information that is reporting a problem with the vehicle system but the vehicle need
not be immediately stopped.";
CM_ SG_ 2566705662 RedStopLampState "This lamp is uesed to relay trouble code information that is of a severe enought condition that it warrants stopping the vehicle.";
CM_ SG_ 2566705662 MalfunctionIndicatorLampStatus "A lamp used to relay only emissions-related trouble code information.";
CM_ BO_ 2566706174 "Diagnostic Data Clear/Reset for All Service Only DTCs.";
CM_ BO_ 2349465342 "Contains Static Roll Angle Data and Status of the Static Roll Angle Sensor ...";
CM_ SG_ 2349465342 StaticRollAngleStatus "Status of the transmitted roll angle data.";
CM_ SG_ 2349465342 StaticRollAngle "The measured static roll angle between the vehicle y-axis and the ground plane about the X-axis.  The sign of the roll ...";
CM_ SG_ 2566767614 AccelPedal2Channel3 "Sensor output 3 for the accelerator pedal #2 position when using a redundant-style sensor.  The ratio of actual ...";
CM_ SG_ 2566767614 AccelPedal2Channel2 "Sensor output 2 for the accelerator pedal #2 position when using a redundant-style sensor.  The ratio of actual ...";
CM_ SG_ 2566767614 AccelPedal1Channel3 "Sensor output 3 for the accelerator pedal #1 position when using a redundant-style sensor.  The ratio of actual ...";
CM_ SG_ 2566767614 AccelPedal1Channel2 "Sensor output 2 for the accelerator pedal #1 position when using a redundant-style sensor.  The ratio of actual ...";
CM_ SG_ 2559049470 DesiredEngFuelingState "Devices send this request to the engine controller to: (a) Shut off engine fueling, but remain prepared to re-start quickly by not shutting down the control system, or ...";
BA_DEF_ BO_  "GenMsgCycleTimeFast" INT 0 3600000;
BA_DEF_ BU_  "ISO11783IOPVersion" ENUM  "0","1","2","3","4";
BA_DEF_ BU_  "ISO11783PDDVersion" ENUM  "0","1","2","3";
BA_DEF_ SG_  "SigType" ENUM  "Default","Range","RangeSigned","ASCII","Discrete","Control","ReferencePGN","DTC","StringDelimiter","StringLength","StringLengthControl";
BA_DEF_ SG_  "GenSigStartValue" INT 0 10000;
BA_DEF_ SG_  "GenSigSendType" ENUM  "Cyclic","OnWrite","reserved","OnChange","reserved","reserved","reserved","NoSigSendType";
BA_DEF_ SG_  "GenSigILSupport" ENUM  "Yes","No";
BA_DEF_ SG_  "GenSigEVName" STRING ;
BA_DEF_ SG_  "SPN" INT 0 524287;
BA_DEF_ SG_  "DDI" INT 0 65535;
BA_DEF_ SG_  "SAEDocument" STRING ;
BA_DEF_ BO_  "GenMsgStartDelayTime" INT 0 100000;
BA_DEF_ BO_  "GenMsgILSupport" ENUM  "Yes","No";
BA_DEF_ BO_  "GenMsgRequestable" INT 0 1;
BA_DEF_ BO_  "GenMsgSendType" ENUM  "cyclic","reserved","cyclicIfActive","reserved","reserved","reserved","reserved","reserved","noMsgSendType";
BA_DEF_ BO_  "VFrameFormat" ENUM  "StandardCAN","ExtendedCAN","reserved","J1939PG";
BA_DEF_ BO_  "SingleFrame" INT 0 1;
BA_DEF_ BO_  "GenMsgCycleTime" INT 0 3600000;
BA_DEF_ BO_  "SAE_Document" STRING ;
BA_DEF_ BU_  "NmStationAddress" INT 0 255;
BA_DEF_ BU_  "NmJ1939AAC" INT 0 1;
BA_DEF_ BU_  "NmJ1939IndustryGroup" INT 0 7;
BA_DEF_ BU_  "NmJ1939System" INT 0 127;
BA_DEF_ BU_  "NmJ1939SystemInstance" INT 0 15;
BA_DEF_ BU_  "NmJ1939Function" INT 0 255;
BA_DEF_ BU_  "NmJ1939FunctionInstance" INT 0 7;
BA_DEF_ BU_  "NmJ1939ECUInstance" INT 0 3;
BA_DEF_ BU_  "NmJ1939ManufacturerCode" INT 0 2047;
BA_DEF_ BU_  "NmJ1939IdentityNumber" INT 0 2097151;
BA_DEF_  "DatabaseVersion" STRING ;
BA_DEF_  "BusType" STRING ;
BA_DEF_  "ProtocolType" STRING ;
BA_DEF_  "SAE_J1939_75_SpecVersion" STRING ;
BA_DEF_  "SAE_J1939_21_SpecVersion" STRING ;
BA_DEF_  "SAE_J1939_73_SpecVersion" STRING ;
BA_DEF_  "SAE_J1939_71_SpecVersion" STRING ;
BA_DEF_ SG_  "SystemSignalLongSymbol" STRING ;
BA_DEF_DEF_  "GenMsgCycleTimeFast" 0;
BA_DEF_DEF_  "ISO11783IOPVersion" "3";
BA_DEF_DEF_  "ISO11783PDDVersion" "3";
BA_DEF_DEF_  "SigType" "Default";
BA_DEF_DEF_  "GenSigStartValue" 0;
BA_DEF_DEF_  "GenSigSendType" "NoSigSendType";
BA_DEF_DEF_  "GenSigILSupport" "Yes";
BA_DEF_DEF_  "GenSigEVName" "Env@Nodename_@Signame";
BA_DEF_DEF_  "SPN" 0;
BA_DEF_DEF_  "DDI" 0;
BA_DEF_DEF_  "SAEDocument" "";
BA_DEF_DEF_  "GenMsgStartDelayTime" 0;
BA_DEF_DEF_  "GenMsgILSupport" "Yes";
BA_DEF_DEF_  "GenMsgRequestable" 1;
BA_DEF_DEF_  "GenMsgSendType" "noMsgSendType";
BA_DEF_DEF_  "VFrameFormat" "J1939PG";
BA_DEF_DEF_  "SingleFrame" 1;
BA_DEF_DEF_  "GenMsgCycleTime" 0;
BA_DEF_DEF_  "SAE_Document" "";
BA_DEF_DEF_  "NmStationAddress" 254;
BA_DEF_DEF_  "NmJ1939AAC" 0;
BA_DEF_DEF_  "NmJ1939IndustryGroup" 0;
BA_DEF_DEF_  "NmJ1939System" 0;
BA_DEF_DEF_  "NmJ1939SystemInstance" 0;
BA_DEF_DEF_  "NmJ1939Function" 0;
BA_DEF_DEF_  "NmJ1939FunctionInstance" 0;
BA_DEF_DEF_  "NmJ1939ECUInstance" 0;
BA_DEF_DEF_  "NmJ1939ManufacturerCode" 0;
BA_DEF_DEF_  "NmJ1939IdentityNumber" 0;
BA_DEF_DEF_  "DatabaseVersion" "";
BA_DEF_DEF_  "BusType" "";
BA_DEF_DEF_  "ProtocolType" "";
BA_DEF_DEF_  "SAE_J1939_75_SpecVersion" "";
BA_DEF_DEF_  "SAE_J1939_21_SpecVersion" "";
BA_DEF_DEF_  "SAE_J1939_73_SpecVersion" "";
BA_DEF_DEF_  "SAE_J1939_71_SpecVersion" "";
BA_DEF_DEF_  "SystemSignalLongSymbol" "";
BA_ "DatabaseVersion" "7.5";
BA_ "BusType" "CAN";
BA_ "ProtocolType" "J1939";
BA_ "SAE_J1939_75_SpecVersion" "2005-10";
BA_ "SAE_J1939_21_SpecVersion" "2006-10";
BA_ "SAE_J1939_73_SpecVersion" "2010-10";
BA_ "SAE_J1939_71_SpecVersion" "2010-10";
BA_ "NmStationAddress" BU_ SteeringControlModule 16;
BA_ "NmStationAddress" BU_ SteeringController 128;
BA_ "NmJ1939Function" BU_ SteeringController 129;
BA_ "NmJ1939IndustryGroup" BU_ SteeringController 2;
BA_ "NmJ1939System" BU_ SteeringController 1;
BA_ "NmJ1939ManufacturerCode" BU_ SteeringController 57;
BA_ "NmJ1939IdentityNumber" BU_ SteeringController 201001;
BA_ "NmStationAddress" BU_ SteeringColumnUnit 77;
BA_ "NmJ1939Function" BU_ SteeringColumnUnit 57;
BA_ "NmJ1939ManufacturerCode" BU_ RearAxleSteeringController 57;
BA_ "NmJ1939Function" BU_ RearAxleSteeringController 129;
BA_ "NmJ1939IndustryGroup" BU_ RearAxleSteeringController 2;
BA_ "NmStationAddress" BU_ RearAxleSteeringController 56;
BA_ "NmJ1939System" BU_ RearAxleSteeringController 1;
BA_ "NmStationAddress" BU_ Engine 0;
BA_ "NmJ1939ManufacturerCode" BU_ Engine 102;
BA_ "NmStationAddress" BU_ ChassisController 30;
BA_ "NmJ1939Function" BU_ ChassisController 52;
BA_ "GenMsgSendType" BO_ 2566838782 0;
BA_ "GenMsgCycleTime" BO_ 2566838782 100;
BA_ "SAE_Document" BO_ 2566838782 "J1939-71";
BA_ "GenMsgCycleTime" BO_ 2566862080 50;
BA_ "GenMsgSendType" BO_ 2566862080 0;
BA_ "GenMsgCycleTime" BO_ 2566878976 500;
BA_ "GenMsgSendType" BO_ 2566878976 0;
BA_ "VFrameFormat" BO_ 769 0;
BA_ "GenMsgCycleTime" BO_ 769 20;
BA_ "GenMsgCycleTime" BO_ 2565865272 100;
BA_ "GenMsgCycleTime" BO_ 2565865246 100;
BA_ "GenMsgCycleTime" BO_ 2565865214 100;
BA_ "GenMsgCycleTime" BO_ 2566707454 1000;
BA_ "GenMsgCycleTime" BO_ 2566707198 1000;
BA_ "GenMsgCycleTime" BO_ 2566706942 1000;
BA_ "GenMsgCycleTime" BO_ 2559770366 100;
BA_ "GenMsgCycleTime" BO_ 2559639294 1000;
BA_ "GenMsgCycleTime" BO_ 2559573758 10000;
BA_ "GenMsgCycleTime" BO_ 2349530878 100;
BA_ "GenMsgCycleTime" BO_ 2365428734 100;
BA_ "GenMsgCycleTime" BO_ 2349465342 100;
BA_ "GenMsgCycleTime" BO_ 2559049470 1000;
BA_ "SPN" SG_ 3221225472 CabNoiseCtrlTuningCmd 5058;
BA_ "SigType" SG_ 3221225472 CabNoiseCtrlCmd 5;
BA_ "SPN" SG_ 3221225472 CabNoiseCtrlCmd 5057;
BA_ "SigType" SG_ 3221225472 MagnetGeneratorCtrl 5;
BA_ "SPN" SG_ 3221225472 MagnetGeneratorCtrl 5551;
BA_ "SigType" SG_ 3221225472 SpecialIgnitorLoop62Resistance 1;
BA_ "SPN" SG_ 3221225472 SpecialIgnitorLoop62Resistance 4889;
BA_ "SPN" SG_ 3221225472 EngExhstBckPressRegulatorCtrlCmd 649;
BA_ "SigType" SG_ 3221225472 EngExhaustBackPressActuator1Temp 1;
BA_ "SPN" SG_ 3221225472 EngExhaustBackPressActuator1Temp 5790;
BA_ "SPN" SG_ 3221225472 EngExhstBckPrssActtor1DesiredPos 5789;
BA_ "SigType" SG_ 3221225472 EngTurboWastegateActuator1Temp 1;
BA_ "SPN" SG_ 3221225472 EngTurboWastegateActuator1Temp 5788;
BA_ "SPN" SG_ 3221225472 EngExhstBckPrssRgltrCtrlOprtnStt 5628;
BA_ "SPN" SG_ 3221225472 EngExhstBckPrssRglatorTempStatus 5627;
BA_ "SPN" SG_ 3221225472 EngExhstBckPrssRgltrPrlminaryFMI 5626;
BA_ "SigType" SG_ 3221225472 EngExhaustBackPressRegulatorPos 1;
BA_ "SPN" SG_ 3221225472 EngExhaustBackPressRegulatorPos 5625;
BA_ "SigType" SG_ 3221225472 EngTrbCmprssrBypassActuator2Temp 1;
BA_ "SPN" SG_ 3221225472 EngTrbCmprssrBypassActuator2Temp 5792;
BA_ "SigType" SG_ 3221225472 EngTrbCmprssrBypassActuator1Temp 1;
BA_ "SPN" SG_ 3221225472 EngTrbCmprssrBypassActuator1Temp 5791;
BA_ "SigType" SG_ 3221225472 EngCoolantPress2 1;
BA_ "SPN" SG_ 3221225472 EngCoolantPress2 5708;
BA_ "SPN" SG_ 3221225472 EngExhstGsRcrcltn2Valve2PosError 5832;
BA_ "SPN" SG_ 3221225472 EngExhstGsRcrcltn2Valve1PosError 5831;
BA_ "SigType" SG_ 3221225472 DslPrtcltFltr1CndtnsNtMtFrActvRg 5;
BA_ "SPN" SG_ 3221225472 DslPrtcltFltr1CndtnsNtMtFrActvRg 3750;
BA_ "SigType" SG_ 3221225472 DslPrtcltFltrActvRgnrtnInhbt5629 5;
BA_ "SPN" SG_ 3221225472 DslPrtcltFltrActvRgnrtnInhbt5629 5629;
BA_ "SigType" SG_ 3221225472 HydrocarbonDoserPurgingEnable 5;
BA_ "SPN" SG_ 3221225472 HydrocarbonDoserPurgingEnable 5504;
BA_ "SigType" SG_ 3221225472 DslPrtcltFltrActvRgnrtnInhbt3717 5;
BA_ "SPN" SG_ 3221225472 DslPrtcltFltrActvRgnrtnInhbt3717 3717;
BA_ "SigType" SG_ 3221225472 DslPrtcltFltrActvRgnrtnInhbtdDTE 5;
BA_ "SPN" SG_ 3221225472 DslPrtcltFltrActvRgnrtnInhbtdDTE 3716;
BA_ "SigType" SG_ 3221225472 DslPrtcltFltrActvRgnrtnInhbt3715 4;
BA_ "SPN" SG_ 3221225472 DslPrtcltFltrActvRgnrtnInhbt3715 3715;
BA_ "SigType" SG_ 3221225472 DslPrtcltFltrActvRgnrtnInhbt3713 5;
BA_ "SPN" SG_ 3221225472 DslPrtcltFltrActvRgnrtnInhbt3713 3713;
BA_ "SigType" SG_ 3221225472 DslPrtcltFltrActvRgnrtnInhbt3712 5;
BA_ "SPN" SG_ 3221225472 DslPrtcltFltrActvRgnrtnInhbt3712 3712;
BA_ "SigType" SG_ 3221225472 DslPrtcltFltrActvRgnrtnInhbt3710 5;
BA_ "SPN" SG_ 3221225472 DslPrtcltFltrActvRgnrtnInhbt3710 3710;
BA_ "SigType" SG_ 3221225472 DslPrtcltFltrActvRgnrtnInhbtdDTV 5;
BA_ "SPN" SG_ 3221225472 DslPrtcltFltrActvRgnrtnInhbtdDTV 3709;
BA_ "SigType" SG_ 3221225472 DslPrtcltFltrActvRgnrtnInhbtdDTO 5;
BA_ "SPN" SG_ 3221225472 DslPrtcltFltrActvRgnrtnInhbtdDTO 3708;
BA_ "SigType" SG_ 3221225472 DslPrtcltFltr2StSnsrECUIntrnlTmp 1;
BA_ "SPN" SG_ 3221225472 DslPrtcltFltr2StSnsrECUIntrnlTmp 5570;
BA_ "SigType" SG_ 3221225472 DslPrtcltFltr1StSnsrECUIntrnlTmp 1;
BA_ "SPN" SG_ 3221225472 DslPrtcltFltr1StSnsrECUIntrnlTmp 5569;
BA_ "SigType" SG_ 3221225472 Aftrtrtmnt1SCROprtrIndcmntActvTr 1;
BA_ "SPN" SG_ 3221225472 Aftrtrtmnt1SCROprtrIndcmntActvTr 5463;
BA_ "SigType" SG_ 3221225472 Aftrtrtmnt1SCRCnvrsionEfficiency 1;
BA_ "SPN" SG_ 3221225472 Aftrtrtmnt1SCRCnvrsionEfficiency 4364;
BA_ "SPN" SG_ 3221225472 Aftrtrtmnt1CmmnddDslExhstFldCnsm 3828;
BA_ "SigType" SG_ 3221225472 Aftrtrtmnt1DslExhstFldAvrgCnsmpt 1;
BA_ "SPN" SG_ 3221225472 Aftrtrtmnt1DslExhstFldAvrgCnsmpt 3826;
BA_ "SPN" SG_ 3221225472 TransOilLevel2MeasurementStatus 5916;
BA_ "SPN" SG_ 3221225472 TransOilLevel2CountdownTimer 5915;
BA_ "SigType" SG_ 3221225472 TransOilLevel2High_Low 1;
BA_ "SPN" SG_ 3221225472 TransOilLevel2High_Low 5914;
BA_ "SigType" SG_ 3221225472 TransOilTemp2 1;
BA_ "SPN" SG_ 3221225472 TransOilTemp2 5913;
BA_ "SigType" SG_ 3221225472 EngIntakeManifold1AbsPress4817 1;
BA_ "SPN" SG_ 3221225472 EngIntakeManifold1AbsPress4817 4817;
BA_ "SPN" SG_ 3221225472 FuelEnergyContent 4245;
BA_ "SPN" SG_ 3221225472 ReferenceEngGasMassFlowRate 5684;
BA_ "SPN" SG_ 3221225472 Aftrtrtmnt1DslExhstFluidProperty 3521;
BA_ "SigType" SG_ 3221225472 Aftrtrtmnt1DslExhstFldCndctivity 1;
BA_ "SPN" SG_ 3221225472 Aftrtrtmnt1DslExhstFldCndctivity 3518;
BA_ "SigType" SG_ 3221225472 Aftrtrtmnt1DslExhstFldCncntrtion 1;
BA_ "SPN" SG_ 3221225472 Aftrtrtmnt1DslExhstFldCncntrtion 3516;
BA_ "SigType" SG_ 3221225472 Aftrtrtmnt1DselExhaustFluidTemp2 1;
BA_ "SPN" SG_ 3221225472 Aftrtrtmnt1DselExhaustFluidTemp2 3515;
BA_ "SPN" SG_ 3221225472 DataSecurityParameter 1597;
BA_ "SigType" SG_ 3221225472 TrailerVDCActive 5;
BA_ "SPN" SG_ 3221225472 TrailerVDCActive 5624;
BA_ "SigType" SG_ 3221225472 TransLoadReductionInhibitRq 5;
BA_ "SPN" SG_ 3221225472 TransLoadReductionInhibitRq 5762;
BA_ "SigType" SG_ 3221225472 ClntLvlEngPrtctionShutdownStatus 5;
BA_ "SPN" SG_ 3221225472 ClntLvlEngPrtctionShutdownStatus 5566;
BA_ "SigType" SG_ 3221225472 ServiceComponentIdentificatio913 1;
BA_ "SPN" SG_ 3221225472 ServiceComponentIdentificatio913 913;
BA_ "SigType" SG_ 3221225472 ServiceComponentIdentificatio912 1;
BA_ "SPN" SG_ 3221225472 ServiceComponentIdentificatio912 912;
BA_ "SigType" SG_ 3221225472 EngThrottleValveDiffPress 1;
BA_ "SPN" SG_ 3221225472 EngThrottleValveDiffPress 5631;
BA_ "SigType" SG_ 3221225472 EngFuelCtrlCtrlMode 5;
BA_ "SPN" SG_ 3221225472 EngFuelCtrlCtrlMode 5323;
BA_ "SigType" SG_ 3221225472 EmergencyBrakingActive 5;
BA_ "SPN" SG_ 3221225472 EmergencyBrakingActive 5847;
BA_ "SigType" SG_ 3221225472 EngExRangeCoolantPress 1;
BA_ "SPN" SG_ 3221225472 EngExRangeCoolantPress 20;
BA_ "SigType" SG_ 3221225472 EngCldStrtFlIgniterRelayFeedback 4;
BA_ "SPN" SG_ 3221225472 EngCldStrtFlIgniterRelayFeedback 5550;
BA_ "SigType" SG_ 3221225472 EngColdStartFuelIgniterRelay 5;
BA_ "SPN" SG_ 3221225472 EngColdStartFuelIgniterRelay 5549;
BA_ "SPN" SG_ 3221225472 EngColdStartFuelIgniterCmd 5548;
BA_ "SigType" SG_ 3221225472 ParkBrakeCmd 5;
BA_ "SPN" SG_ 3221225472 ParkBrakeCmd 5630;
BA_ "SPN" SG_ 3221225472 SwtchBcklghtIllmntnBrghtnssPrcnt 5532;
BA_ "SPN" SG_ 3221225472 Aftrtrtmnt2ThrWyCtlytcCnvrtr4300 4300;
BA_ "SPN" SG_ 3221225472 Aftrtrtmnt2ThrWyCtlytcCnvrtr4299 4299;
BA_ "SPN" SG_ 3221225472 Aftrtrtmnt2ThrWyCtlytcCnvrtr4298 4298;
BA_ "SPN" SG_ 3221225472 NOxSnsrATO2SlfdgnosisFinalResult 5719;
BA_ "SigType" SG_ 3221225472 Aftrtrtmnt2OtltGsNOxSnsrCrrc5049 1;
BA_ "SPN" SG_ 3221225472 Aftrtrtmnt2OtltGsNOxSnsrCrrc5049 5049;
BA_ "SigType" SG_ 3221225472 NOxSnsrATO2OperationHoursCounter 1;
BA_ "SPN" SG_ 3221225472 NOxSnsrATO2OperationHoursCounter 5723;
BA_ "SigType" SG_ 3221225472 Aftrtrtmnt2OtltGsNOxSnsrNwPr5047 1;
BA_ "SPN" SG_ 3221225472 Aftrtrtmnt2OtltGsNOxSnsrNwPr5047 5047;
BA_ "SPN" SG_ 3221225472 NOxSnsrATI2SlfdgnosisFinalResult 5720;
BA_ "SigType" SG_ 3221225472 Aftrtrtmnt2IntkGsNOxSnsrCrrc5042 1;
BA_ "SPN" SG_ 3221225472 Aftrtrtmnt2IntkGsNOxSnsrCrrc5042 5042;
BA_ "SigType" SG_ 3221225472 NOxSnsrATI2OperationHoursCounter 1;
BA_ "SPN" SG_ 3221225472 NOxSnsrATI2OperationHoursCounter 5724;
BA_ "SigType" SG_ 3221225472 Aftrtrtmnt2IntkGsNOxSnsrNwPr5040 1;
BA_ "SPN" SG_ 3221225472 Aftrtrtmnt2IntkGsNOxSnsrNwPr5040 5040;
BA_ "SPN" SG_ 3221225472 Aftrtrtmnt1ThrWyCtlytcCnvrtr4294 4294;
BA_ "SPN" SG_ 3221225472 Aftrtrtmnt1ThrWyCtlytcCnvrtr4293 4293;
BA_ "SPN" SG_ 3221225472 Aftrtrtmnt1ThrWyCtlytcCnvrtr4292 4292;
BA_ "SigType" SG_ 3221225472 Aftrtrtmnt1DslExhstFldTankHeater 1;
BA_ "SPN" SG_ 3221225472 Aftrtrtmnt1DslExhstFldTankHeater 3363;
BA_ "SPN" SG_ 3221225472 Aftrtrtmnt1DslExhstFldTnkLvlPrlm 3532;
BA_ "SigType" SG_ 3221225472 Aftrtrtmnt1DslExhstFldTankLevel2 1;
BA_ "SPN" SG_ 3221225472 Aftrtrtmnt1DslExhstFldTankLevel2 3517;
BA_ "SigType" SG_ 3221225472 Aftrtrtmnt1DslExhstFluidTankTemp 1;
BA_ "SPN" SG_ 3221225472 Aftrtrtmnt1DslExhstFluidTankTemp 3031;
BA_ "SigType" SG_ 3221225472 Aftrtrtmnt1DslExhstFlidTankLevel 1;
BA_ "SPN" SG_ 3221225472 Aftrtrtmnt1DslExhstFlidTankLevel 1761;
BA_ "SPN" SG_ 3221225472 NOxSnsrATO1SlfdgnosisFinalResult 5717;
BA_ "SigType" SG_ 3221225472 Aftrtrtmnt1OtltGsNOxSnsrCrrc5035 1;
BA_ "SPN" SG_ 3221225472 Aftrtrtmnt1OtltGsNOxSnsrCrrc5035 5035;
BA_ "SigType" SG_ 3221225472 NOxSnsrATO1OperationHoursCounter 1;
BA_ "SPN" SG_ 3221225472 NOxSnsrATO1OperationHoursCounter 5721;
BA_ "SigType" SG_ 3221225472 Aftrtrtmnt1OtltGsNOxSnsrNwPr5033 1;
BA_ "SPN" SG_ 3221225472 Aftrtrtmnt1OtltGsNOxSnsrNwPr5033 5033;
BA_ "SPN" SG_ 3221225472 NOxSnsrATI1SlfdgnosisFinalResult 5718;
BA_ "SigType" SG_ 3221225472 Aftrtrtmnt1IntkGsNOxSnsrCrrc5028 1;
BA_ "SPN" SG_ 3221225472 Aftrtrtmnt1IntkGsNOxSnsrCrrc5028 5028;
BA_ "SigType" SG_ 3221225472 NOxSnsrATI1OperationHoursCounter 1;
BA_ "SPN" SG_ 3221225472 NOxSnsrATI1OperationHoursCounter 5722;
BA_ "SigType" SG_ 3221225472 Aftrtrtmnt1IntkGsNOxSnsrNwPr5026 1;
BA_ "SPN" SG_ 3221225472 Aftrtrtmnt1IntkGsNOxSnsrNwPr5026 5026;
BA_ "SigType" SG_ 3221225472 Armrest2Switch2 5;
BA_ "SPN" SG_ 3221225472 Armrest2Switch2 5494;
BA_ "SigType" SG_ 3221225472 Armrest2Switch1 5;
BA_ "SPN" SG_ 3221225472 Armrest2Switch1 5493;
BA_ "SigType" SG_ 3221225472 Armrest1Switch2 5;
BA_ "SPN" SG_ 3221225472 Armrest1Switch2 5492;
BA_ "SigType" SG_ 3221225472 Armrest1Switch1 5;
BA_ "SPN" SG_ 3221225472 Armrest1Switch1 1503;
BA_ "SigType" SG_ 3221225472 Aftrtrtmnt2SCRCnvrsionEfficiency 1;
BA_ "SPN" SG_ 3221225472 Aftrtrtmnt2SCRCnvrsionEfficiency 4419;
BA_ "SPN" SG_ 3221225472 Aftrtrtmnt2SCRCmmnddCtlystDslExh 4418;
BA_ "SigType" SG_ 3221225472 Aftrtrtmnt2DslExhstFldAvrgCnsmpt 1;
BA_ "SPN" SG_ 3221225472 Aftrtrtmnt2DslExhstFldAvrgCnsmpt 4417;
BA_ "SPN" SG_ 3221225472 Aftrtrtmnt2DslExhstFldTnk2HtrPrl 4439;
BA_ "SPN" SG_ 3221225472 Aftrtrtmnt2DslExhstFldTnk2Heater 4438;
BA_ "SPN" SG_ 3221225472 Aftrtrtmnt2DslExhstFldTnk2TmpPrl 4437;
BA_ "SPN" SG_ 3221225472 Aftrtrtmnt2DslExhstFldTnk2LvlPrl 4436;
BA_ "SPN" SG_ 3221225472 Aftrtrtmnt2DslExhstFldTnk2Level2 4435;
BA_ "SigType" SG_ 3221225472 Aftrtrtmnt2DslExhstFlidTank2Temp 1;
BA_ "SPN" SG_ 3221225472 Aftrtrtmnt2DslExhstFlidTank2Temp 4434;
BA_ "SigType" SG_ 3221225472 Aftrtrtmnt2DslExhstFldTank2Level 1;
BA_ "SPN" SG_ 3221225472 Aftrtrtmnt2DslExhstFldTank2Level 4433;
BA_ "SPN" SG_ 3221225472 Aftrtrtmnt2DslExhstFldTnk1HtrPrl 4432;
BA_ "SigType" SG_ 3221225472 Aftrtrtmnt2DslExhstFldTankHeater 1;
BA_ "SPN" SG_ 3221225472 Aftrtrtmnt2DslExhstFldTankHeater 4431;
BA_ "SPN" SG_ 3221225472 Aftrtrtmnt2DslExhstFldTnk1TmpPrl 4430;
BA_ "SPN" SG_ 3221225472 Aftrtrtmnt2DslExhstFldTnkLvlPrlm 4429;
BA_ "SigType" SG_ 3221225472 Aftrtrtmnt2DslExhstFldTankLevel2 1;
BA_ "SPN" SG_ 3221225472 Aftrtrtmnt2DslExhstFldTankLevel2 4428;
BA_ "SigType" SG_ 3221225472 Aftrtrtmnt2DslExhstFluidTankTemp 1;
BA_ "SPN" SG_ 3221225472 Aftrtrtmnt2DslExhstFluidTankTemp 4427;
BA_ "SigType" SG_ 3221225472 Aftrtrtmnt2DslExhstFlidTankLevel 1;
BA_ "SPN" SG_ 3221225472 Aftrtrtmnt2DslExhstFlidTankLevel 4426;
BA_ "SPN" SG_ 3221225472 Aftrtrtmnt2DslExhstFldTnkDrnVlvC 5439;
BA_ "SigType" SG_ 3221225472 Aftrtrtmnt2DslExhstFlidPumpState 5;
BA_ "SPN" SG_ 3221225472 Aftrtrtmnt2DslExhstFlidPumpState 5438;
BA_ "SPN" SG_ 3221225472 Aftrtrtmnt2DslExhstFldTnkFllVlvC 5437;
BA_ "SPN" SG_ 3221225472 Aftrtrtmnt2DslExhstFldRturnValve 4442;
BA_ "SPN" SG_ 3221225472 Aftrtrtmnt2DslExhstFldPmpDrvPrcn 4441;
BA_ "SigType" SG_ 3221225472 Aftrtrtmnt2DslExhstFldPmpMtrSped 1;
BA_ "SPN" SG_ 3221225472 Aftrtrtmnt2DslExhstFldPmpMtrSped 4440;
BA_ "SPN" SG_ 3221225472 Aftrtrtmnt2DeselExhaustFluidType 4425;
BA_ "SigType" SG_ 3221225472 Aftrtrtmnt2DslExhstFldCndctivity 1;
BA_ "SPN" SG_ 3221225472 Aftrtrtmnt2DslExhstFldCndctivity 4422;
BA_ "SigType" SG_ 3221225472 Aftrtrtmnt2DslExhstFldCncntrtion 1;
BA_ "SPN" SG_ 3221225472 Aftrtrtmnt2DslExhstFldCncntrtion 4421;
BA_ "SigType" SG_ 3221225472 Aftrtrtmnt2DselExhaustFluidTemp2 1;
BA_ "SPN" SG_ 3221225472 Aftrtrtmnt2DselExhaustFluidTemp2 4420;
BA_ "SPN" SG_ 3221225472 Aftrtrtmnt2SCRExhstGsDffPrssPrlm 4412;
BA_ "SigType" SG_ 3221225472 Aftrtrtmnt2SCRExhustGasDiffPress 1;
BA_ "SPN" SG_ 3221225472 Aftrtrtmnt2SCRExhustGasDiffPress 4411;
BA_ "SPN" SG_ 3221225472 Aftrtrtmnt2DslExhstFldTnk2HtrCmd 5415;
BA_ "SPN" SG_ 3221225472 Aftrtrtmnt2DslExhstFldTnkHterCmd 5138;
BA_ "SigType" SG_ 3221225472 Aftrtrtmnt2DslExhstFldLneHeater4 5;
BA_ "SPN" SG_ 3221225472 Aftrtrtmnt2DslExhstFldLneHeater4 4410;
BA_ "SigType" SG_ 3221225472 Aftrtrtmnt2DslExhstFldLneHeater3 5;
BA_ "SPN" SG_ 3221225472 Aftrtrtmnt2DslExhstFldLneHeater3 4409;
BA_ "SigType" SG_ 3221225472 Aftrtrtmnt2DslExhstFldLneHeater2 5;
BA_ "SPN" SG_ 3221225472 Aftrtrtmnt2DslExhstFldLneHeater2 4408;
BA_ "SigType" SG_ 3221225472 Aftrtrtmnt2DslExhstFldLneHeater1 5;
BA_ "SPN" SG_ 3221225472 Aftrtrtmnt2DslExhstFldLneHeater1 4407;
BA_ "SPN" SG_ 3221225472 Aftrtrtmnt2DslExhstFldDsrHtngMdR 4406;
BA_ "SigType" SG_ 3221225472 Aftrtrtmnt2DslExhstFldDsrFltSppr 5;
BA_ "SPN" SG_ 3221225472 Aftrtrtmnt2DslExhstFldDsrFltSppr 4405;
BA_ "SigType" SG_ 3221225472 Aftrtrtmnt2DslExhstFldRqstdQntty 1;
BA_ "SPN" SG_ 3221225472 Aftrtrtmnt2DslExhstFldRqstdQntty 4403;
BA_ "SigType" SG_ 3221225472 Aftrtrtmnt2DslExhstFldDsngRqstdQ 1;
BA_ "SPN" SG_ 3221225472 Aftrtrtmnt2DslExhstFldDsngRqstdQ 4401;
BA_ "SPN" SG_ 3221225472 Aftrtrtmnt2DslExhstFldLnHtr4Prlm 4400;
BA_ "SigType" SG_ 3221225472 Aftrtrtmnt2DslExhstFldLnHtr4Stte 5;
BA_ "SPN" SG_ 3221225472 Aftrtrtmnt2DslExhstFldLnHtr4Stte 4399;
BA_ "SPN" SG_ 3221225472 Aftrtrtmnt2DslExhstFldLnHtr3Prlm 4398;
BA_ "SigType" SG_ 3221225472 Aftrtrtmnt2DslExhstFldLnHtr3Stte 5;
BA_ "SPN" SG_ 3221225472 Aftrtrtmnt2DslExhstFldLnHtr3Stte 4397;
BA_ "SPN" SG_ 3221225472 Aftrtrtmnt2DslExhstFldLnHtr2Prlm 4396;
BA_ "SigType" SG_ 3221225472 Aftrtrtmnt2DslExhstFldLnHtr2Stte 5;
BA_ "SPN" SG_ 3221225472 Aftrtrtmnt2DslExhstFldLnHtr2Stte 4395;
BA_ "SPN" SG_ 3221225472 Aftrtrtmnt2DslExhstFldLnHtr1Prlm 4394;
BA_ "SigType" SG_ 3221225472 Aftrtrtmnt2DslExhstFldLnHtr1Stte 5;
BA_ "SPN" SG_ 3221225472 Aftrtrtmnt2DslExhstFldLnHtr1Stte 4393;
BA_ "SigType" SG_ 3221225472 Aftrtrtmnt2DslExhstFldDosingTemp 1;
BA_ "SPN" SG_ 3221225472 Aftrtrtmnt2DslExhstFldDosingTemp 4390;
BA_ "SigType" SG_ 3221225472 Aftrtrtmnt2DslExhstFldDsngAbsPrs 1;
BA_ "SPN" SG_ 3221225472 Aftrtrtmnt2DslExhstFldDsngAbsPrs 4387;
BA_ "SigType" SG_ 3221225472 Aftrtrtmnt2DslExhstFldActlQnttyO 1;
BA_ "SPN" SG_ 3221225472 Aftrtrtmnt2DslExhstFldActlQnttyO 4386;
BA_ "SigType" SG_ 3221225472 Aftrtrtmnt2DslExhstFldActlDsngQn 1;
BA_ "SPN" SG_ 3221225472 Aftrtrtmnt2DslExhstFldActlDsngQn 4384;
BA_ "SPN" SG_ 3221225472 Aftrtrtmnt2GsOxdtnCtlystOtlt4763 4763;
BA_ "SPN" SG_ 3221225472 Aftrtrtmnt2GsOxdtnCtlystIntk4762 4762;
BA_ "SPN" SG_ 3221225472 Aftrtrtmnt2DslOxdtnCtlystDff4776 4776;
BA_ "SPN" SG_ 3221225472 Aftrtrtmnt2DslOxdtnCtlystOtl4775 4775;
BA_ "SPN" SG_ 3221225472 Aftrtrtmnt2DslOxdtnCtlystInt4774 4774;
BA_ "SPN" SG_ 3221225472 Aftrtrtmnt1DslExhstFldTnk2HtrPrl 4373;
BA_ "SigType" SG_ 3221225472 Aftrtrtmnt1DslExhstFldTnk2Heater 1;
BA_ "SPN" SG_ 3221225472 Aftrtrtmnt1DslExhstFldTnk2Heater 4372;
BA_ "SPN" SG_ 3221225472 Aftrtrtmnt1DslExhstFldTnk2TmpPrl 4371;
BA_ "SPN" SG_ 3221225472 Aftrtrtmnt1DslExhstFldTnk2LvlPrl 4370;
BA_ "SPN" SG_ 3221225472 Aftrtrtmnt1DslExhstFldTnk2Level2 4369;
BA_ "SigType" SG_ 3221225472 Aftrtrtmnt1DslExhstFlidTank2Temp 1;
BA_ "SPN" SG_ 3221225472 Aftrtrtmnt1DslExhstFlidTank2Temp 4368;
BA_ "SigType" SG_ 3221225472 Aftrtrtmnt1DslExhstFldTank2Level 1;
BA_ "SPN" SG_ 3221225472 Aftrtrtmnt1DslExhstFldTank2Level 4367;
BA_ "SPN" SG_ 3221225472 Aftrtrtmnt1DslExhstFldTnkDrnVlvC 5436;
BA_ "SigType" SG_ 3221225472 Aftrtrtmnt1DslExhstFlidPumpState 5;
BA_ "SPN" SG_ 3221225472 Aftrtrtmnt1DslExhstFlidPumpState 5435;
BA_ "SPN" SG_ 3221225472 Aftrtrtmnt1DslExhstFldTnkFllVlvC 5434;
BA_ "SPN" SG_ 3221225472 Aftrtrtmnt1DslExhstFldRturnValve 4376;
BA_ "SPN" SG_ 3221225472 Aftrtrtmnt1DslExhstFldPmpDrvPrcn 4375;
BA_ "SigType" SG_ 3221225472 Aftrtrtmnt1DslExhstFldPmpMtrSped 1;
BA_ "SPN" SG_ 3221225472 Aftrtrtmnt1DslExhstFldPmpMtrSped 4374;
BA_ "SPN" SG_ 3221225472 Aftrtrtmnt1SCRExhstGsDffPrssPrlm 4359;
BA_ "SigType" SG_ 3221225472 Aftrtrtmnt1SCRExhustGasDiffPress 1;
BA_ "SPN" SG_ 3221225472 Aftrtrtmnt1SCRExhustGasDiffPress 4358;
BA_ "SPN" SG_ 3221225472 Aftrtrtmnt1DslExhstFldPmpHterCmd 5707;
BA_ "SPN" SG_ 3221225472 Aftrtrtmnt1DslExhstFldTnk2HtrCmd 5414;
BA_ "SPN" SG_ 3221225472 Aftrtrtmnt1DslExhstFldTnkHterCmd 5137;
BA_ "SigType" SG_ 3221225472 Aftrtrtmnt1DslExhstFldLneHeater4 5;
BA_ "SPN" SG_ 3221225472 Aftrtrtmnt1DslExhstFldLneHeater4 4357;
BA_ "SigType" SG_ 3221225472 Aftrtrtmnt1DslExhstFldLneHeater3 5;
BA_ "SPN" SG_ 3221225472 Aftrtrtmnt1DslExhstFldLneHeater3 4356;
BA_ "SigType" SG_ 3221225472 Aftrtrtmnt1DslExhstFldLneHeater2 5;
BA_ "SPN" SG_ 3221225472 Aftrtrtmnt1DslExhstFldLneHeater2 4355;
BA_ "SigType" SG_ 3221225472 Aftrtrtmnt1DslExhstFldLneHeater1 5;
BA_ "SPN" SG_ 3221225472 Aftrtrtmnt1DslExhstFldLneHeater1 4354;
BA_ "SPN" SG_ 3221225472 Aftrtrtmnt1DslExhstFldDsrHtngMdR 4353;
BA_ "SigType" SG_ 3221225472 Aftrtrtmnt1DslExhstFldDsrFltSppr 5;
BA_ "SPN" SG_ 3221225472 Aftrtrtmnt1DslExhstFldDsrFltSppr 4352;
BA_ "SigType" SG_ 3221225472 Aftrtrtmnt1DslExhstFldRqstdQntty 1;
BA_ "SPN" SG_ 3221225472 Aftrtrtmnt1DslExhstFldRqstdQntty 4350;
BA_ "SigType" SG_ 3221225472 Aftrtrtmnt1DslExhstFldDsngRqstdQ 1;
BA_ "SPN" SG_ 3221225472 Aftrtrtmnt1DslExhstFldDsngRqstdQ 4348;
BA_ "SPN" SG_ 3221225472 Aftrtrtmnt1DslExhstFldLnHtr4Prlm 4347;
BA_ "SigType" SG_ 3221225472 Aftrtrtmnt1DslExhstFldLnHtr4Stte 5;
BA_ "SPN" SG_ 3221225472 Aftrtrtmnt1DslExhstFldLnHtr4Stte 4346;
BA_ "SPN" SG_ 3221225472 Aftrtrtmnt1DslExhstFldLnHtr3Prlm 4345;
BA_ "SigType" SG_ 3221225472 Aftrtrtmnt1DslExhstFldLnHtr3Stte 5;
BA_ "SPN" SG_ 3221225472 Aftrtrtmnt1DslExhstFldLnHtr3Stte 4344;
BA_ "SPN" SG_ 3221225472 Aftrtrtmnt1DslExhstFldLnHtr2Prlm 4343;
BA_ "SigType" SG_ 3221225472 Aftrtrtmnt1DslExhstFldLnHtr2Stte 5;
BA_ "SPN" SG_ 3221225472 Aftrtrtmnt1DslExhstFldLnHtr2Stte 4342;
BA_ "SPN" SG_ 3221225472 Aftrtrtmnt1DslExhstFldLnHtr1Prlm 4341;
BA_ "SigType" SG_ 3221225472 Aftrtrtmnt1DslExhstFldLnHtr1Stte 5;
BA_ "SPN" SG_ 3221225472 Aftrtrtmnt1DslExhstFldLnHtr1Stte 4340;
BA_ "SigType" SG_ 3221225472 Aftrtrtmnt1DslExhstFldDosingTemp 1;
BA_ "SPN" SG_ 3221225472 Aftrtrtmnt1DslExhstFldDosingTemp 4337;
BA_ "SigType" SG_ 3221225472 Aftrtrtmnt1DslExhstFldDsrAbsPrss 1;
BA_ "SPN" SG_ 3221225472 Aftrtrtmnt1DslExhstFldDsrAbsPrss 4334;
BA_ "SigType" SG_ 3221225472 Aftrtrtmnt1DslExhstFldActlQnttyO 1;
BA_ "SPN" SG_ 3221225472 Aftrtrtmnt1DslExhstFldActlQnttyO 4333;
BA_ "SigType" SG_ 3221225472 Aftrtrtmnt1DslExhstFldActlDsngQn 1;
BA_ "SPN" SG_ 3221225472 Aftrtrtmnt1DslExhstFldActlDsngQn 4331;
BA_ "SPN" SG_ 3221225472 Aftrtrtmnt1GsOxdtnCtlystOtlt4757 4757;
BA_ "SPN" SG_ 3221225472 Aftrtrtmnt1GsOxdtnCtlystIntk4756 4756;
BA_ "SPN" SG_ 3221225472 Aftrtrtmnt1DslOxdtnCtlystDff4770 4770;
BA_ "SPN" SG_ 3221225472 Aftrtrtmnt1DslOxdtnCtlystOtl4769 4769;
BA_ "SPN" SG_ 3221225472 Aftrtrtmnt1DslOxdtnCtlystInt4768 4768;
BA_ "SPN" SG_ 3221225472 EngAxClerSupplyValve2ActuatorCmd 5547;
BA_ "SPN" SG_ 3221225472 EngAxClerSupplyValve1ActuatorCmd 5546;
BA_ "SPN" SG_ 3221225472 Aftrtrtmnt1AvrgDstncBtwnActvDPFR 5827;
BA_ "SPN" SG_ 3221225472 NOxSensorATO1SelfdiagnosisStatus 5713;
BA_ "SPN" SG_ 3221225472 Aftrtrtmnt1DslPrtcltFltrIntk3244 3244;
BA_ "SPN" SG_ 3221225472 Aftrtrtmnt1DslPrtcltFltrIntr3254 3254;
BA_ "SPN" SG_ 3221225472 NOxSensorATI1SelfdiagnosisStatus 5714;
BA_ "SPN" SG_ 3221225472 Aftrtrtmnt2AvrgDstncBtwnActvDPFR 5828;
BA_ "SPN" SG_ 3221225472 NOxSensorATO2SelfdiagnosisStatus 5715;
BA_ "SPN" SG_ 3221225472 Aftrtrtmnt2DslPrtcltFltrIntk3278 3278;
BA_ "SPN" SG_ 3221225472 Aftrtrtmnt2DslPrtcltFltrIntr3288 3288;
BA_ "SPN" SG_ 3221225472 NOxSensorATI2SelfdiagnosisStatus 5716;
BA_ "SigType" SG_ 3221225472 BarometricAbsPress 1;
BA_ "SPN" SG_ 3221225472 BarometricAbsPress 5685;
BA_ "SPN" SG_ 3221225472 CalculatedAmbientAirTemp 5581;
BA_ "SigType" SG_ 3221225472 MinutesAccumulatedMILActivated 1;
BA_ "SPN" SG_ 3221225472 MinutesAccumulatedMILActivated 3295;
BA_ "SigType" SG_ 3221225472 ProprietaryNetwork2 4;
BA_ "SPN" SG_ 3221225472 ProprietaryNetwork2 5588;
BA_ "SigType" SG_ 3221225472 ProprietaryNetwork1 4;
BA_ "SPN" SG_ 3221225472 ProprietaryNetwork1 625;
BA_ "SigType" SG_ 3221225472 AETCTorqueValue14 1;
BA_ "SigType" SG_ 3221225472 AETCTorqueValue13 1;
BA_ "SigType" SG_ 3221225472 AETCTorqueValue12 1;
BA_ "SigType" SG_ 3221225472 AETCTorqueValue11 1;
BA_ "SigType" SG_ 3221225472 AETCTorqueValue10 1;
BA_ "SigType" SG_ 3221225472 AETCTorqueValue09 1;
BA_ "SigType" SG_ 3221225472 AETCTorqueValue08 1;
BA_ "SigType" SG_ 3221225472 AETCTorqueValue07 1;
BA_ "SigType" SG_ 3221225472 AETCTorqueValue06 1;
BA_ "SigType" SG_ 3221225472 AETCTorqueValue05 1;
BA_ "SigType" SG_ 3221225472 AETCTorqueValue04 1;
BA_ "SigType" SG_ 3221225472 AETCTorqueValue03 1;
BA_ "SigType" SG_ 3221225472 AETCTorqueValue02 1;
BA_ "SigType" SG_ 3221225472 AETCTorqueValue01 1;
BA_ "SigType" SG_ 3221225472 AETCSpeedValue14 1;
BA_ "SigType" SG_ 3221225472 AETCSpeedValue13 1;
BA_ "SigType" SG_ 3221225472 AETCSpeedValue12 1;
BA_ "SigType" SG_ 3221225472 AETCSpeedValue11 1;
BA_ "SigType" SG_ 3221225472 AETCSpeedValue10 1;
BA_ "SigType" SG_ 3221225472 AETCSpeedValue09 1;
BA_ "SigType" SG_ 3221225472 AETCSpeedValue08 1;
BA_ "SigType" SG_ 3221225472 AETCSpeedValue07 1;
BA_ "SigType" SG_ 3221225472 AETCSpeedValue06 1;
BA_ "SigType" SG_ 3221225472 AETCSpeedValue05 1;
BA_ "SigType" SG_ 3221225472 AETCSpeedValue04 1;
BA_ "SigType" SG_ 3221225472 AETCSpeedValue03 1;
BA_ "SigType" SG_ 3221225472 AETCSpeedValue02 1;
BA_ "SigType" SG_ 3221225472 AETCSpeedValue01 1;
BA_ "SigType" SG_ 3221225472 AETCTorqueValue00 1;
BA_ "SigType" SG_ 3221225472 AETCSpeedValue00 1;
BA_ "SPN" SG_ 3221225472 TransOilLevel1MeasurementStatus 3026;
BA_ "SPN" SG_ 3221225472 TransOilLevel1CountdownTimer 3028;
BA_ "SigType" SG_ 3221225472 TransOilLevel1High_Low 1;
BA_ "SPN" SG_ 3221225472 TransOilLevel1High_Low 3027;
BA_ "SigType" SG_ 3221225472 TransOilTemp1 1;
BA_ "SPN" SG_ 3221225472 TransOilTemp1 177;
BA_ "SigType" SG_ 3221225472 TransOilLevel1 1;
BA_ "SPN" SG_ 3221225472 TransOilLevel1 124;
BA_ "SigType" SG_ 3221225472 TrailerWeight 1;
BA_ "SPN" SG_ 3221225472 TrailerWeight 180;
BA_ "SAEDocument" SG_ 3221225472 TrailerWeight "J1939-71";
BA_ "SPN" SG_ 3221225472 ReferenceTirePressSetting 3193;
BA_ "SAEDocument" SG_ 3221225472 ReferenceTirePressSetting "J1939-71";
BA_ "SPN" SG_ 3221225472 ReferenceTirePress 3191;
BA_ "SAEDocument" SG_ 3221225472 ReferenceTirePress "J1939-71";
BA_ "SPN" SG_ 3221225472 TirePressThresholdDetection 2587;
BA_ "SAEDocument" SG_ 3221225472 TirePressThresholdDetection "J1939-71";
BA_ "SigType" SG_ 3221225472 TireAirLeakageRate 1;
BA_ "SPN" SG_ 3221225472 TireAirLeakageRate 2586;
BA_ "SAEDocument" SG_ 3221225472 TireAirLeakageRate "J1939-71";
BA_ "SigType" SG_ 3221225472 CTIWheelEndElectricalFault 4;
BA_ "SPN" SG_ 3221225472 CTIWheelEndElectricalFault 1697;
BA_ "SAEDocument" SG_ 3221225472 CTIWheelEndElectricalFault "J1939-71";
BA_ "SigType" SG_ 3221225472 CTITireStatus 4;
BA_ "SPN" SG_ 3221225472 CTITireStatus 1698;
BA_ "SAEDocument" SG_ 3221225472 CTITireStatus "J1939-71";
BA_ "SigType" SG_ 3221225472 CTIWheelSensorStatus 4;
BA_ "SPN" SG_ 3221225472 CTIWheelSensorStatus 1699;
BA_ "SAEDocument" SG_ 3221225472 CTIWheelSensorStatus "J1939-71";
BA_ "SigType" SG_ 3221225472 TireTemp 1;
BA_ "SPN" SG_ 3221225472 TireTemp 242;
BA_ "SAEDocument" SG_ 3221225472 TireTemp "J1939-71";
BA_ "SigType" SG_ 3221225472 TirePress 1;
BA_ "SPN" SG_ 3221225472 TirePress 241;
BA_ "SAEDocument" SG_ 3221225472 TirePress "J1939-71";
BA_ "SigType" SG_ 3221225472 EngTurningGearEngaged 4;
BA_ "SPN" SG_ 3221225472 EngTurningGearEngaged 1206;
BA_ "SAEDocument" SG_ 3221225472 EngTurningGearEngaged "J1939-71";
BA_ "SPN" SG_ 3221225472 IdentityNumber 2837;
BA_ "SAEDocument" SG_ 3221225472 IdentityNumber "J1939-81";
BA_ "SigType" SG_ 3221225472 ManufacturerCode 1;
BA_ "SPN" SG_ 3221225472 ManufacturerCode 2838;
BA_ "SAEDocument" SG_ 3221225472 ManufacturerCode "NMEA2000";
BA_ "SPN" SG_ 3221225472 ECUInstance 2840;
BA_ "SAEDocument" SG_ 3221225472 ECUInstance "J1939-81";
BA_ "SPN" SG_ 3221225472 FunctionInstance 2839;
BA_ "SAEDocument" SG_ 3221225472 FunctionInstance "J1939-81";
BA_ "SPN" SG_ 3221225472 Function 2841;
BA_ "SAEDocument" SG_ 3221225472 Function "J1939-81";
BA_ "SAEDocument" SG_ 3221225472 VehicleSystem2 "J1939-81";
BA_ "SPN" SG_ 3221225472 VehicleSystemInstance 2843;
BA_ "SAEDocument" SG_ 3221225472 VehicleSystemInstance "J1939-81";
BA_ "SPN" SG_ 3221225472 IndustryGroup 2846;
BA_ "SAEDocument" SG_ 3221225472 IndustryGroup "NMEA2000";
BA_ "SPN" SG_ 3221225472 ArbitraryAddressCapable 2844;
BA_ "SAEDocument" SG_ 3221225472 ArbitraryAddressCapable "J1939-81";
BA_ "SystemSignalLongSymbol" SG_ 3221225472 ChangeChildPositionParentObjectI "ChangeChildPositionParentObjectID";
BA_ "SystemSignalLongSymbol" SG_ 3221225472 ChangeChildLocationParentObjectI "ChangeChildLocationParentObjectID";
BA_ "SystemSignalLongSymbol" SG_ 3221225472 ChangeChildPositionParentOb_0000 "ChangeChildPositionParentObjectID";
BA_ "SystemSignalLongSymbol" SG_ 3221225472 ChangeChildLocationParentOb_0000 "ChangeChildLocationParentObjectID";
BA_ "SigType" SG_ 3221225472 VersionLabelToStore 3;
BA_ "SigType" SG_ 3221225472 VersionLabelToLoad 3;
BA_ "SigType" SG_ 3221225472 VersionLabelToDelete 3;
BA_ "SigType" SG_ 3221225472 ExtendedVersionLabelToStore 3;
BA_ "SigType" SG_ 3221225472 ExtendedVersionLabelToLoad 3;
BA_ "SigType" SG_ 3221225472 ExtendedVersionLabelToDelete 3;
BA_ "SigType" SG_ 3221225472 NewStringValue 9;
BA_ "SPN" SG_ 3221225472 MessageChecksum 4207;
BA_ "SAEDocument" SG_ 3221225472 MessageChecksum "J1939-71";
BA_ "SPN" SG_ 3221225472 MessageCounter 4206;
BA_ "SAEDocument" SG_ 3221225472 MessageCounter "J1939-71";
BA_ "SPN" SG_ 3221225472 EngRequestedTorqueHighResolution 4191;
BA_ "SAEDocument" SG_ 3221225472 EngRequestedTorqueHighResolution "J1939-71";
BA_ "SPN" SG_ 3221225472 TSC1CtrlPurpose 3350;
BA_ "SAEDocument" SG_ 3221225472 TSC1CtrlPurpose "J1939-71";
BA_ "SPN" SG_ 3221225472 TSC1TransRate 3349;
BA_ "SAEDocument" SG_ 3221225472 TSC1TransRate "J1939-71";
BA_ "SPN" SG_ 3221225472 EngRequestedTorque_TorqueLimit 518;
BA_ "SAEDocument" SG_ 3221225472 EngRequestedTorque_TorqueLimit "J1939-71";
BA_ "SPN" SG_ 3221225472 EngRequestedSpeed_SpeedLimit 898;
BA_ "SAEDocument" SG_ 3221225472 EngRequestedSpeed_SpeedLimit "J1939-71";
BA_ "SigType" SG_ 3221225472 OverrideCtrlModePriority 5;
BA_ "SPN" SG_ 3221225472 OverrideCtrlModePriority 897;
BA_ "SAEDocument" SG_ 3221225472 OverrideCtrlModePriority "J1939-71";
BA_ "SigType" SG_ 3221225472 EngRequestedSpeedCtrlConditions 5;
BA_ "SPN" SG_ 3221225472 EngRequestedSpeedCtrlConditions 696;
BA_ "SAEDocument" SG_ 3221225472 EngRequestedSpeedCtrlConditions "J1939-71";
BA_ "SigType" SG_ 3221225472 EngOverrideCtrlMode 5;
BA_ "SPN" SG_ 3221225472 EngOverrideCtrlMode 695;
BA_ "SAEDocument" SG_ 3221225472 EngOverrideCtrlMode "J1939-71";
BA_ "SigType" SG_ 2566838782 AuxI_OChannel2 1;
BA_ "SPN" SG_ 2566838782 AuxI_OChannel2 1084;
BA_ "SAEDocument" SG_ 2566838782 AuxI_OChannel2 "J1939-71";
BA_ "SigType" SG_ 2566838782 AuxI_OChannel1 1;
BA_ "SPN" SG_ 2566838782 AuxI_OChannel1 1083;
BA_ "SAEDocument" SG_ 2566838782 AuxI_OChannel1 "J1939-71";
BA_ "SPN" SG_ 2566838782 AuxI_O13 713;
BA_ "SAEDocument" SG_ 2566838782 AuxI_O13 "J1939-71";
BA_ "SPN" SG_ 2566838782 AuxI_O14 714;
BA_ "SAEDocument" SG_ 2566838782 AuxI_O14 "J1939-71";
BA_ "SPN" SG_ 2566838782 AuxI_O15 715;
BA_ "SAEDocument" SG_ 2566838782 AuxI_O15 "J1939-71";
BA_ "SPN" SG_ 2566838782 AuxI_O16 716;
BA_ "SAEDocument" SG_ 2566838782 AuxI_O16 "J1939-71";
BA_ "SPN" SG_ 2566838782 AuxI_O09 709;
BA_ "SAEDocument" SG_ 2566838782 AuxI_O09 "J1939-71";
BA_ "SPN" SG_ 2566838782 AuxI_O10 710;
BA_ "SAEDocument" SG_ 2566838782 AuxI_O10 "J1939-71";
BA_ "SPN" SG_ 2566838782 AuxI_O11 711;
BA_ "SAEDocument" SG_ 2566838782 AuxI_O11 "J1939-71";
BA_ "SPN" SG_ 2566838782 AuxI_O12 712;
BA_ "SAEDocument" SG_ 2566838782 AuxI_O12 "J1939-71";
BA_ "SPN" SG_ 2566838782 AuxI_O05 705;
BA_ "SAEDocument" SG_ 2566838782 AuxI_O05 "J1939-71";
BA_ "SPN" SG_ 2566838782 AuxI_O06 706;
BA_ "SAEDocument" SG_ 2566838782 AuxI_O06 "J1939-71";
BA_ "SPN" SG_ 2566838782 AuxI_O07 707;
BA_ "SAEDocument" SG_ 2566838782 AuxI_O07 "J1939-71";
BA_ "SPN" SG_ 2566838782 AuxI_O08 708;
BA_ "SAEDocument" SG_ 2566838782 AuxI_O08 "J1939-71";
BA_ "SPN" SG_ 2566838782 AuxI_O01 701;
BA_ "SAEDocument" SG_ 2566838782 AuxI_O01 "J1939-71";
BA_ "SPN" SG_ 2566838782 AuxI_O02 702;
BA_ "SAEDocument" SG_ 2566838782 AuxI_O02 "J1939-71";
BA_ "SPN" SG_ 2566838782 AuxI_O03 703;
BA_ "SAEDocument" SG_ 2566838782 AuxI_O03 "J1939-71";
BA_ "SPN" SG_ 2566838782 AuxI_O04 704;
BA_ "SAEDocument" SG_ 2566838782 AuxI_O04 "J1939-71";
BA_ "SigType" SG_ 2559115006 WirelessSignalStrength2 1;
BA_ "SPN" SG_ 2559115006 WirelessSignalStrength2 5757;
BA_ "SPN" SG_ 2559115006 TransmitterID2 5756;
BA_ "SigType" SG_ 2559115006 RadioBeaconDirection 5;
BA_ "SPN" SG_ 2559115006 RadioBeaconDirection 5755;
BA_ "SPN" SG_ 2559115006 UnqBeaconMessageIdentifierNumber 5754;
BA_ "SPN" SG_ 2566707454 Aftrtrtmnt1DslPrtcltFltr2StS5647 5647;
BA_ "SPN" SG_ 2566707454 Aftrtrtmnt1DslPrtcltFltr2StS5646 5646;
BA_ "SPN" SG_ 2566707454 Aftrtrtmnt1DslPrtcltFltr2StS5645 5645;
BA_ "SPN" SG_ 2566707454 Aftrtrtmnt1DslPrtcltFltr2StSnsrA 5652;
BA_ "SPN" SG_ 2566707198 Aftrtrtmnt1DslPrtcltFltr2StS5651 5651;
BA_ "SPN" SG_ 2566707198 Aftrtrtmnt1DslPrtcltFltr2StS5650 5650;
BA_ "SPN" SG_ 2566707198 Aftrtrtmnt1DslPrtcltFltr2StSnsrF 5653;
BA_ "SPN" SG_ 2566707198 Aftrtrtmnt1DslPrtcltFltr2StSnsrA 5652;
BA_ "SPN" SG_ 2566706942 Aftrtrtmnt1DslPrtcltFltr2StS5655 5655;
BA_ "SPN" SG_ 2566706942 Aftrtrtmnt1DslPrtcltFltr2StS5654 5654;
BA_ "SPN" SG_ 2566706942 Aftrtrtmnt1DslPrtcltFltr2StSnsrF 5653;
BA_ "SPN" SG_ 2566706942 Aftrtrtmnt1DslPrtcltFltr2StSnsrA 5652;
BA_ "SigType" SG_ 2559770366 HydrocarbonDoserPurgingNeeded 5;
BA_ "SPN" SG_ 2559770366 HydrocarbonDoserPurgingNeeded 5509;
BA_ "SPN" SG_ 2559770366 DiagnosticStatusOfHCDoser 5508;
BA_ "SigType" SG_ 2559770366 HCDoserInjectingStatus 5;
BA_ "SPN" SG_ 2559770366 HCDoserInjectingStatus 5507;
BA_ "SPN" SG_ 2559770366 HCDoserStatus 5506;
BA_ "SigType" SG_ 2559770366 RequestedFuelMassRate 1;
BA_ "SPN" SG_ 2559770366 RequestedFuelMassRate 5505;
BA_ "SigType" SG_ 2559704830 LubricationTimingCycleCmd 5;
BA_ "SPN" SG_ 2559704830 LubricationTimingCycleCmd 5514;
BA_ "SigType" SG_ 2559704830 LubricationPumpEnableCmd 5;
BA_ "SPN" SG_ 2559704830 LubricationPumpEnableCmd 5513;
BA_ "SPN" SG_ 2559704830 LubricationOperationModeSetCmd 5512;
BA_ "SPN" SG_ 2559704830 LubricationCycleSetCmd 5511;
BA_ "SigType" SG_ 2559704830 LubricationCycleModeLockCmd 5;
BA_ "SPN" SG_ 2559704830 LubricationCycleModeLockCmd 5510;
BA_ "SigType" SG_ 2559639294 SupplementalFanPowerHold 5;
BA_ "SPN" SG_ 2559639294 SupplementalFanPowerHold 5555;
BA_ "SPN" SG_ 2559639294 SupplementalFanSpeedCmd 5554;
BA_ "SigType" SG_ 2559639294 SupplementalFanDirectionCmd 5;
BA_ "SPN" SG_ 2559639294 SupplementalFanDirectionCmd 5553;
BA_ "SigType" SG_ 2559639294 SupplementalFanEnableCmd 5;
BA_ "SPN" SG_ 2559639294 SupplementalFanEnableCmd 5552;
BA_ "SigType" SG_ 2559573758 ClntLvlEngPrtctnShtdwnOvrrideCmd 5;
BA_ "SPN" SG_ 2559573758 ClntLvlEngPrtctnShtdwnOvrrideCmd 5565;
BA_ "SigType" SG_ 2349530878 CruiseCtrlPauseCmd 5;
BA_ "SPN" SG_ 2349530878 CruiseCtrlPauseCmd 5605;
BA_ "SigType" SG_ 2349530878 CruiseCtrlResumeCmd 5;
BA_ "SPN" SG_ 2349530878 CruiseCtrlResumeCmd 5604;
BA_ "SigType" SG_ 2349530878 CruiseCtrlDisableCmd 5;
BA_ "SPN" SG_ 2349530878 CruiseCtrlDisableCmd 5603;
BA_ "SPN" SG_ 2365428734 GenFrequencySelection 4080;
BA_ "SigType" SG_ 2365428734 GenGoverningSpeedCommand 5;
BA_ "SPN" SG_ 2365428734 GenGoverningSpeedCommand 4079;
BA_ "SigType" SG_ 2365428734 GenAlternatorEfficiency 1;
BA_ "SPN" SG_ 2365428734 GenAlternatorEfficiency 4078;
BA_ "SigType" SG_ 2365428734 GenNotReadyToAutoParaState 4;
BA_ "SPN" SG_ 2365428734 GenNotReadyToAutoParaState 3568;
BA_ "SigType" SG_ 2365428734 GenCtrlNotInAutoStartState 4;
BA_ "SPN" SG_ 2365428734 GenCtrlNotInAutoStartState 3567;
BA_ "SigType" SG_ 2365428734 RequestedEngineControlMode 4;
BA_ "SPN" SG_ 2365428734 RequestedEngineControlMode 3542;
BA_ "SigType" SG_ 2566702846 EngOBDWarmUpSequence 5;
BA_ "SPN" SG_ 2566702846 EngOBDWarmUpSequence 5843;
BA_ "SigType" SG_ 2566703102 CertificationEngineFamilyName 8;
BA_ "SPN" SG_ 2566703102 CertificationEngineFamilyName 5845;
BA_ "SigType" SG_ 2566703102 ModelYear 3;
BA_ "SPN" SG_ 2566703102 ModelYear 5844;
BA_ "SigType" SG_ 2566705918 DTC1 7;
BA_ "SAEDocument" SG_ 2566705918 DTC1 "J1939-73";
BA_ "SigType" SG_ 2566705918 FlashProtectLamp 4;
BA_ "SPN" SG_ 2566705918 FlashProtectLamp 3041;
BA_ "SAEDocument" SG_ 2566705918 FlashProtectLamp "J1939-73";
BA_ "SigType" SG_ 2566705918 FlashAmberWarningLamp 4;
BA_ "SPN" SG_ 2566705918 FlashAmberWarningLamp 3040;
BA_ "SAEDocument" SG_ 2566705918 FlashAmberWarningLamp "J1939-73";
BA_ "SigType" SG_ 2566705918 FlashRedStopLamp 4;
BA_ "SPN" SG_ 2566705918 FlashRedStopLamp 3039;
BA_ "SAEDocument" SG_ 2566705918 FlashRedStopLamp "J1939-73";
BA_ "SigType" SG_ 2566705918 FlashMalfuncIndicatorLamp 4;
BA_ "SPN" SG_ 2566705918 FlashMalfuncIndicatorLamp 3038;
BA_ "SAEDocument" SG_ 2566705918 FlashMalfuncIndicatorLamp "J1939-73";
BA_ "SigType" SG_ 2566705918 ProtectLampStatus 4;
BA_ "SPN" SG_ 2566705918 ProtectLampStatus 987;
BA_ "SAEDocument" SG_ 2566705918 ProtectLampStatus "J1939-73";
BA_ "SigType" SG_ 2566705918 AmberWarningLampStatus 4;
BA_ "SPN" SG_ 2566705918 AmberWarningLampStatus 624;
BA_ "SAEDocument" SG_ 2566705918 AmberWarningLampStatus "J1939-73";
BA_ "SigType" SG_ 2566705918 RedStopLampState 4;
BA_ "SPN" SG_ 2566705918 RedStopLampState 623;
BA_ "SAEDocument" SG_ 2566705918 RedStopLampState "J1939-73";
BA_ "SigType" SG_ 2566705918 MalfunctionIndicatorLampStatus 4;
BA_ "SPN" SG_ 2566705918 MalfunctionIndicatorLampStatus 1213;
BA_ "SAEDocument" SG_ 2566705918 MalfunctionIndicatorLampStatus "J1939-73";
BA_ "SigType" SG_ 2566705662 DTC1 7;
BA_ "SAEDocument" SG_ 2566705662 DTC1 "J1939-73";
BA_ "SigType" SG_ 2566705662 FlashProtectLamp 4;
BA_ "SPN" SG_ 2566705662 FlashProtectLamp 3041;
BA_ "SAEDocument" SG_ 2566705662 FlashProtectLamp "J1939-73";
BA_ "SigType" SG_ 2566705662 FlashAmberWarningLamp 4;
BA_ "SPN" SG_ 2566705662 FlashAmberWarningLamp 3040;
BA_ "SAEDocument" SG_ 2566705662 FlashAmberWarningLamp "J1939-73";
BA_ "SigType" SG_ 2566705662 FlashRedStopLamp 4;
BA_ "SPN" SG_ 2566705662 FlashRedStopLamp 3039;
BA_ "SAEDocument" SG_ 2566705662 FlashRedStopLamp "J1939-73";
BA_ "SigType" SG_ 2566705662 FlashMalfuncIndicatorLamp 4;
BA_ "SPN" SG_ 2566705662 FlashMalfuncIndicatorLamp 3038;
BA_ "SAEDocument" SG_ 2566705662 FlashMalfuncIndicatorLamp "J1939-73";
BA_ "SigType" SG_ 2566705662 ProtectLampStatus 4;
BA_ "SPN" SG_ 2566705662 ProtectLampStatus 987;
BA_ "SAEDocument" SG_ 2566705662 ProtectLampStatus "J1939-73";
BA_ "SigType" SG_ 2566705662 AmberWarningLampStatus 4;
BA_ "SPN" SG_ 2566705662 AmberWarningLampStatus 624;
BA_ "SAEDocument" SG_ 2566705662 AmberWarningLampStatus "J1939-73";
BA_ "SigType" SG_ 2566705662 RedStopLampState 4;
BA_ "SPN" SG_ 2566705662 RedStopLampState 623;
BA_ "SAEDocument" SG_ 2566705662 RedStopLampState "J1939-73";
BA_ "SigType" SG_ 2566705662 MalfunctionIndicatorLampStatus 4;
BA_ "SPN" SG_ 2566705662 MalfunctionIndicatorLampStatus 1213;
BA_ "SAEDocument" SG_ 2566705662 MalfunctionIndicatorLampStatus "J1939-73";
BA_ "SPN" SG_ 2349465342 StaticRollAngleStatus 5583;
BA_ "SigType" SG_ 2349465342 StaticRollAngle 1;
BA_ "SPN" SG_ 2349465342 StaticRollAngle 5582;
BA_ "SigType" SG_ 2566767614 AccelPedal2Channel3 1;
BA_ "SPN" SG_ 2566767614 AccelPedal2Channel3 2626;
BA_ "SigType" SG_ 2566767614 AccelPedal2Channel2 1;
BA_ "SPN" SG_ 2566767614 AccelPedal2Channel2 2625;
BA_ "SigType" SG_ 2566767614 AccelPedal1Channel3 1;
BA_ "SPN" SG_ 2566767614 AccelPedal1Channel3 2624;
BA_ "SigType" SG_ 2566767614 AccelPedal1Channel2 1;
BA_ "SPN" SG_ 2566767614 AccelPedal1Channel2 2623;
BA_ "SigType" SG_ 2559049470 DesiredEngFuelingState 5;
BA_ "SPN" SG_ 2559049470 DesiredEngFuelingState 5793;
VAL_ 3221225472 ManufacturerSpecific8 255 "NotAvailable" ;
VAL_ 3221225472 ManufacturerSpecific7 255 "NotAvailable" ;
VAL_ 3221225472 ManufacturerSpecific6 255 "NotAvailable" ;
VAL_ 3221225472 ManufacturerSpecific5 255 "NotAvailable" ;
VAL_ 3221225472 ManufacturerSpecific4 255 "NotAvailable" ;
VAL_ 3221225472 ManufacturerSpecific3 255 "NotAvailable" ;
VAL_ 3221225472 CabNoiseCtrlTuningCmd 7 "Dont Care NOT Commanded" 6 "Reserved" 5 "Exit Tuning Saving Parameters" 4 "Exit Tuning Not Saving Parameters" 3 "Remain In Tuning Save Current Parameters" 2 "Activate Automatic Tuning State Saveing Parameters Exit on Completion" 1 "Activate Automatic Tuning Wait for Save and Exit Commands" 0 "Activate Manual Tuning Wait for Save and Exit Commands" ;
VAL_ 3221225472 CabNoiseCtrlCmd 3 "Dont Care/Not Commanded" 2 "Reserved" 1 "Bring Cab Noise Control System On Line" 0 "Take Cab Noise Control System Off Line" ;
VAL_ 3221225472 MagnetGeneratorCtrl 3 "Take No Action" 2 "Reserved" 1 "On Enable Generator" 0 "Off Disable Generator" ;
VAL_ 3221225472 EngExhstBckPrssRgltrCtrlOprtnStt 15 "Not available" 14 "Error" 6 "1101 Reserved for future assignment" 5 "Uncontrolled Shutdown Active actuator current is off so it is limp" 4 "Controlled Shutdown Active driving to the default position  usually this means closed" 3 "Derate Active torque output reduced due to environmental conditions" 2 "Alarm High Severity functional but transient performance may be reduced" 1 "Alarm fully operational but needs service" 0 "Normal" ;
VAL_ 3221225472 EngExhstBckPrssRglatorTempStatus 7 "Not available" 6 "Error" 5 "Not Defined" 4 "Low Most severe" 3 "Low Least severe" 2 "In Range" 1 "High Least severe" 0 "High most severe" ;
VAL_ 3221225472 DslPrtcltFltr1CndtnsNtMtFrActvRg 3 "not available" 2 "reserved for SAE assignment" 1 "active DPF regeneration inhibited" 0 "active DPF regeneration not inhibited" ;
VAL_ 3221225472 DslPrtcltFltrActvRgnrtnInhbt5629 3 "not available" 2 "reserved for SAE assignment" 1 "inhibited" 0 "not inhibited" ;
VAL_ 3221225472 HydrocarbonDoserPurgingEnable 3 "Not available" 2 "Purging enabled  urgent" 1 "Purging enabled  less urgent" 0 "Purging not enabled" ;
VAL_ 3221225472 DslPrtcltFltrActvRgnrtnInhbt3717 3 "not available" 2 "reserved for SAE assignment" 1 "inhibited" 0 "not inhibited" ;
VAL_ 3221225472 DslPrtcltFltrActvRgnrtnInhbtdDTE 3 "not available" 2 "reserved for SAE assignment" 1 "inhibited" 0 "not inhibited" ;
VAL_ 3221225472 DslPrtcltFltrActvRgnrtnInhbt3715 3 "not available" 2 "reserved for SAE assignment" 1 "inhibited" 0 "not inhibited" ;
VAL_ 3221225472 DslPrtcltFltrActvRgnrtnInhbt3713 3 "not available" 2 "reserved for SAE assignment" 1 "inhibited" 0 "not inhibited" ;
VAL_ 3221225472 DslPrtcltFltrActvRgnrtnInhbt3712 3 "not available" 2 "reserved for SAE assignment" 1 "inhibited" 0 "not inhibited" ;
VAL_ 3221225472 DslPrtcltFltrActvRgnrtnInhbt3710 3 "not available" 2 "reserved for SAE assignment" 1 "inhibited" 0 "not inhibited" ;
VAL_ 3221225472 DslPrtcltFltrActvRgnrtnInhbtdDTV 3 "not available" 2 "reserved for SAE assignment" 1 "inhibited" 0 "not inhibited" ;
VAL_ 3221225472 DslPrtcltFltrActvRgnrtnInhbtdDTO 3 "not available" 2 "reserved for SAE assignment" 1 "inhibited" 0 "not inhibited" ;
VAL_ 3221225472 TransOilLevel2MeasurementStatus 15 "Not available" 14 "Error" 13 "Conditions not valid  Other" 12 "Not defined" 11 "Not defined" 10 "Not defined" 9 "Conditions not valid  No request for reading" 8 "Conditions not valid  Engine speed too high" 7 "Conditions not valid  Engine speed too low" 6 "Conditions not valid  Vehicle not level" 5 "Conditions not valid  Vehicle moving output shaft speed too high" 4 "Conditions not valid  Transmission fluid temperature too high" 3 "Conditions not valid  Transmission fluid temperature too low" 2 "Conditions not valid  Transmission in gear" 1 "Conditions not valid  Settling timer still counting down" 0 "Conditions valid for transmission oil level measurement" ;
VAL_ 3221225472 TransOilLevel2CountdownTimer 15 "Not Available" 14 "Error" 13 "Thirteen minutes" 12 "Twelve minutes" 11 "Eleven minutes" 10 "Ten minutes" 9 "Nine minutes" 8 "Eight minutes" 7 "Seven minutes" 6 "Six minutes" 5 "Five minutes" 4 "Four minutes" 3 "Three minutes" 2 "Two minutes" 1 "One minute" 0 "less than 1 minute" ;
VAL_ 3221225472 Aftrtrtmnt1DslExhstFluidProperty 15 "Not available" 14 "Error detected with urea reagent type detection" 13 "Not able to determine catalyst reagent type type unknown" 5 "to 1100  Reserved for SAE assignment" 3 "Catalyst reagent is proper mixture" 2 "Catalyst reagent is diesel" 1 "Catalyst reagent is urea concentration too low" 0 "Catalyst reagent is urea concentration too high" ;
VAL_ 3221225472 TrailerVDCActive 3 "Not availble or not installed" 2 "Reserved" 1 "VDC active" 0 "VDC passive but installed" ;
VAL_ 3221225472 TransLoadReductionInhibitRq 3 "Dont care/take no action" 2 "Reserved" 1 "Inhibit or abort transmission load reduction functions" 0 "Allow or resume transmission load reduction functions" ;
VAL_ 3221225472 ClntLvlEngPrtctionShutdownStatus 3 "Not Available" 2 "Reserved" 1 "Enabled  calibration allows engine protection due to low coolant level and the override is currently not active" 0 "Disabled  calibration does not allow engine protection due to low coolant level or the override is currently active" ;
VAL_ 3221225472 EngFuelCtrlCtrlMode 3 "Not available" 2 "SAE reserved" 1 "Closed loop" 0 "Open loop" ;
VAL_ 3221225472 EmergencyBrakingActive 3 "not available" 2 "reserved" 1 "active" 0 "inactive" ;
VAL_ 3221225472 EngCldStrtFlIgniterRelayFeedback 3 "Not available" 2 "Error" 1 "On" 0 "Off" ;
VAL_ 3221225472 EngColdStartFuelIgniterRelay 3 "Dont care/take no action" 2 "Reserved" 1 "On" 0 "Off" ;
VAL_ 3221225472 ParkBrakeCmd 3 "Dont care/Take no action" 2 "SAE Reserved" 1 "Park Brake apply requested" 0 "Park Brake apply not requested" ;
VAL_ 3221225472 Armrest2Switch2 3 "Dont care/take no action" 2 "Reserved" 1 "On" 0 "Off" ;
VAL_ 3221225472 Armrest2Switch1 3 "Dont care/take no action" 2 "Reserved" 1 "On" 0 "Off" ;
VAL_ 3221225472 Armrest1Switch2 3 "Dont care/take no action" 2 "Reserved" 1 "On" 0 "Off" ;
VAL_ 3221225472 Armrest1Switch1 3 "Dont care/take no action" 2 "Reserved" 1 "On" 0 "Off" ;
VAL_ 3221225472 Aftrtrtmnt2DslExhstFlidPumpState 3 "not available" 2 "reserved for SAE assignment" 1 "pump error" 0 "pump operational" ;
VAL_ 3221225472 Aftrtrtmnt2DeselExhaustFluidType 15 "Not available" 14 "Error detected with urea reagent type detection" 13 "Not able to determine catalyst reagent type type unknown" 5 "to 1100  Reserved for SAE assignment" 3 "Catalyst reagent is proper mixture" 2 "Catalyst reagent is diesel" 1 "Catalyst reagent is urea concentration too low" 0 "Catalyst reagent is urea concentration too high" ;
VAL_ 3221225472 Aftrtrtmnt2DslExhstFldLneHeater4 3 "not available" 2 "reserved for future assignment by SAE" 1 "request for heater to be active" 0 "request for heater to be inactive" ;
VAL_ 3221225472 Aftrtrtmnt2DslExhstFldLneHeater3 3 "not available" 2 "reserved for future assignment by SAE" 1 "request for heater to be active" 0 "request for heater to be inactive" ;
VAL_ 3221225472 Aftrtrtmnt2DslExhstFldLneHeater2 3 "not available" 2 "reserved for future assignment by SAE" 1 "request for heater to be active" 0 "request for heater to be inactive" ;
VAL_ 3221225472 Aftrtrtmnt2DslExhstFldLneHeater1 3 "not available" 2 "reserved for future assignment by SAE" 1 "request for heater to be active" 0 "request for heater to be inactive" ;
VAL_ 3221225472 Aftrtrtmnt2DslExhstFldDsrHtngMdR 7 "Not available" 4 "110 Reserved" 3 "Heater on" 2 "Heater automatic mode" 1 "Heater economy mode" 0 "Heater off" ;
VAL_ 3221225472 Aftrtrtmnt2DslExhstFldDsrFltSppr 3 "Not available" 2 "Reserved" 1 "Error suppression on" 0 "Error suppression off" ;
VAL_ 3221225472 Aftrtrtmnt2DslExhstFldLnHtr4Stte 3 "not available" 2 "error" 1 "heater active" 0 "heater inactive" ;
VAL_ 3221225472 Aftrtrtmnt2DslExhstFldLnHtr3Stte 3 "not available" 2 "error" 1 "heater active" 0 "heater inactive" ;
VAL_ 3221225472 Aftrtrtmnt2DslExhstFldLnHtr2Stte 3 "not available" 2 "error" 1 "heater active" 0 "heater inactive" ;
VAL_ 3221225472 Aftrtrtmnt2DslExhstFldLnHtr1Stte 3 "not available" 2 "error" 1 "heater active" 0 "heater inactive" ;
VAL_ 3221225472 Aftrtrtmnt1DslExhstFlidPumpState 3 "not available" 2 "reserved for SAE assignment" 1 "pump error" 0 "pump operational" ;
VAL_ 3221225472 Aftrtrtmnt1DslExhstFldLneHeater4 3 "not available" 2 "reserved for future assignment by SAE" 1 "request for heater to be active" 0 "request for heater to be inactive" ;
VAL_ 3221225472 Aftrtrtmnt1DslExhstFldLneHeater3 3 "not available" 2 "reserved for future assignment by SAE" 1 "request for heater to be active" 0 "request for heater to be inactive" ;
VAL_ 3221225472 Aftrtrtmnt1DslExhstFldLneHeater2 3 "not available" 2 "reserved for future assignment by SAE" 1 "request for heater to be active" 0 "request for heater to be inactive" ;
VAL_ 3221225472 Aftrtrtmnt1DslExhstFldLneHeater1 3 "not available" 2 "reserved for future assignment by SAE" 1 "request for heater to be active" 0 "request for heater to be inactive" ;
VAL_ 3221225472 Aftrtrtmnt1DslExhstFldDsrHtngMdR 7 "Not available" 4 "110 Reserved" 3 "Heater on" 2 "Heater automatic mode" 1 "Heater economy mode" 0 "Heater off" ;
VAL_ 3221225472 Aftrtrtmnt1DslExhstFldDsrFltSppr 3 "Not available" 2 "Reserved" 1 "Error suppression on" 0 "Error suppression off" ;
VAL_ 3221225472 Aftrtrtmnt1DslExhstFldLnHtr4Stte 3 "not available" 2 "error" 1 "heater active" 0 "heater inactive" ;
VAL_ 3221225472 Aftrtrtmnt1DslExhstFldLnHtr3Stte 3 "not available" 2 "error" 1 "heater active" 0 "heater inactive" ;
VAL_ 3221225472 Aftrtrtmnt1DslExhstFldLnHtr2Stte 3 "not available" 2 "error" 1 "heater active" 0 "heater inactive" ;
VAL_ 3221225472 Aftrtrtmnt1DslExhstFldLnHtr1Stte 3 "not available" 2 "error" 1 "heater active" 0 "heater inactive" ;
VAL_ 3221225472 NOxSensorATO1SelfdiagnosisStatus 7 "Not Supported" 5 "110 Reserved" 4 "NOx Sensor ATO1 Self Diagnosis not possible" 3 "NOx Sensor ATO1 Self Diagnosis aborted" 2 "NOx Sensor ATO1 Self Diagnosis Result Complete" 1 "NOx Sensor ATO1 Self Diagnosis active flag" 0 "Diagnosis not active" ;
VAL_ 3221225472 NOxSensorATI1SelfdiagnosisStatus 7 "Not Supported" 5 "110 Reserved" 4 "NOx Sensor ATI1 Self Diagnosis not possible" 3 "NOx Sensor ATI1 Self Diagnosis aborted" 2 "NOx Sensor ATI1 Self Diagnosis Result Complete" 1 "NOx Sensor ATI1 Self Diagnosis active flag" 0 "Diagnosis not active" ;
VAL_ 3221225472 NOxSensorATO2SelfdiagnosisStatus 7 "Not Supported" 5 "110 Reserved" 4 "NOx Sensor ATO2 Self Diagnosis not possible" 3 "NOx Sensor ATO2 Self Diagnosis aborted" 2 "NOx Sensor ATO2 Self Diagnosis Result Complete" 1 "NOx Sensor ATO2 Self Diagnosis active flag" 0 "Diagnosis not active" ;
VAL_ 3221225472 NOxSensorATI2SelfdiagnosisStatus 7 "Not Supported" 5 "110 Reserved" 4 "NOx Sensor ATI2 Self Diagnosis not possible" 3 "NOx Sensor ATI2 Self Diagnosis aborted" 2 "NOx Sensor ATI2 Self Diagnosis Result Complete" 1 "NOx Sensor ATI2 Self Diagnosis active flag" 0 "Diagnosis not active" ;
VAL_ 3221225472 ProprietaryNetwork2 3 "Don't care" 2 "Reserved" 1 "Start broadcast" 0 "Stop broadcast" ;
VAL_ 3221225472 ProprietaryNetwork1 3 "Don't care" 2 "Reserved" 1 "Start broadcast" 0 "Stop broadcast" ;
VAL_ 3221225472 TransOilLevel1MeasurementStatus 15 "Not available" 14 "Error" 13 "Conditions not valid  Other" 12 "Not defined" 9 "Conditions not valid  No request for reading" 8 "Conditions not valid  Engine speed too high" 7 "Conditions not valid  Engine speed too low" 6 "Conditions not valid  Vehicle not level" 5 "Conditions not valid  Vehicle moving output shaft speed too high" 4 "Conditions not valid  Transmission fluid temperature too high" 3 "Conditions not valid  Transmission fluid temperature too low" 2 "Conditions not valid  Transmission in gear" 1 "Conditions not valid  Settling timer still counting down" 0 "Conditions valid for transmission oil level measurement" 11 "Not defined" 10 "Not defined" ;
VAL_ 3221225472 TransOilLevel1CountdownTimer 15 "Not Available" 14 "Error" 13 "Thirteen minutes" 12 "Twelve minutes" 11 "Eleven minutes" 10 "Ten minutes" 9 "Nine minutes" 8 "Eight minutes" 7 "Seven minutes" 6 "Six minutes" 5 "Five minutes" 4 "Four minutes" 3 "Three minutes" 2 "Two minutes" 1 "One minute" 0 "less than 1 minute" ;
VAL_ 3221225472 TirePressThresholdDetection 7 "Not available" 6 "Error indicator" 5 "Not defined" 4 "Extreme under pressure  The tire pressure is at a level where the safety of the vehicle may be jeopardised" 3 "Under pressure  The tire pressure is lower than the pressure defined by the vehicle or tire manufacturer" 2 "No warning pressure  The tire pressure is within the thresholds defined by the vehicle or tire manufacturer" 1 "Over pressure  The tire pressure is higher than the pressure defined by the vehicle or tire manufacturer" 0 "Extreme over pressure  The tire pressure is at a level where the safety of the vehicle may be jeopardised" ;
VAL_ 3221225472 CTIWheelEndElectricalFault 3 "Not Supported" 2 "Error" 1 "Not Defined" 0 "Ok  No Fault" ;
VAL_ 3221225472 CTITireStatus 3 "Not Supported" 2 "Error" 1 "Tire leak detected" 0 "Ok no fault" ;
VAL_ 3221225472 CTIWheelSensorStatus 3 "Not Supported" 2 "Not Defined" 1 "On tire is polled" 0 "Off / isolated from CTI Pressure Controller" ;
VAL_ 3221225472 EngTurningGearEngaged 1 "Engaged" 0 "Not engaged" 3 "Not available" 2 "Error" ;
VAL_ 3221225472 KeyActivationCode 3 "KeyPressAborted" 0 "KeyHasBeenReleased" 1 "KeyHasBeenPressed" 2 "KeyIsStillHeld" ;
VAL_ 3221225472 ButtonActivationCode 3 "ButtonPressAborted" 0 "ButtonHasBeenUnlatched" 1 "ButtonHasBeenLatched" 2 "ButtonsStillHeld" ;
VAL_ 3221225472 LockUnlockCommand 1 "LockMask" 0 "UnlockMask" ;
VAL_ 3221225472 KeyObjectID 0 "KeyHasBeenReleased" 1 "KeyHasBeenPressed" 2 "KeyIsStillHeld" ;
VAL_ 3221225472 ButtonObjectID 0 "ButtonHasBeenUnlatched" 1 "ButtonHasBeenLatched" 2 "ButtonsStillHeld" ;
VAL_ 3221225472 Status_1 1 "Shown" 0 "Hidden" ;
VAL_ 3221225472 VTSelectInputObjectStatus 0 "ObjectIsDeselected" 1 "ObjectIsSelected" ;
VAL_ 3221225472 SubCommandID 20 "CopyViewportToPictureGraphic" 19 "CopyCanvasToPictureGraphic" 18 "DrawVTObject" 17 "ChangeViewportSize" 16 "PanAndZoomViewport" 15 "ZoomViewport" 14 "PanViewport" 13 "DrawText" 12 "DrawPolygon" 11 "DrawClosedEllipse" 10 "DrawRectangle" 9 "DrawLine" 8 "DrawPoint" 7 "EraseRectangle" 6 "SetFontAttributesID" 5 "SetFillAttributesObjectID" 4 "SetLineAttributesObjectID" 3 "SetBackgroundColour" 2 "SetForegroundColour" 1 "MoveGraphicsCursor" 0 "SetGraphicsCursor" ;
VAL_ 3221225472 KeyObjectParentID 0 "KeyHasBeenReleased" 1 "KeyHasBeenPressed" 2 "KeyIsStillHeld" ;
VAL_ 3221225472 ButtonObjectParentID 0 "ButtonHasBeenUnlatched" 1 "ButtonHasBeenLatched" 2 "ButtonsStillHeld" ;
VAL_ 3221225472 ManufacturerCode 520 "Trapeze" 519 "Peeters Landbouwmachines b.v." 518 "Transas USA Inc." 517 "Noland Engineering" 516 "AVAT Automation GmbH" 515 "GINAF Trucks Nederland B.V." 514 "DISTek Integration, Inc." 513 "FarmscanAg" 512 "Inpower LLC" 511 "Sulky" 510 "Marinesoft Co. Ltd" 509 "MOTORTECH GmbH" 508 "Transtech Innovations" 507 "Test Center ISOBUS" 506 "IHI STAR Machinery Corporation" 505 "Yetter Farm Equipment" 504 "Vesper Marine" 503 "Naviop S.R.L." 502 "Attwood Corporation" 501 "Agrotronix S.A." 500 "Oxbo International Corporation" 499 "LCJ Capteurs" 498 "Innovative Design Solutions, Inc." 497 "SENTRON Sistemas Embarcados" 496 "W. Gessmann GmbH" 495 "HOLMER Maschinenbau GmbH" 494 "Synerject" 493 "Watcheye" 492 "Inergy Automotive Systems" 491 "Penny and Giles Ltd" 490 "QuikQ" 489 "Appareo Systems" 488 "The Charles Machine Works, Inc." 487 "DSE Test Solutions A/S" 486 "Westport Innovations Inc." 485 "MATT automotive" 484 "Headsight Inc." 483 "Valeo" 482 "Tricon Electronics" 481 "Chetco Digital Instruments" 480 "EnerDel, Inc." 454 "NGK Spark Plug Co. Ltd" 453 "Cooper Bussmann" 452 "WIKA Alexander Wiegand SE & Co. KG" 451 "Parker Hannifin Corp" 450 "Dycor Technologies Ltd." 449 "Polaris Industries Inc" 448 "Stanadyne Corporation, Electronics Systems" 447 "Great Plains Mfg." 446 "CertTech, L.L.C." 445 "KAT MECHATRONIC, Electronic Product Division" 444 "ITT Power Solutions" 443 "SignalQuest, Inc." 442 "Horsch Maschinen GmbH" 441 "PTG Reifendruckregelsysteme GmbH" 440 "Cummins Power Generation" 439 "Hyundai Heavy Industries" 438 "Comar Systems Ltd" 437 "Digital Yacht Limited" 436 "Kinze Manufacturing" 435 "Zunhammer GmbH" 434 "Stored Energy Systems" 433 "Rowe Electronics" 432 "S&A Systems, Inc." 431 "Tohatsu Corporation" 430 "Auteq Telematica S.A." 479 "Vapor Bus International" 478 "OceanSat BV" 477 "OilQuick AB" 476 "Hummingbird Marine Electronics" 475 "GME" 474 "Persen Technologies Inc." 473 "Boss Industries, Inc." 472 "Tenneco Inc." 471 "Sea Cross Marine AB" 470 "SI-TEX Marine Electronics" 469 "RA Consulting GmbH" 468 "Tyco Fire Protection Products" 467 "Lely Industries N.V." 466 "Veethree Electronics and Marine LLC" 465 "Ashcroft Inc" 464 "Leach International Corporation" 463 "PROBOTIQ" 462 "IHI Shibaura Machinery Corporation" 461 "HAWE Hydraulik SE" 460 "San Giorgio S.E.I.N." 459 "Alltek Marine Electronics Corp" 458 "Control Solutions, Inc." 457 "RUSELPROM-ElectricDrive Ltd" 456 "General Kinetics" 455 "ADZ NAGANO GmbH" 429 "Rota Engineering Ltd." 428 "Mfg_428" 427 "em-trak Marine Electronics Ltd" 426 "Egersund Marine Electronics AS" 425 "Methode Electronics Inc, MDI" 424 "Odyne LLC" 423 "BSM Wireless, Inc." 422 "True Heading AB" 421 "Vertex Standard Co., Ltd" 420 "Vermeer Corporation, ACS Group" 419 "Fusion Electronics Ltd" 418 "Intellistick Inc" 417 "KZValve" 416 "Kubota Corporation" 415 "Valid Manufacturing Ltd." 414 "Cattron Group International" 413 "Datapross Nijbroek bv" 412 "WebTech Wireless Inc." 411 "Hy-Drive Technologies Ltd." 410 "COBO S.p.A. Divisione 3B6" 409 "Transfluid S.r.L." 408 "Corvus Energy Ltd." 407 "Comtech Mobile Datacom" 406 "Vecima Networks Inc." 405 "Wema System AS" 404 "Com Nav Marine Ltd" 403 "Trackwell ADS, Inc." 402 "Simma Software, Inc." 401 "Torqeedo GmbH" 400 "Livorsi Marine" 399 "ISEKI & Co., Ltd." 398 "Hilite International" 397 "Sanyo-kiki Co Ltd." 396 "Beyond Measure" 395 "GENTEC S.R.L." 394 "Capi 2 Nederland BV" 393 "Harvest Tec, Inc" 392 "Tianyuan Technology Co Ltd." 391 "Electronic Design for Industry, Inc" 390 "Partech Inc." 389 "Benchmark Electronics, Minnesota Division" 388 "Innomatix, LLC" 387 "Orscheln Products, LLC" 386 "JLG Automation BVBA" 385 "Johnson Outdoor Marine Electronics" 384 "Camano Light" 383 "MCL Industries" 382 "National Agricultural and Food Research Organization" 380 "Suntech International Ltd." 379 "Yamabiko Corporation" 378 "Glendinning Marine Products" 377 "ifm electronic gmbh" 376 "Quake Global" 375 "Williams Controls Inc." 372 "Delphi" 381 "B&G" 374 "Northern Lights, Inc." 373 "Electronic Design Inc." 371 "Heinzmann GmbH & Co. KG" 370 "Rolls-Royce Marine AS" 369 "Power Torque Engineering Ltd" 368 "HANSENHOF_electronic" 367 "Fliegl Agrartechnik" 366 "Viewnyx Corp." 365 "Digi-Star, LLC" 364 "OEM Controls Inc." 363 "BEI Duncan" 362 "Alois Poettinger Maschinenfabrik GmbH" 361 "InMach" 360 "HJS Emission Technology GmbH & Co KG" 359 "Ludwig Bergmann GmbH" 358 "Victron Energy BV" 357 "Hardi International A/S" 356 "Fischer Panda Generators, Inc" 355 "Mastervolt International B.V." 354 "Junkkari OY" 353 "Hegemon Electronics, Inc." 352 "SAME DEUTZ-FAHR" 351 "Thrane & Thrane" 350 "Noris Marine Systems GmbH & Co KG" 349 "Suonentiet" 348 "Amazonen Werke H. Dreyer" 347 "Honeywell" 346 "Control Solutions" 345 "Korean Maritime University" 344 "Parvus Corporation" 343 "Baumer Group" 342 "THOMAS MAGNETE GmbH" 341 "Boning GmbH & Co" 340 "Continental AG" 339 "Competence Center ISOBUS e.V." 338 "GRAF-SYTECO" 337 "Carraro S.p.A." 336 "APE s.r.o." 335 "Evo Electric Ltd" 334 "Takata-Petri AG" 333 "Hadley Products Corporation" 332 "HWH Corporation" 331 "Horton, Inc." 330 "Kidde Aerospace and Defense" 329 "Deif A/S" 328 "Qwerty Electronik AB" 252 "Sensor-Technik Wiedemann GmbH" 251 "German Agricultural Society" 250 "Kuhn Group" 249 "Schaltbau GmbH" 233 "Yacht Monitoring Solutions Inc." 232 "TSD Integrated Controls" 1863 "Thomas G. Faria Co." 1862 "Sanshin" 1861 "Vector CANtech" 1860 "MMP" 1859 "Kvasar AB" 1858 "Litton" 1857 "Simrad" 1856 "Trimble" 1855 "Furuno USA" 1854 "Northstar Technologies" 1853 "Japan Radio Co." 1852 "Navionics" 1851 "Raymarine" 1850 "Teleflex" 222 "Generac Power Systems, Inc." 221 "SiE" 220 "Beede Electrical Instrument Company, Inc." 219 "Cat OEM Solutions" 218 "Gits Manufacturing Company" 217 "RM Michaelides Software & Elektronik GmbH" 216 "Paneltronics Inc." 215 "Aetna Engineering/Fireboy-Xintex" 214 "MC elettronica Srl" 213 "CNH Belgium N.V." 212 "Sure Power Industries, Inc." 211 "DNA Group" 210 "Iteris, Inc." 209 "Bell Equip. Co. SA (PTY) LTD" 208 "Drew Technologies, Inc." 207 "Otto Engineering" 206 "port GmbH" 205 "SmarTire Systems Inc" 204 "The Morey Corporation" 203 "MILtronik GmbH" 202 "Curtis Instruments, Inc." 201 "Disenos y Tecnologia S.A." 200 "MGM Brakes" 199 "Actia Corp." 198 "Mystic Valley Communications" 197 "Mechron Power Systems" 196 "LEMKEN GmbH & Co. KG" 195 "General Engine Products" 194 "TriMark Corporation" 193 "Nobletec" 192 "Floscan" 191 "XRS Corporation" 190 "Hella KGaA Hueck & Co." 189 "QUALCOMM" 188 "EMP Corp." 187 "Air-Weigh" 186 "Altronic, Inc." 185 "Beede Electrical Instrument Company" 184 "EIA Electronics" 183 "KDS Controls, Inc." 182 "Vehicle Systems Engineering B.V." 181 "Coretronics, Inc." 180 "Smart Power Systems" 179 "TeeJet Technologies Denmark" 178 "Siemens VDO Automotive AG" 177 "Diagnostic System Associates" 176 "Moritz Aerospace" 175 "Veris Technologies, Inc." 174 "AB Volvo Penta" 173 "Ryeso, Inc." 172 "Yanmar Marine USA" 171 "Wachendorff Elektronik GmbH & Co. KG" 170 "Computronics Corporation Ltd." 169 "Marlin Technologies Inc." 168 "Xantrex" 167 "JLG Industries Inc." 166 "Phoenix International" 165 "CPAC Systems AB" 164 "DaimlerChrysler Off-Highway" 163 "BRP Inc." 162 "Axiomatic Technologies" 161 "Offshore Systems (UK) Limited" 160 "Nido" 159 "NTech Industries Inc." 158 "Firestone Industrial Products Company" 157 "ISSPRO Inc." 156 "ITT Industries - Cannon" 155 "Vetronix Corporation" 154 "Westerbeke Corporation" 153 "Woodward, Industrial Controls Division" 152 "elobau GmbH & Co. KG" 151 "Raven Industries Inc. - Flow Controls Division" 150 "Fleetguard" 149 "Holset" 148 "Blue Water Data, Inc." 147 "Nautibus Electronic GmbH" 146 "Maxima Technologies" 145 "MurCal Controls" 144 "Mercury Marine" 143 "W. Gmeiner GmbH & Co." 142 "TRW Automotive (Commercial Steering Systems)" 141 "Thales Navigation Ltd." 140 "Lowrance Electronics, Inc." 139 "Caterpillar Trimble Control Technologies (CTCT), LLC" 138 "Georg Fritzmeier GmbH & Co. KG" 137 "Maretron" 136 "Komatsu Ltd." 135 "Airmar Technology Corporation" 134 "Iris Technology Ltd." 133 "Bucher Schoerling GmbH" 132 "Mulag-Fahrzeugwerk" 131 "ITT Industries" 130 "Nido - Universal Machines B.V." 129 "OMNEX Control Systems, Inc." 128 "Gerhard Duecker GmbH & Co. KG" 127 "Holland USA" 126 "Driver Tech" 125 "Nevada Automotive Test Center" 124 "Hydac Electronic" 123 "Basler Electric" 122 "FG Wilson (Engineering) Limited" 121 "HED (Hydro Electronic Devices, Inc.)" 120 "RDS Technology Ltd." 119 "IntegriNautics" 118 "Intron GmbH" 117 "HUSCO International" 116 "BEELINE Technologies" 115 "NACCO Materials Handling Group, Inc." 114 "EControls, Inc." 113 "Stress-Tek, Inc." 112 "MECALAC" 111 "Maschinenfabrik Bernard Krone GmbH" 110 "EPIQ Sensor-Nite" 109 "TeeJet Technologies Denmark" 108 "WTK-Elecktronik GmbH" 107 "Grimme Landmaschinen GmbH & Co. KG" 106 "BAE Systems Controls, Inc." 105 "Kiepe Elektrik GmbH & Co. KG" 104 "Claas Selbstfahrende Erntemaschinen GmbH" 103 "CLAAS Agrosystems GmbH & Co. KG" 102 "AGCO GmbH & Co." 101 "Sensoria" 100 "VDO Technik AG" 99 "International Transmissions Ltd (ITL)" 98 "Mueller-Elektronik GmbH & Co." 97 "Ag Leader Technology, Inc." 96 "Mech@tronic IT GmbH" 95 "Pacific Insight Electronics Corp." 94 "CNH Global N.V." 93 "Perkins Engines Company Ltd." 92 "Ag-Chem Equipment Co., Inc." 91 "BSG Bodensee Steuergeraete GmbH" 90 "Knorr-Bremse SfN GmbH" 89 "Kverneland Group, Electronics Division" 88 "Satloc Precision GPS" 87 "J.C. Bamford Excavators Ltd (JCB)" 86 "C.E. Niehoff & Company" 85 "Kohler Co." 84 "New Holland UK Limited" 83 "Bendix VORAD Technologies" 82 "Bobcat/Ingersoll-Rand" 81 "Fire Research Corp" 80 "Twin Disc, Inc." 79 "Daimler Benz AG - Engine Division (PBM)" 78 "Frank W. Murphy Manufacturing, Inc." 77 "Deere Power Systems Group" 76 "unused" 75 "Deere & Co. Agricultural Division" 74 "Eaton Axle-Brake Division" 73 "LeTourneau, Inc." 72 "Sisu Corporation" 71 "Vansco Electronics Ltd." 70 "Flex-Coil Limited" 69 "Trimble Navigation" 68 "Scania" 67 "Funk Manufacturing Company" 66 "John Deere Construction Equipment Division" 65 "MAN Nutzfahrzeuge AG" 64 "unused" 63 "ZF Industries Inc." 62 "Wabco" 61 "Volvo Truck Corp." 60 "Volvo Trucks North America Inc." 59 "VES Inc." 58 "SPX Corporation, OTC Division" 57 "Sauer-Danfoss Co." 56 "SAIC" 55 "Ryder System Inc." 54 "Meritor Wabco" 53 "Continental Automotive Systems US, Inc." 52 "Meritor Automotive, Inc." 51 "Robert Bosch GmbH" 50 "Robert Bosch Corp" 49 "RE America Inc." 48 "Pollak Alphabet" 47 "Phillips Semiconductor" 46 "Noregon Systems, Inc" 45 "PACCAR" 44 "Nippondenso Co. Ltd." 43 "International Truck and Engine Corp. Vehicle Electronics" 42 "International Truck and Engine Corp. Engine Electronics" 41 "Motorola Inc." 40 "Motorola AIEG Inc." 39 "Microfirm Inc." 38 "Micro Processor Systems Inc." 37 "Mack Trucks Inc." 36 "Lucas Ltd." 35 "Kenworth Truck Co." 34 "Kelsey Hayes Co." 33 "John Deere" 32 "Jacobs Vehicle Systems" 31 "J Pollak Corp." 30 "Isuzu Motors Ltd." 29 "Hino Motors Ltd." 28 "Grote Ind. Inc." 27 "GMC" 26 "General Motors Corp., Service Technology Group" 25 "Daimler Trucks North America LLC" 24 "Ford Motor Co., Vehicle Controls" 23 "Ford Motor Co., Heavy Truck" 22 "Ford Motor Co., Electronic Concepts $ Systems" 21 "Echilin Inc., Midland Brake Inc." 20 "Eaton Ltd" 19 "Eaton Corp. Trucking Info Services" 18 "Eaton Corp, Transmission Division" 17 "Eaton Corp. Res & Dev" 16 "Eaton Corp." 15 "Dickey-John Corp." 14 "Detroit Diesel Corporation" 13 "Delco Electronics" 12 "Deere & Company, Precision Farming" 11 "Dearborn Group Inc." 10 "Cummins Engine Co." 9 "Chrysler Corp." 8 "Caterpillar Inc." 7 "Case Corp." 6 "Berifors Electronics AB" 5 "AMP Inc." 4 "Ametek-Dixson" 3 "Ametek, US Gauge Division" 2 "Allison Transmission, GMC" 1 "Allied Signal Inc." 0 "Reserved" 231 "Topcon Positioning Systems, Inc." 230 "Saucon Technologies" 229 "Garmin International Inc." 228 "ZF Marine Electronics" 227 "Lykketronic A/S" 226 "Monaco Coach Corporation" 225 "SKF" 224 "EMMI Network, S.L." 223 "Vaueo Retarder Co., Ltd." 263 "IMMI" 262 "HydraForce, Inc" 261 "Red Dot Corporation" 260 "Reichhardt GmbH" 259 "Jetter AG" 258 "ARAG" 257 "Honda Motor Co., Ltd" 256 "Tyco Electronics AMP" 255 "MEAS France" 254 "GE Sensing" 253 "Mobile Control Systems" 298 "Holley Performance" 297 "Zonar Systems Inc" 296 "micro dynamics GmbH" 295 "BEP Marine" 294 "Grayhill Inc." 293 "Spyder Controls Corp." 292 "IKUSI - Angel Iglesias S.A." 291 "Groeneveld Transport Efficiency BV" 290 "Kuebler GmbH" 289 "Watlow" 288 "Mitsubishi FUSO Truck & Bus Corp." 287 "NTech Industries, Inc" 286 "Coelmo srl" 285 "Sea Recovery Corp" 284 "Mobile Tech Chile" 283 "CWF Hamilton & Co Ltd" 282 "Medallion Instrumentation Systems" 281 "Precision Governors LLC" 311 "Patrick Power Products" 310 "TECNORD srl" 309 "Krauss-Maffei Wegmann GmbH & Co. KG" 308 "Cyntrx" 307 "MBW Technologies" 306 "Sleipner Motor AB" 305 "NovAtel Inc" 304 "EmpirBus AB" 303 "CTS Corporation" 302 "Nissin Kogyo Co., LTD" 301 "Parker Hannifin (UK) Ltd FDE group" 300 "Systron Donner Automotive" 299 "Rauch Landmaschinen GmbH" 280 "Leica Geosystems Pty Ltd" 279 "Geometris LP" 278 "Takata Electronics" 277 "LHP Telematics" 276 "Aqua-Hot Heating Systems" 275 "Navico Egersund AS" 274 "LTW Technology Co., LTD" 273 "Active Research Limited" 272 "Gross Mechanical Laboratories, Inc" 327 "Sonceboz SA" 326 "Akron Brass Company" 325 "ASM Automation Sensorik Messtechnik GmbH" 324 "Snap-on Diagnostics" 323 "Mobileye Vision Technologies Ltd." 322 "MICHENKA s.r.o." 321 "Ultra Electronics, Electrics" 320 "Miedema Landbouwwerktuigenfabriek B.V." 319 "Cadec Global" 318 "SAT Plan" 317 "Navtronics Bvba" 316 "ITT Flow Control" 315 "Icom Incorporated" 314 "CSM GmbH" 313 "Ilmor Engineering, Inc" 312 "Lectronix, Inc." 271 "Cole Hersee" 270 "Tennant" 269 "Saft America Inc.,  Space & Defense Division" 268 "Accurate Technologies" 267 "Red Lion Controls, Inc" 266 "International Thermal Research Ltd" 265 "MTS Sensor Technologie GmbH" 264 "Autolync" 248 "Cooper Standard Automotive Active Systems Group" 247 "ePULSE" 246 "Class 1, Inc" 245 "Capstan Ag Systems, Inc." 244 "Techno-Matic" 243 "eRide, Inc." 242 "Kokusandenki Co. Ltd" 241 "Schneider Automation SAS " 240 "Vanair Mfg" 239 "May & Scofield Ltd" 238 "ZF Friedrichshafen AG" 237 "Agtron Enterprises Inc" 236 "Norac Systems International Inc" 235 "SailorMade Marine Telemetry - Tetra Technology Ltd." 234 "Mondial electronic GmbH" ;
VAL_ 3221225472 TouchState 255 "Pressed" 2 "Held" 1 "Pressed" 0 "Released" ;
VAL_ 3221225472 Status_2 1 "Shown" 0 "Hidden" ;
VAL_ 3221225472 SoftKeyCode 0 "AlarmACK" ;
VAL_ 3221225472 OperatingState1 1 "LearnModeActive" 0 "LearnModeInactive" ;
VAL_ 3221225472 Function 127 "Reserved" 126 "Reserved" 125 "Reserved" 124 "Reserved" 123 "Reserved" 122 "Reserved" 121 "Reserved" 120 "Reserved" 119 "Reserved" 118 "Reserved" 117 "Reserved" 116 "Reserved" 115 "Reserved" 114 "Reserved" 113 "Reserved" 112 "Reserved" 111 "Reserved" 110 "Reserved" 109 "Reserved" 108 "Reserved" 107 "Reserved" 106 "Reserved" 105 "Reserved" 104 "Reserved" 103 "Reserved" 102 "Reserved" 101 "Reserved" 42 "Water Pump Control" 41 "Lighting - Operator Controls" 40 "Seat Control" 39 "Ignition Control Module" 38 "Tire Pressure Control" 37 "Cab Controller" 36 "Pneumatic - System Controller" 35 "Suspension - System Controller" 34 "Hydraulic Pump Controller" 33 "System Monitor" 32 "Headway Controller" 31 "Propulsion Battery Charger" 30 "Management Computer" 29 "Virtual Terminal (in cab)" 28 "Off Vehicle Gateway" 27 "Power TakeOff (Secondary or Front)" 26 "Body Controller" 25 "Network Interconnect ECU" 24 "Vehicle Security" 23 "Vehicle Navigation" 22 "Aerodynamic Control" 21 "Cab Climate Control" 20 "Trip Recorder" 19 "Instrument Cluster" 18 "Suspension - Drive Axle" 17 "Suspension - Steer Axle" 16 "Steering Controller" 15 "Fuel System" 14 "Cruise Control" 13 "Retarder - Driveline" 12 "Retarder - Engine" 11 "Brakes - Drive Axle" 10 "Brakes - Steer Axle" 9 "Brakes - System Controller" 8 "Axle - Drive" 7 "Axle - Steering" 6 "Power TakeOff - (Main or Rear)" 5 "Shift Control/Console" 4 "Battery Pack Monitor" 3 "Transmission" 2 "Electric Propulsion Control" 1 "Auxiliary Power Unit (APU)" 0 "Engine" 100 "Reserved" 99 "Reserved" 98 "Reserved" 97 "Reserved" 96 "Reserved" 95 "Reserved" 94 "Reserved" 93 "Reserved" 92 "Reserved" 91 "Reserved" 90 "Reserved" 89 "Reserved" 88 "Reserved" 87 "Reserved" 86 "Reserved" 85 "Reserved" 84 "Reserved" 83 "Reserved" 82 "Reserved" 81 "Reserved" 80 "Reserved" 79 "Reserved" 78 "Fire Suppression System" 77 "Fuel Properties Sensor" 76 "Temperature Sensor" 75 "Supplemental Fan" 74 "Lubrication System" 73 "Rollover Detection Control" 72 "Coolant Valve Controller" 71 "Transfer Case Control" 70 "Auxiliary Regeneration Device" 69 "Engine Emission Aftertreatement System" 68 "Aftertreatment system gas measurement" 67 "Electrical System Controller" 66 "I/O Controller" 65 "Gas Flow Measurement" 64 "Endurance Braking" 63 "Engine Valve Controller" 62 "On-Board Diagnostic Unit" 61 "File Server/Printer" 60 "Cab Display" 59 "Starter" 58 "Fan Drive Control" 57 "Steering Column Unit" 56 "Communications Unit, Radio" 55 "Communications Unit, Satellite" 54 "Communications Unit, Cellular" 53 "Alternator/Charging System" 52 "Chassis Controller" 51 "Forward-Looking Collision Warning System" 50 "Auxiliary Heater" 49 "Clutch/Converter Control" 48 "Ramp Control" 47 "Information System Controller" 46 "Oil Sensor Unit" 45 "Vehicle Dynamic Stability Control" 44 "Exhaust Emission Control" 43 "Transmission Display" ;
VAL_ 3221225472 OperatingState2 1 "InputActivatedInLearnMode" 0 "InputNotActivatedInLearnMode" ;
VAL_ 3221225472 VehicleSystem2 25 "Slurry Applicators" 24 "Utility Vehicles" 23 "Mulchers" 22 "Timber Processing Machines" 21 "Timber loaders" 20 "Forwarders" 19 "Timber Harvesters" 17 "Sensor Systems" 16 "Skidder" 15 "Earth Work" 14 "Special Crops" 13 "Powered Auxiliary Device" 12 "Farm Yard Operations" 11 "Transport/Trailer" 10 "Irrigation" 9 "Forage" 8 "Root Harvesters" 7 "Harvesters" 6 "Sprayers" 5 "Fertilizers" 4 "Planters/Seeders" 3 "Secondary Tillage" 2 "Tillage" 1 "Tractor" 127 "Not Available" 0 "Non-specific System" ;
VAL_ 3221225472 IndustryGroup 6 "Reserved for SAE" 0 "Global" 1 "On-Highway" 2 "Agricultural and Forestry" 3 "Construction" 4 "Marine" 5 "IndustrialProcessCtrlStationary" 7 "Reserved for SAE" ;
VAL_ 3221225472 VTFunctionECUtoVT 39 "AuxiliaryCapabilitiesRequest" 214 "ExtendedDeleteVersion" 213 "ExtendedLoadVersion" 212 "ExtendedStoreVersion" 211 "ExtendedGetVersions" 191 "Execute OpCode" 188 "ExecuteExtendedMacro" 197 "GetSupportedObjects" 187 "Identify VT" 36 "AuxiliaryAssignmentResponseType2" 33 "Auxiliary Input Status" 193 "GetSupported WideChars" 37 "AuxiliaryInputStatusEnableCommandResponse" 35 "AuxiliaryInputMaintenance" 190 "ExecuteMacro" 189 "LockUnlockMask" 34 "AuxiliaryPreferredAssignment" 9 "VTOnUserLayoutHideShowResponse" 186 "SelectColourMap" 185 "GetAttribute" 184 "GraphicsContextCommand" 183 "ChangePolygonScale" 182 "ChangePolygonPoint" 181 "SetObjectLabel" 0 "SoftKeyActivationResponse" 1 "ButtonActivationResponse" 2 "PointingEventResponse" 18 "EndOfObjectPool" 32 "AuxiliaryAssignmentResponse" 146 "ESC" 160 "ShowHideObject" 161 "EnableDisableObject" 162 "SelectInputObject" 163 "ControlAudioDevice" 164 "SetAudioVolume" 165 "ChangeChildLocation" 166 "ChangeSize" 167 "ChangeBackgroundColour" 168 "ChangeNumericValue" 169 "ChangeEndPoint" 170 "ChangeFontAttributes" 171 "ChangeLineAttributes" 172 "ChangeFillAttributes" 173 "ChangeActiveMask" 174 "ChangeSoftKeyMask" 175 "ChangeAttribute" 176 "ChangePriority" 177 "ChangeListItem" 178 "DeleteObjectPool" 192 "GetMemory" 194 "GetNumberOfSoftKeys" 195 "GetTextFontData" 199 "GetHardware" 208 "StoreVersion" 209 "LoadVersion" 210 "DeleteVersion" 223 "GetVersions" 255 "WorkingSetMaintenance" 179 "ChangeStringValue" 3 "VTSelectInputObjectResponse" 4 "VTESCResponse" 5 "VTChangeNumericValueResponse" 6 "VTChangeActiveMaskResponse" 7 "VTChangeSoftKeyMaskResponse" 196 "GetWindowMaskData" 17 "ObjectPoolTransfer" 180 "ChangeChildPosition" 8 "VTChangeStringValueResponse" ;
VAL_ 3221225472 MaskType 1 "Data" 2 "Alarm" ;
VAL_ 3221225472 AuxCapabilitiesRequestType 1 "RequestCapabilitiesOfAuxFunctions" 0 "RequestCapabilitiesOfAuxiliaryInputs" ;
VAL_ 3221225472 OperationCode 36 "<=" 35 ">=" 34 "<" 33 ">" 32 "!=" 31 "==" 13 "--" 12 "++" 11 ">>=" 10 "<<=" 9 "|=" 8 "^=" 7 "&=" 6 "%=" 5 "/=" 4 "*=" 3 "-=" 2 "+=" 1 "=" 0 "Notification" ;
VAL_ 3221225472 RValueSelector 1 "RValueIsValueReferencedByObjectIDAndAID" 0 "RValueIsImmediateOperationValue " ;
VAL_ 3221225472 WSMaintenanceVersion 255 "CompliantWithVTVersion2AndPrior" 4 "CompliantWithVTVersion4" 3 "CompliantWithVTVersion3" ;
VAL_ 3221225472 AssignmentErrorNotAccepted 0 "AssignmentAccepted" 1 "AssignmentNotAccepted" ;
VAL_ 3221225472 ShowOrHide 0 "Hide" 1 "Show" ;
VAL_ 3221225472 EnableOrDisable 0 "Disable" 1 "Enable" ;
VAL_ 3221225472 TextOption 1 "Transparent" 0 "Opaque" ;
VAL_ 3221225472 EngRequestedTorqueHighResolution 7 "0875" 1 "0125" 0 "0000" 8 "1111  not available" ;
VAL_ 3221225472 TSC1CtrlPurpose 31 "P32  Temporary Power Train Control Original use of TSC1 Command" 5 "11110  P6P31  Reserved for SAE Assignment" 4 "P5  Engine Protection" 3 "P4  Road Speed Governor" 2 "P3  PTO Governor" 1 "P2  Cruise Control" 0 "P1  Accelerator Pedal/Operator Selection" ;
VAL_ 3221225472 TSC1TransRate 7 "Use standard TSC1 transmission rates of 10 ms to engine" 6 "20 ms transmission rate" 5 "50 ms transmission rate" 4 "100 ms transmission rate" 3 "250 ms transmission rate" 2 "500 ms transmission rate" 1 "750 ms transmission rate" 0 "1000 ms transmission rate" ;
VAL_ 3221225472 OverrideCtrlModePriority 3 "Low priority" 2 "Medium priority" 1 "High priority" 0 "Highest priority" ;
VAL_ 3221225472 EngRequestedSpeedCtrlConditions 2 "Stability Optimized for driveline engaged and/or in lockup condition 1 eg vehicle driveline" 3 "Stability Optimized for driveline engaged and/or in lockup condition 2 eg PTO driveline" 1 "Stability Optimized for driveline disengaged and nonlockup conditions" 0 "Transient Optimized for driveline disengaged and nonlockup conditions" ;
VAL_ 3221225472 EngOverrideCtrlMode 3 "Speed/torque limit control  Limit speed and/or torque based on the included limit values The speed limit governor is" 2 "Torque control  Control torque to the included desired torque value" 1 "Speed control  Govern speed to the included desired speed value" 0 "Override disabled  Disable any existing control commanded by the source of this command" ;
VAL_ 3221225472 TrackAdjustEnable 3 "Unavailable" 2 "Error" 1 "ON" 0 "OFF" ;
VAL_ 3221225472 JogSteerCommand 15 "UNAVAILABLE" 14 "Reserved" 13 "Reserved" 12 "Reserved" 11 "Reserved" 10 "Reserved" 9 "Reserved" 8 "Reserved" 7 "Reserved" 6 "Reserved" 5 "Reserved" 4 "Reserved" 3 "Clear Jog" 2 "Jog Right" 1 "Jog Left" 0 "NONE" ;
VAL_ 3221225472 RequestedSteerMode 15 "UNAVAILABLE" 14 "Reserved" 13 "Reserved" 12 "Reserved" 11 "Reserved" 10 "Reserved" 9 "Reserved" 8 "Reserved" 7 "Reserved" 6 "Reserved" 5 "Reserved" 4 "Crab Steer" 3 "4 Wheel Steer" 2 "Auto 4 Wheel Steer" 1 "2 Wheel Steer" 0 "OFF" ;
VAL_ 3221225472 ActualSteerMode 15 "UNAVAILABLE" 14 "Reserved" 13 "Reserved" 12 "Reserved" 11 "Reserved" 10 "Reserved" 9 "Reserved" 8 "Reserved" 7 "Reserved" 6 "Reserved" 5 "Reserved" 4 "Crab Steer" 3 "4 Wheel Steer" 2 "Auto 4 Wheel Steer" 1 "2 Wheel Steer" 0 "OFF" ;
VAL_ 3221225472 RearRightTrackOutButtonStatus 3 "Unavailable" 2 "Error" 1 "ON" 0 "OFF" ;
VAL_ 3221225472 RearRightTrackInButtonStatus 3 "Unavailable" 2 "Error" 1 "ON" 0 "OFF" ;
VAL_ 3221225472 RearLeftTrackOutButtonStatus 3 "Unavailable" 2 "Error" 1 "ON" 0 "OFF" ;
VAL_ 3221225472 RearLeftTrackInButtonStatus 3 "Unavailable" 2 "Error" 1 "ON" 0 "OFF" ;
VAL_ 3221225472 FrontRightTrackOutButtonStatus 3 "Unavailable" 2 "Error" 1 "ON" 0 "OFF" ;
VAL_ 3221225472 FrontRightTrackInButtonStatus 3 "Unavailable" 2 "Error" 1 "ON" 0 "OFF" ;
VAL_ 3221225472 FrontLeftTrackOutButtonStatus 3 "Unavailable" 2 "Error" 1 "ON" 0 "OFF" ;
VAL_ 3221225472 FrontLeftTrackInButtonStatus 3 "Unavailable" 2 "Error" 1 "ON" 0 "OFF" ;
VAL_ 2566838782 AuxI_O13 3 "Not available" 2 "Error" 1 "Auxiliary channel on" 0 "Auxiliary channel off" ;
VAL_ 2566838782 AuxI_O14 3 "Not available" 2 "Error" 1 "Auxiliary channel on" 0 "Auxiliary channel off" ;
VAL_ 2566838782 AuxI_O15 3 "Not available" 2 "Error" 1 "Auxiliary channel on" 0 "Auxiliary channel off" ;
VAL_ 2566838782 AuxI_O16 3 "Not available" 2 "Error" 1 "Auxiliary channel on" 0 "Auxiliary channel off" ;
VAL_ 2566838782 AuxI_O09 3 "Not available" 2 "Error" 1 "Auxiliary channel on" 0 "Auxiliary channel off" ;
VAL_ 2566838782 AuxI_O10 3 "Not available" 2 "Error" 1 "Auxiliary channel on" 0 "Auxiliary channel off" ;
VAL_ 2566838782 AuxI_O11 3 "Not available" 2 "Error" 1 "Auxiliary channel on" 0 "Auxiliary channel off" ;
VAL_ 2566838782 AuxI_O12 3 "Not available" 2 "Error" 1 "Auxiliary channel on" 0 "Auxiliary channel off" ;
VAL_ 2566838782 AuxI_O05 3 "Not available" 2 "Error" 1 "Auxiliary channel on" 0 "Auxiliary channel off" ;
VAL_ 2566838782 AuxI_O06 3 "Not available" 2 "Error" 1 "Auxiliary channel on" 0 "Auxiliary channel off" ;
VAL_ 2566838782 AuxI_O07 3 "Not available" 2 "Error" 1 "Auxiliary channel on" 0 "Auxiliary channel off" ;
VAL_ 2566838782 AuxI_O08 3 "Not available" 2 "Error" 1 "Auxiliary channel on" 0 "Auxiliary channel off" ;
VAL_ 2566838782 AuxI_O01 3 "Not available" 2 "Error" 1 "Auxiliary channel on" 0 "Auxiliary channel off" ;
VAL_ 2566838782 AuxI_O02 3 "Not available" 2 "Error" 1 "Auxiliary channel on" 0 "Auxiliary channel off" ;
VAL_ 2566838782 AuxI_O03 3 "Not available" 2 "Error" 1 "Auxiliary channel on" 0 "Auxiliary channel off" ;
VAL_ 2566838782 AuxI_O04 3 "Not available" 2 "Error" 1 "Auxiliary channel on" 0 "Auxiliary channel off" ;
VAL_ 2566862080 Engine_Shutdown_Pending 1 "Active" 0 "Not Active" ;
VAL_ 2566862080 Overheat_warning 1 "Active" 0 "Not Active" ;
VAL_ 2566862080 Oil_Service_Due 1 "Active" 0 "Not Active" ;
VAL_ 2566862080 Low_Oil_Pressure 1 "Active" 0 "Not Active" ;
VAL_ 2566862080 Engine_Overspeed_2800 1 "Active" 0 "Not Active" ;
VAL_ 2566862080 Injection_Quality_being_Reduced 1 "Active" 0 "Not Active" ;
VAL_ 2566862080 Engine_Standing_Still 1 "Active" 0 "Not Active" ;
VAL_ 2566862080 System_Error 1 "Active" 0 "Not Active" ;
VAL_ 2566878976 Audible_Warning 3 "Not Available" 2 "Reserved" 1 "OFF" 0 "ON" ;
VAL_ 2566878976 ATS_Malfunction_Lamp 3 "Not Available" 2 "ON - Fast blink (1Hz)" 1 "OFF" 0 "ON - Solid" ;
VAL_ 2566878976 DEF_Tank_Level_Lamp 3 "Not Available" 2 "ON - Fast blink (1Hz)" 1 "OFF" 0 "ON - Solid" ;
VAL_ 2565865272 ActualSteerMode 15 "UNAVAILABLE" 14 "Reserved" 13 "Reserved" 12 "Reserved" 11 "Reserved" 10 "Reserved" 9 "Reserved" 8 "Reserved" 7 "Reserved" 6 "Reserved" 5 "Reserved" 4 "Crab Steer" 3 "4 Wheel Steer" 2 "Auto 4 Wheel Steer" 1 "2 Wheel Steer" 0 "OFF" ;
VAL_ 2565865246 JogSteerCommand 15 "UNAVAILABLE" 14 "Reserved" 13 "Reserved" 12 "Reserved" 11 "Reserved" 10 "Reserved" 9 "Reserved" 8 "Reserved" 7 "Reserved" 6 "Reserved" 5 "Reserved" 4 "Reserved" 3 "Clear Jog" 2 "Jog Right" 1 "Jog Left" 0 "NONE" ;
VAL_ 2565865246 RequestedSteerMode 15 "UNAVAILABLE" 14 "Reserved" 13 "Reserved" 12 "Reserved" 11 "Reserved" 10 "Reserved" 9 "Reserved" 8 "Reserved" 7 "Reserved" 6 "Reserved" 5 "Reserved" 4 "Crab Steer" 3 "4 Wheel Steer" 2 "Auto 4 Wheel Steer" 1 "2 Wheel Steer" 0 "OFF" ;
VAL_ 2565865214 JogSteerCommand 15 "UNAVAILABLE" 14 "Reserved" 13 "Reserved" 12 "Reserved" 11 "Reserved" 10 "Reserved" 9 "Reserved" 8 "Reserved" 7 "Reserved" 6 "Reserved" 5 "Reserved" 4 "Reserved" 3 "Clear Jog" 2 "Jog Right" 1 "Jog Left" 0 "NONE" ;
VAL_ 2565865214 RequestedSteerMode 15 "UNAVAILABLE" 14 "Reserved" 13 "Reserved" 12 "Reserved" 11 "Reserved" 10 "Reserved" 9 "Reserved" 8 "Reserved" 7 "Reserved" 6 "Reserved" 5 "Reserved" 4 "Crab Steer" 3 "4 Wheel Steer" 2 "Auto 4 Wheel Steer" 1 "2 Wheel Steer" 0 "OFF" ;
VAL_ 2565865214 ActualSteerMode 15 "UNAVAILABLE" 14 "Reserved" 13 "Reserved" 12 "Reserved" 11 "Reserved" 10 "Reserved" 9 "Reserved" 8 "Reserved" 7 "Reserved" 6 "Reserved" 5 "Reserved" 4 "Crab Steer" 3 "4 Wheel Steer" 2 "Auto 4 Wheel Steer" 1 "2 Wheel Steer" 0 "OFF" ;
VAL_ 2559770366 HydrocarbonDoserPurgingNeeded 3 "Not available" 2 "Purging required  urgent" 1 "Purging required  less urgent" 0 "Purging not required" ;
VAL_ 2559770366 DiagnosticStatusOfHCDoser 7 "Not available" 6 "Error    System test has failed" 2 "101  SAE reserved" 1 "Internal system test is in process" 0 "System test has executed and passed or System test has not yet executed" ;
VAL_ 2559770366 HCDoserInjectingStatus 3 "Not available" 2 "Error" 1 "Injecting active" 0 "Injecting not active" ;
VAL_ 2559770366 HCDoserStatus 7 "Not available" 6 "Error" 5 "SAE reserved" 4 "SAE reserved" 3 "HC doser enabled waiting for regeneration" 2 "SAE reserved" 1 "HC doser active" 0 "HC doser disabled" ;
VAL_ 2559704830 LubricationTimingCycleCmd 3 "Take no action" 2 "Reserved" 1 "Enable" 0 "Pause" ;
VAL_ 2559704830 LubricationPumpEnableCmd 3 "Take no action" 2 "Reserved" 1 "Reset pump operation" 0 "No action Normal pump operation" ;
VAL_ 2559704830 LubricationOperationModeSetCmd 7 "Take no action" 4 "Test Mode  3" 3 "Test Mode  2" 2 "Test Mode  1" 1 "Manual Service Mode" 0 "Automatic Mode" ;
VAL_ 2559704830 LubricationCycleSetCmd 7 "No action" 3 "to 110  Reserved" 2 "Cycle mode  3 Highest Lubrication Frequency" 1 "Cycle mode  2" 0 "Cycle mode  1 Lowest Lubrication Frequency" ;
VAL_ 2559704830 LubricationCycleModeLockCmd 3 "No action" 2 "Reserved" 1 "Locked" 0 "Not Locked" ;
VAL_ 2559639294 SupplementalFanPowerHold 3 "Dont Care/Take no action" 2 "Reserved" 1 "Enable" 0 "Disable" ;
VAL_ 2559639294 SupplementalFanDirectionCmd 3 "Dont care/take no action leave function as is" 2 "Reserved" 1 "Reverse" 0 "Forward" ;
VAL_ 2559639294 SupplementalFanEnableCmd 3 "Dont Care/Take no action" 2 "Reserved" 1 "Enable" 0 "Disable" ;
VAL_ 2559573758 ClntLvlEngPrtctnShtdwnOvrrideCmd 3 "Dont care/take no action" 2 "Reserved" 1 "Enable engine protection shutdown override due to low coolant level" 0 "Disable engine protection shutdown override due to low coolant level" ;
VAL_ 2349530878 CruiseCtrlPauseCmd 3 "Dont care/take no action" 2 "Reserved" 1 "Cruise Control is not allowed" 0 "Cruise Control is allowed" ;
VAL_ 2349530878 CruiseCtrlResumeCmd 3 "Dont Care/take no action" 2 "Reserved" 1 "Cruise Control Resume Requested" 0 "Cruise Control Resume not Requested" ;
VAL_ 2349530878 CruiseCtrlDisableCmd 3 "Dont care/take no action" 2 "Reserved" 1 "Cruise Control is not allowed" 0 "Cruise Control is allowed" ;
VAL_ 2365428734 GenFrequencySelection 14 "Unknown" 13 "SAE Reserved" 12 "SAE Reserved" 11 "SAE Reserved" 10 "SAE Reserved" 9 "SAE Reserved" 8 "SAE Reserved" 7 "SAE Reserved" 6 "SAE Reserved" 5 "SAE Reserved" 4 "SAE Reserved" 3 "SAE Reserved" 2 "400 Hz" 1 "60 Hz" 0 "50 Hz" ;
VAL_ 2566705918 FlashProtectLamp 3 "Unavailable / Do Not Flash" 2 "Reserved" 1 "Fast Flash" 0 "Slow Flash" ;
VAL_ 2566705918 FlashAmberWarningLamp 3 "Unavailable / Do Not Flash" 2 "Reserved" 1 "Fast Flash" 0 "Slow Flash" ;
VAL_ 2566705918 FlashRedStopLamp 3 "Unavailable / Do Not Flash" 2 "Reserved" 1 "Fast Flash" 0 "Slow Flash" ;
VAL_ 2566705918 FlashMalfuncIndicatorLamp 3 "Unavailable / Do Not Flash" 2 "Reserved" 1 "Fast Flash" 0 "Slow Flash" ;
VAL_ 2566705918 ProtectLampStatus 3 "Not available" 2 "Reserved" 1 "Lamp on" 0 "Lamp off" ;
VAL_ 2566705918 AmberWarningLampStatus 3 "Not available" 2 "Reserved" 1 "Lamp on" 0 "Lamp off" ;
VAL_ 2566705918 RedStopLampState 3 "Not available" 2 "Reserved" 1 "Lamp on" 0 "Lamp off" ;
VAL_ 2566705918 MalfunctionIndicatorLampStatus 3 "Not available" 2 "Reserved" 1 "Lamp on" 0 "Lamp off" ;
VAL_ 2566705662 FlashProtectLamp 3 "Unavailable / Do Not Flash" 2 "Reserved" 1 "Fast Flash" 0 "Slow Flash" ;
VAL_ 2566705662 FlashAmberWarningLamp 3 "Unavailable / Do Not Flash" 2 "Reserved" 1 "Fast Flash" 0 "Slow Flash" ;
VAL_ 2566705662 FlashRedStopLamp 3 "Unavailable / Do Not Flash" 2 "Reserved" 1 "Fast Flash" 0 "Slow Flash" ;
VAL_ 2566705662 FlashMalfuncIndicatorLamp 3 "Unavailable / Do Not Flash" 2 "Reserved" 1 "Fast Flash" 0 "Slow Flash" ;
VAL_ 2566705662 ProtectLampStatus 3 "Not available" 2 "Reserved" 1 "Lamp on" 0 "Lamp off" ;
VAL_ 2566705662 AmberWarningLampStatus 3 "Not available" 2 "Reserved" 1 "Lamp on" 0 "Lamp off" ;
VAL_ 2566705662 RedStopLampState 3 "Not available" 2 "Reserved" 1 "Lamp on" 0 "Lamp off" ;
VAL_ 2566705662 MalfunctionIndicatorLampStatus 3 "Not available" 2 "Reserved" 1 "Lamp on" 0 "Lamp off" ;
VAL_ 2349465342 StaticRollAngleStatus 7 "Not available" 6 "Error" 5 "Reserved" 4 "Angle Data Invalid" 3 "Sensor Reboots" 2 "Sensor Defect" 1 "Sensor OK" 0 "Sensor Busy" ;
VAL_ 2559049470 DesiredEngFuelingState 3 "Dont care / Take no action" 2 "Parameter supported but no request" 1 "Fueling desired keep engine running" 0 "Fueling not desired shut off engine fueling" ;
SIG_VALTYPE_ 3221225472 ZoomValue : 1;
SIG_VALTYPE_ 3221225472 ZoomValue_PanZoom : 1;
